[part 2 of 2: package /STLACompositions/Platform_Lin]
AUTOSAR XML (schema 00044)
package /STLACompositions/Platform_Lin  (continued)
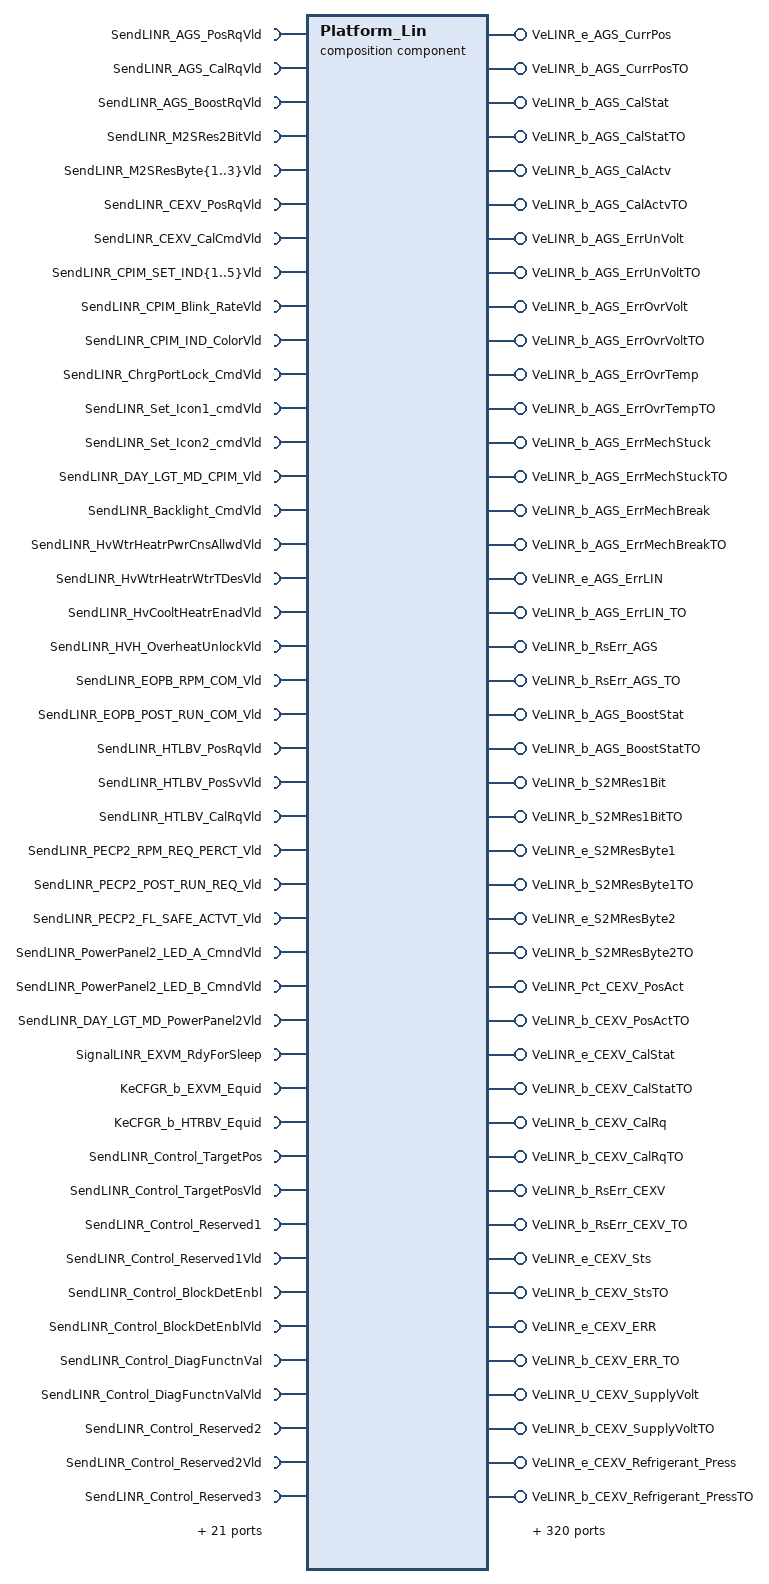
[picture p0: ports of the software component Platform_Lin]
  composition sw component type Platform_Lin: data-type-mapping=ADTtoIDTMapping  (continued)
    256 x provide port:
      VeLINR_e_AGS_CurrPos: nonqueued-sender-com-spec{data-element=VeLINR_e_AGS_CurrPos, init-value=VeLINR_e_AGS_CurrPosValue:0}, provided-interface=VeLINR_e_AGS_CurrPos
      VeLINR_b_AGS_CurrPosTO: nonqueued-sender-com-spec{data-element=VeLINR_b_AGS_CurrPosTO, init-value=VeLINR_b_AGS_CurrPosTOValue:0}, provided-interface=VeLINR_b_AGS_CurrPosTO
      VeLINR_b_AGS_CalStat: nonqueued-sender-com-spec{data-element=VeLINR_b_AGS_CalStat, init-value=VeLINR_b_AGS_CalStatValue:0}, provided-interface=VeLINR_b_AGS_CalStat
      VeLINR_b_AGS_CalStatTO: nonqueued-sender-com-spec{data-element=VeLINR_b_AGS_CalStatTO, init-value=VeLINR_b_AGS_CalStatTOValue:0}, provided-interface=VeLINR_b_AGS_CalStatTO
      VeLINR_b_AGS_CalActv: nonqueued-sender-com-spec{data-element=VeLINR_b_AGS_CalActv, init-value=VeLINR_b_AGS_CalActvValue:0}, provided-interface=VeLINR_b_AGS_CalActv
      VeLINR_b_AGS_CalActvTO: nonqueued-sender-com-spec{data-element=VeLINR_b_AGS_CalActvTO, init-value=VeLINR_b_AGS_CalActvTOValue:0}, provided-interface=VeLINR_b_AGS_CalActvTO
      VeLINR_b_AGS_ErrUnVolt: nonqueued-sender-com-spec{data-element=VeLINR_b_AGS_ErrUnVolt, init-value=VeLINR_b_AGS_ErrUnVoltValue:0}, provided-interface=VeLINR_b_AGS_ErrUnVolt
      VeLINR_b_AGS_ErrUnVoltTO: nonqueued-sender-com-spec{data-element=VeLINR_b_AGS_ErrUnVoltTO, init-value=VeLINR_b_AGS_ErrUnVoltTOValue:0}, provided-interface=VeLINR_b_AGS_ErrUnVoltTO
      VeLINR_b_AGS_ErrOvrVolt: nonqueued-sender-com-spec{data-element=VeLINR_b_AGS_ErrOvrVolt, init-value=VeLINR_b_AGS_ErrOvrVoltValue:0}, provided-interface=VeLINR_b_AGS_ErrOvrVolt
      VeLINR_b_AGS_ErrOvrVoltTO: nonqueued-sender-com-spec{data-element=VeLINR_b_AGS_ErrOvrVoltTO, init-value=VeLINR_b_AGS_ErrOvrVoltTOValue:0}, provided-interface=VeLINR_b_AGS_ErrOvrVoltTO
      VeLINR_b_AGS_ErrOvrTemp: nonqueued-sender-com-spec{data-element=VeLINR_b_AGS_ErrOvrTemp, init-value=VeLINR_b_AGS_ErrOvrTempValue:0}, provided-interface=VeLINR_b_AGS_ErrOvrTemp
      VeLINR_b_AGS_ErrOvrTempTO: nonqueued-sender-com-spec{data-element=VeLINR_b_AGS_ErrOvrTempTO, init-value=VeLINR_b_AGS_ErrOvrTempTOValue:0}, provided-interface=VeLINR_b_AGS_ErrOvrTempTO
      VeLINR_b_AGS_ErrMechStuck: nonqueued-sender-com-spec{data-element=VeLINR_b_AGS_ErrMechStuck, init-value=VeLINR_b_AGS_ErrMechStuckValue:0}, provided-interface=VeLINR_b_AGS_ErrMechStuck
      VeLINR_b_AGS_ErrMechStuckTO: nonqueued-sender-com-spec{data-element=VeLINR_b_AGS_ErrMechStuckTO, init-value=VeLINR_b_AGS_ErrMechStuckTOValue:0}, provided-interface=VeLINR_b_AGS_ErrMechStuckTO
      VeLINR_b_AGS_ErrMechBreak: nonqueued-sender-com-spec{data-element=VeLINR_b_AGS_ErrMechBreak, init-value=VeLINR_b_AGS_ErrMechBreakValue:0}, provided-interface=VeLINR_b_AGS_ErrMechBreak
      VeLINR_b_AGS_ErrMechBreakTO: nonqueued-sender-com-spec{data-element=VeLINR_b_AGS_ErrMechBreakTO, init-value=VeLINR_b_AGS_ErrMechBreakTOValue:0}, provided-interface=VeLINR_b_AGS_ErrMechBreakTO
      VeLINR_e_AGS_ErrLIN: nonqueued-sender-com-spec{data-element=VeLINR_e_AGS_ErrLIN, init-value=VeLINR_e_AGS_ErrLINValue:0}, provided-interface=VeLINR_e_AGS_ErrLIN
      VeLINR_b_AGS_ErrLIN_TO: nonqueued-sender-com-spec{data-element=VeLINR_b_AGS_ErrLIN_TO, init-value=VeLINR_b_AGS_ErrLIN_TOValue:0}, provided-interface=VeLINR_b_AGS_ErrLIN_TO
      VeLINR_b_RsErr_AGS: nonqueued-sender-com-spec{data-element=VeLINR_b_RsErr_AGS, init-value=VeLINR_b_RsErr_AGSValue:0}, provided-interface=VeLINR_b_RsErr_AGS
      VeLINR_b_RsErr_AGS_TO: nonqueued-sender-com-spec{data-element=VeLINR_b_RsErr_AGS_TO, init-value=VeLINR_b_RsErr_AGS_TOValue:0}, provided-interface=VeLINR_b_RsErr_AGS_TO
      VeLINR_b_AGS_BoostStat: nonqueued-sender-com-spec{data-element=VeLINR_b_AGS_BoostStat, init-value=VeLINR_b_AGS_BoostStatValue:0}, provided-interface=VeLINR_b_AGS_BoostStat
      VeLINR_b_AGS_BoostStatTO: nonqueued-sender-com-spec{data-element=VeLINR_b_AGS_BoostStatTO, init-value=VeLINR_b_AGS_BoostStatTOValue:0}, provided-interface=VeLINR_b_AGS_BoostStatTO
      VeLINR_b_S2MRes1Bit: nonqueued-sender-com-spec{data-element=VeLINR_b_S2MRes1Bit, init-value=VeLINR_b_S2MRes1BitValue:0}, provided-interface=VeLINR_b_S2MRes1Bit
      VeLINR_b_S2MRes1BitTO: nonqueued-sender-com-spec{data-element=VeLINR_b_S2MRes1BitTO, init-value=VeLINR_b_S2MRes1BitTOValue:0}, provided-interface=VeLINR_b_S2MRes1BitTO
      VeLINR_e_S2MResByte1: nonqueued-sender-com-spec{data-element=VeLINR_e_S2MResByte1, init-value=VeLINR_e_S2MResByte1Value:0}, provided-interface=VeLINR_e_S2MResByte1
      VeLINR_b_S2MResByte1TO: nonqueued-sender-com-spec{data-element=VeLINR_b_S2MResByte1TO, init-value=VeLINR_b_S2MResByte1TOValue:0}, provided-interface=VeLINR_b_S2MResByte1TO
      VeLINR_e_S2MResByte2: nonqueued-sender-com-spec{data-element=VeLINR_e_S2MResByte2, init-value=VeLINR_e_S2MResByte2Value:0}, provided-interface=VeLINR_e_S2MResByte2
      VeLINR_b_S2MResByte2TO: nonqueued-sender-com-spec{data-element=VeLINR_b_S2MResByte2TO, init-value=VeLINR_b_S2MResByte2TOValue:0}, provided-interface=VeLINR_b_S2MResByte2TO
      VeLINR_Pct_CEXV_PosAct: nonqueued-sender-com-spec{data-element=VeLINR_Pct_CEXV_PosAct, init-value=VeLINR_Pct_CEXV_PosActValue:0}, provided-interface=VeLINR_Pct_CEXV_PosAct
      VeLINR_b_CEXV_PosActTO: nonqueued-sender-com-spec{data-element=VeLINR_b_CEXV_PosActTO, init-value=VeLINR_b_CEXV_PosActTOValue:0}, provided-interface=VeLINR_b_CEXV_PosActTO
      VeLINR_e_CEXV_CalStat: nonqueued-sender-com-spec{data-element=VeLINR_e_CEXV_CalStat, init-value=VeLINR_e_CEXV_CalStatValue:0}, provided-interface=VeLINR_e_CEXV_CalStat
      VeLINR_b_CEXV_CalStatTO: nonqueued-sender-com-spec{data-element=VeLINR_b_CEXV_CalStatTO, init-value=VeLINR_b_CEXV_CalStatTOValue:0}, provided-interface=VeLINR_b_CEXV_CalStatTO
      VeLINR_b_CEXV_CalRq: nonqueued-sender-com-spec{data-element=VeLINR_b_CEXV_CalRq, init-value=VeLINR_b_CEXV_CalRqValue:0}, provided-interface=VeLINR_b_CEXV_CalRq
      VeLINR_b_CEXV_CalRqTO: nonqueued-sender-com-spec{data-element=VeLINR_b_CEXV_CalRqTO, init-value=VeLINR_b_CEXV_CalRqTOValue:0}, provided-interface=VeLINR_b_CEXV_CalRqTO
      VeLINR_b_RsErr_CEXV: nonqueued-sender-com-spec{data-element=VeLINR_b_RsErr_CEXV, init-value=VeLINR_b_RsErr_CEXVValue:0}, provided-interface=VeLINR_b_RsErr_CEXV
      VeLINR_b_RsErr_CEXV_TO: nonqueued-sender-com-spec{data-element=VeLINR_b_RsErr_CEXV_TO, init-value=VeLINR_b_RsErr_CEXV_TOValue:0}, provided-interface=VeLINR_b_RsErr_CEXV_TO
      VeLINR_e_CEXV_Sts: nonqueued-sender-com-spec{data-element=VeLINR_e_CEXV_Sts, init-value=VeLINR_e_CEXV_StsValue:0}, provided-interface=VeLINR_e_CEXV_Sts
      VeLINR_b_CEXV_StsTO: nonqueued-sender-com-spec{data-element=VeLINR_b_CEXV_StsTO, init-value=VeLINR_b_CEXV_StsTOValue:0}, provided-interface=VeLINR_b_CEXV_StsTO
      VeLINR_e_CEXV_ERR: nonqueued-sender-com-spec{data-element=VeLINR_e_CEXV_ERR, init-value=VeLINR_e_CEXV_ERRValue:0}, provided-interface=VeLINR_e_CEXV_ERR
      VeLINR_b_CEXV_ERR_TO: nonqueued-sender-com-spec{data-element=VeLINR_b_CEXV_ERR_TO, init-value=VeLINR_b_CEXV_ERR_TOValue:0}, provided-interface=VeLINR_b_CEXV_ERR_TO
      VeLINR_U_CEXV_SupplyVolt: nonqueued-sender-com-spec{data-element=VeLINR_U_CEXV_SupplyVolt, init-value=VeLINR_U_CEXV_SupplyVoltValue:0}, provided-interface=VeLINR_U_CEXV_SupplyVolt
      VeLINR_b_CEXV_SupplyVoltTO: nonqueued-sender-com-spec{data-element=VeLINR_b_CEXV_SupplyVoltTO, init-value=VeLINR_b_CEXV_SupplyVoltTOValue:0}, provided-interface=VeLINR_b_CEXV_SupplyVoltTO
      VeLINR_e_CEXV_Refrigerant_Press: nonqueued-sender-com-spec{data-element=VeLINR_e_CEXV_Refrigerant_Press, init-value=VeLINR_e_CEXV_Refrigerant_PressValue:1638.3}, provided-interface=VeLINR_e_CEXV_Refrigerant_Press
      VeLINR_b_CEXV_Refrigerant_PressTO: nonqueued-sender-com-spec{data-element=VeLINR_b_CEXV_Refrigerant_PressTO, init-value=VeLINR_b_CEXV_Refrigerant_PressTOValue:0}, provided-interface=VeLINR_b_CEXV_Refrigerant_PressTO
      VeLINR_T_CEXV_Board_Temp: nonqueued-sender-com-spec{data-element=VeLINR_T_CEXV_Board_Temp, init-value=VeLINR_T_CEXV_Board_TempValue:-40}, provided-interface=VeLINR_T_CEXV_Board_Temp
      VeLINR_b_CEXV_Board_TempTO: nonqueued-sender-com-spec{data-element=VeLINR_b_CEXV_Board_TempTO, init-value=VeLINR_b_CEXV_Board_TempTOValue:0}, provided-interface=VeLINR_b_CEXV_Board_TempTO
      VeLINR_e_CEXV_Refrigerant_Temp: nonqueued-sender-com-spec{data-element=VeLINR_e_CEXV_Refrigerant_Temp, init-value=VeLINR_e_CEXV_Refrigerant_TempValue:-40}, provided-interface=VeLINR_e_CEXV_Refrigerant_Temp
      VeLINR_b_CEXV_Refrigerant_TempTO: nonqueued-sender-com-spec{data-element=VeLINR_b_CEXV_Refrigerant_TempTO, init-value=VeLINR_b_CEXV_Refrigerant_TempTOValue:0}, provided-interface=VeLINR_b_CEXV_Refrigerant_TempTO
      VeLINR_e_Inlet_Temp1_DC: nonqueued-sender-com-spec{data-element=VeLINR_e_Inlet_Temp1_DC, init-value=VeLINR_e_Inlet_Temp1_DCValue:-40}, provided-interface=VeLINR_e_Inlet_Temp1_DC
      VeLINR_b_Inlet_Temp1_DC_TO: nonqueued-sender-com-spec{data-element=VeLINR_b_Inlet_Temp1_DC_TO, init-value=VeLINR_b_Inlet_Temp1_DC_TOValue:0}, provided-interface=VeLINR_b_Inlet_Temp1_DC_TO
      VeLINR_e_Inlet_Temp2_DC: nonqueued-sender-com-spec{data-element=VeLINR_e_Inlet_Temp2_DC, init-value=VeLINR_e_Inlet_Temp2_DCValue:-40}, provided-interface=VeLINR_e_Inlet_Temp2_DC
      VeLINR_b_Inlet_Temp2_DC_TO: nonqueued-sender-com-spec{data-element=VeLINR_b_Inlet_Temp2_DC_TO, init-value=VeLINR_b_Inlet_Temp2_DC_TOValue:0}, provided-interface=VeLINR_b_Inlet_Temp2_DC_TO
      VeLINR_e_CPIM_IND1_Fdbk: nonqueued-sender-com-spec{data-element=VeLINR_e_CPIM_IND1_Fdbk, init-value=VeLINR_e_CPIM_IND1_FdbkValue:0}, provided-interface=VeLINR_e_CPIM_IND1_Fdbk
      VeLINR_b_CPIM_IND1_FdbkTO: nonqueued-sender-com-spec{data-element=VeLINR_b_CPIM_IND1_FdbkTO, init-value=VeLINR_b_CPIM_IND1_FdbkTOValue:0}, provided-interface=VeLINR_b_CPIM_IND1_FdbkTO
      VeLINR_e_CPIM_IND2_Fdbk: nonqueued-sender-com-spec{data-element=VeLINR_e_CPIM_IND2_Fdbk, init-value=VeLINR_e_CPIM_IND2_FdbkValue:0}, provided-interface=VeLINR_e_CPIM_IND2_Fdbk
      VeLINR_b_CPIM_IND2_FdbkTO: nonqueued-sender-com-spec{data-element=VeLINR_b_CPIM_IND2_FdbkTO, init-value=VeLINR_b_CPIM_IND2_FdbkTOValue:0}, provided-interface=VeLINR_b_CPIM_IND2_FdbkTO
      VeLINR_e_CPIM_IND3_Fdbk: nonqueued-sender-com-spec{data-element=VeLINR_e_CPIM_IND3_Fdbk, init-value=VeLINR_e_CPIM_IND3_FdbkValue:0}, provided-interface=VeLINR_e_CPIM_IND3_Fdbk
      VeLINR_b_CPIM_IND3_FdbkTO: nonqueued-sender-com-spec{data-element=VeLINR_b_CPIM_IND3_FdbkTO, init-value=VeLINR_b_CPIM_IND3_FdbkTOValue:0}, provided-interface=VeLINR_b_CPIM_IND3_FdbkTO
      VeLINR_e_CPIM_IND4_Fdbk: nonqueued-sender-com-spec{data-element=VeLINR_e_CPIM_IND4_Fdbk, init-value=VeLINR_e_CPIM_IND4_FdbkValue:0}, provided-interface=VeLINR_e_CPIM_IND4_Fdbk
      VeLINR_b_CPIM_IND4_FdbkTO: nonqueued-sender-com-spec{data-element=VeLINR_b_CPIM_IND4_FdbkTO, init-value=VeLINR_b_CPIM_IND4_FdbkTOValue:0}, provided-interface=VeLINR_b_CPIM_IND4_FdbkTO
      VeLINR_e_CPIM_IND5_Fdbk: nonqueued-sender-com-spec{data-element=VeLINR_e_CPIM_IND5_Fdbk, init-value=VeLINR_e_CPIM_IND5_FdbkValue:0}, provided-interface=VeLINR_e_CPIM_IND5_Fdbk
      VeLINR_b_CPIM_IND5_FdbkTO: nonqueued-sender-com-spec{data-element=VeLINR_b_CPIM_IND5_FdbkTO, init-value=VeLINR_b_CPIM_IND5_FdbkTOValue:0}, provided-interface=VeLINR_b_CPIM_IND5_FdbkTO
      VeLINR_e_CPIM_IND_Color_Fdbk: nonqueued-sender-com-spec{data-element=VeLINR_e_CPIM_IND_Color_Fdbk, init-value=VeLINR_e_CPIM_IND_Color_FdbkValue:0}, provided-interface=VeLINR_e_CPIM_IND_Color_Fdbk
      VeLINR_b_CPIM_IND_Color_FdbkTO: nonqueued-sender-com-spec{data-element=VeLINR_b_CPIM_IND_Color_FdbkTO, init-value=VeLINR_b_CPIM_IND_Color_FdbkTOValue:0}, provided-interface=VeLINR_b_CPIM_IND_Color_FdbkTO
      VeLINR_e_CPIM_IND1_FailSts: nonqueued-sender-com-spec{data-element=VeLINR_e_CPIM_IND1_FailSts, init-value=VeLINR_e_CPIM_IND1_FailStsValue:0}, provided-interface=VeLINR_e_CPIM_IND1_FailSts
      VeLINR_b_CPIM_IND1_FailStsTO: nonqueued-sender-com-spec{data-element=VeLINR_b_CPIM_IND1_FailStsTO, init-value=VeLINR_b_CPIM_IND1_FailStsTOValue:0}, provided-interface=VeLINR_b_CPIM_IND1_FailStsTO
      VeLINR_e_CPIM_IND2_FailSts: nonqueued-sender-com-spec{data-element=VeLINR_e_CPIM_IND2_FailSts, init-value=VeLINR_e_CPIM_IND2_FailStsValue:0}, provided-interface=VeLINR_e_CPIM_IND2_FailSts
      VeLINR_b_CPIM_IND2_FailStsTO: nonqueued-sender-com-spec{data-element=VeLINR_b_CPIM_IND2_FailStsTO, init-value=VeLINR_b_CPIM_IND2_FailStsTOValue:0}, provided-interface=VeLINR_b_CPIM_IND2_FailStsTO
      VeLINR_e_CPIM_IND3_FailSts: nonqueued-sender-com-spec{data-element=VeLINR_e_CPIM_IND3_FailSts, init-value=VeLINR_e_CPIM_IND3_FailStsValue:0}, provided-interface=VeLINR_e_CPIM_IND3_FailSts
      VeLINR_b_CPIM_IND3_FailStsTO: nonqueued-sender-com-spec{data-element=VeLINR_b_CPIM_IND3_FailStsTO, init-value=VeLINR_b_CPIM_IND3_FailStsTOValue:0}, provided-interface=VeLINR_b_CPIM_IND3_FailStsTO
      VeLINR_e_CPIM_IND4_FailSts: nonqueued-sender-com-spec{data-element=VeLINR_e_CPIM_IND4_FailSts, init-value=VeLINR_e_CPIM_IND4_FailStsValue:0}, provided-interface=VeLINR_e_CPIM_IND4_FailSts
      VeLINR_b_CPIM_IND4_FailStsTO: nonqueued-sender-com-spec{data-element=VeLINR_b_CPIM_IND4_FailStsTO, init-value=VeLINR_b_CPIM_IND4_FailStsTOValue:0}, provided-interface=VeLINR_b_CPIM_IND4_FailStsTO
      VeLINR_e_CPIM_IND5_FailSts: nonqueued-sender-com-spec{data-element=VeLINR_e_CPIM_IND5_FailSts, init-value=VeLINR_e_CPIM_IND5_FailStsValue:0}, provided-interface=VeLINR_e_CPIM_IND5_FailSts
      VeLINR_b_CPIM_IND5_FailStsTO: nonqueued-sender-com-spec{data-element=VeLINR_b_CPIM_IND5_FailStsTO, init-value=VeLINR_b_CPIM_IND5_FailStsTOValue:0}, provided-interface=VeLINR_b_CPIM_IND5_FailStsTO
      VeLINR_b_CPIM_Undervoltage: nonqueued-sender-com-spec{data-element=VeLINR_b_CPIM_Undervoltage, init-value=VeLINR_b_CPIM_UndervoltageValue:0}, provided-interface=VeLINR_b_CPIM_Undervoltage
      VeLINR_b_CPIM_UndervoltageTO: nonqueued-sender-com-spec{data-element=VeLINR_b_CPIM_UndervoltageTO, init-value=VeLINR_b_CPIM_UndervoltageTOValue:0}, provided-interface=VeLINR_b_CPIM_UndervoltageTO
      VeLINR_b_CPIM_Over_Temperature: nonqueued-sender-com-spec{data-element=VeLINR_b_CPIM_Over_Temperature, init-value=VeLINR_b_CPIM_Over_TemperatureValue:0}, provided-interface=VeLINR_b_CPIM_Over_Temperature
      VeLINR_b_CPIM_Over_TemperatureTO: nonqueued-sender-com-spec{data-element=VeLINR_b_CPIM_Over_TemperatureTO, init-value=VeLINR_b_CPIM_Over_TemperatureTOValue:0}, provided-interface=VeLINR_b_CPIM_Over_TemperatureTO
      VeLINR_b_CPIM_LIN_Parity_Error: nonqueued-sender-com-spec{data-element=VeLINR_b_CPIM_LIN_Parity_Error, init-value=VeLINR_b_CPIM_LIN_Parity_ErrorValue:0}, provided-interface=VeLINR_b_CPIM_LIN_Parity_Error
      VeLINR_b_CPIM_LIN_Parity_ErrorTO: nonqueued-sender-com-spec{data-element=VeLINR_b_CPIM_LIN_Parity_ErrorTO, init-value=VeLINR_b_CPIM_LIN_Parity_ErrorTOValue:0}, provided-interface=VeLINR_b_CPIM_LIN_Parity_ErrorTO
      VeLINR_b_CPIM_LIN_ChecksumError: nonqueued-sender-com-spec{data-element=VeLINR_b_CPIM_LIN_ChecksumError, init-value=VeLINR_b_CPIM_LIN_ChecksumErrorValue:0}, provided-interface=VeLINR_b_CPIM_LIN_ChecksumError
      VeLINR_b_CPIM_LIN_ChecksumErrorTO: nonqueued-sender-com-spec{data-element=VeLINR_b_CPIM_LIN_ChecksumErrorTO, init-value=VeLINR_b_CPIM_LIN_ChecksumErrorTOValue:0}, provided-interface=VeLINR_b_CPIM_LIN_ChecksumErrorTO
      VeLINR_b_CPIM_LIN_Data_Error: nonqueued-sender-com-spec{data-element=VeLINR_b_CPIM_LIN_Data_Error, init-value=VeLINR_b_CPIM_LIN_Data_ErrorValue:0}, provided-interface=VeLINR_b_CPIM_LIN_Data_Error
      VeLINR_b_CPIM_LIN_Data_ErrorTO: nonqueued-sender-com-spec{data-element=VeLINR_b_CPIM_LIN_Data_ErrorTO, init-value=VeLINR_b_CPIM_LIN_Data_ErrorTOValue:0}, provided-interface=VeLINR_b_CPIM_LIN_Data_ErrorTO
      VeLINR_b_ChrgPortLock_Sts: nonqueued-sender-com-spec{data-element=VeLINR_b_ChrgPortLock_Sts, init-value=VeLINR_b_ChrgPortLock_StsValue:0}, provided-interface=VeLINR_b_ChrgPortLock_Sts
      VeLINR_b_ChrgPortLock_StsTO: nonqueued-sender-com-spec{data-element=VeLINR_b_ChrgPortLock_StsTO, init-value=VeLINR_b_ChrgPortLock_StsTOValue:0}, provided-interface=VeLINR_b_ChrgPortLock_StsTO
      VeLINR_b_ChrgPortButton_Sts: nonqueued-sender-com-spec{data-element=VeLINR_b_ChrgPortButton_Sts, init-value=VeLINR_b_ChrgPortButton_StsValue:0}, provided-interface=VeLINR_b_ChrgPortButton_Sts
      VeLINR_b_ChrgPortButton_StsTO: nonqueued-sender-com-spec{data-element=VeLINR_b_ChrgPortButton_StsTO, init-value=VeLINR_b_ChrgPortButton_StsTOValue:0}, provided-interface=VeLINR_b_ChrgPortButton_StsTO
      VeLINR_e_Ambient_Temp: nonqueued-sender-com-spec{data-element=VeLINR_e_Ambient_Temp, init-value=VeLINR_e_Ambient_TempValue:-40}, provided-interface=VeLINR_e_Ambient_Temp
      VeLINR_b_Ambient_TempTO: nonqueued-sender-com-spec{data-element=VeLINR_b_Ambient_TempTO, init-value=VeLINR_b_Ambient_TempTOValue:0}, provided-interface=VeLINR_b_Ambient_TempTO
      VeLINR_e_Chrg_Inlet_Temp: nonqueued-sender-com-spec{data-element=VeLINR_e_Chrg_Inlet_Temp, init-value=VeLINR_e_Chrg_Inlet_TempValue:-40}, provided-interface=VeLINR_e_Chrg_Inlet_Temp
      VeLINR_b_Chrg_Inlet_TempTO: nonqueued-sender-com-spec{data-element=VeLINR_b_Chrg_Inlet_TempTO, init-value=VeLINR_b_Chrg_Inlet_TempTOValue:0}, provided-interface=VeLINR_b_Chrg_Inlet_TempTO
      VeLINR_b_ResponseErrorStsCPIM: nonqueued-sender-com-spec{data-element=VeLINR_b_ResponseErrorStsCPIM, init-value=VeLINR_b_ResponseErrorStsCPIMValue:0}, provided-interface=VeLINR_b_ResponseErrorStsCPIM
      VeLINR_b_ResponseErrorStsCPIM_TO: nonqueued-sender-com-spec{data-element=VeLINR_b_ResponseErrorStsCPIM_TO, init-value=VeLINR_b_ResponseErrorStsCPIM_TOValue:0}, provided-interface=VeLINR_b_ResponseErrorStsCPIM_TO
      VeLINR_e_ChrgPortLock_FailSts: nonqueued-sender-com-spec{data-element=VeLINR_e_ChrgPortLock_FailSts, init-value=VeLINR_e_ChrgPortLock_FailStsValue:0}, provided-interface=VeLINR_e_ChrgPortLock_FailSts
      VeLINR_b_ChrgPortLock_FailStsTO: nonqueued-sender-com-spec{data-element=VeLINR_b_ChrgPortLock_FailStsTO, init-value=VeLINR_b_ChrgPortLock_FailStsTOValue:0}, provided-interface=VeLINR_b_ChrgPortLock_FailStsTO
      VeLINR_e_Icon1_Sts: nonqueued-sender-com-spec{data-element=VeLINR_e_Icon1_Sts, init-value=VeLINR_e_Icon1_StsValue:0}, provided-interface=VeLINR_e_Icon1_Sts
      VeLINR_b_Icon1_StsTO: nonqueued-sender-com-spec{data-element=VeLINR_b_Icon1_StsTO, init-value=VeLINR_b_Icon1_StsTOValue:0}, provided-interface=VeLINR_b_Icon1_StsTO
      VeLINR_b_Icon1_FailSts: nonqueued-sender-com-spec{data-element=VeLINR_b_Icon1_FailSts, init-value=VeLINR_b_Icon1_FailStsValue:0}, provided-interface=VeLINR_b_Icon1_FailSts
      VeLINR_b_Icon1_FailStsTO: nonqueued-sender-com-spec{data-element=VeLINR_b_Icon1_FailStsTO, init-value=VeLINR_b_Icon1_FailStsTOValue:0}, provided-interface=VeLINR_b_Icon1_FailStsTO
      VeLINR_e_Icon2_Sts: nonqueued-sender-com-spec{data-element=VeLINR_e_Icon2_Sts, init-value=VeLINR_e_Icon2_StsValue:0}, provided-interface=VeLINR_e_Icon2_Sts
      VeLINR_b_Icon2_StsTO: nonqueued-sender-com-spec{data-element=VeLINR_b_Icon2_StsTO, init-value=VeLINR_b_Icon2_StsTOValue:0}, provided-interface=VeLINR_b_Icon2_StsTO
      VeLINR_b_Icon2_FailSts: nonqueued-sender-com-spec{data-element=VeLINR_b_Icon2_FailSts, init-value=VeLINR_b_Icon2_FailStsValue:0}, provided-interface=VeLINR_b_Icon2_FailSts
      VeLINR_b_Icon2_FailStsTO: nonqueued-sender-com-spec{data-element=VeLINR_b_Icon2_FailStsTO, init-value=VeLINR_b_Icon2_FailStsTOValue:0}, provided-interface=VeLINR_b_Icon2_FailStsTO
      VeLINR_e_ChrgPortDoor_Sts: nonqueued-sender-com-spec{data-element=VeLINR_e_ChrgPortDoor_Sts, init-value=VeLINR_e_ChrgPortDoor_StsValue:0}, provided-interface=VeLINR_e_ChrgPortDoor_Sts
      VeLINR_b_ChrgPortDoor_StsTO: nonqueued-sender-com-spec{data-element=VeLINR_b_ChrgPortDoor_StsTO, init-value=VeLINR_b_ChrgPortDoor_StsTOValue:0}, provided-interface=VeLINR_b_ChrgPortDoor_StsTO
      VeLINR_e_HvCooltHeatrSts: nonqueued-sender-com-spec{data-element=VeLINR_e_HvCooltHeatrSts, init-value=VeLINR_e_HvCooltHeatrStsValue:0}, provided-interface=VeLINR_e_HvCooltHeatrSts
      VeLINR_b_HvCooltHeatrStsTO: nonqueued-sender-com-spec{data-element=VeLINR_b_HvCooltHeatrStsTO, init-value=VeLINR_b_HvCooltHeatrStsTOValue:0}, provided-interface=VeLINR_b_HvCooltHeatrStsTO
      VeLINR_e_ECH_InterlockStat: nonqueued-sender-com-spec{data-element=VeLINR_e_ECH_InterlockStat, init-value=VeLINR_e_ECH_InterlockStatValue:0}, provided-interface=VeLINR_e_ECH_InterlockStat
      VeLINR_b_ECH_InterlockStatTO: nonqueued-sender-com-spec{data-element=VeLINR_b_ECH_InterlockStatTO, init-value=VeLINR_b_ECH_InterlockStatTOValue:0}, provided-interface=VeLINR_b_ECH_InterlockStatTO
      VeLINR_e_Below_60V: nonqueued-sender-com-spec{data-element=VeLINR_e_Below_60V, init-value=VeLINR_e_Below_60VValue:3}, provided-interface=VeLINR_e_Below_60V
      VeLINR_b_Below_60V_TO: nonqueued-sender-com-spec{data-element=VeLINR_b_Below_60V_TO, init-value=VeLINR_b_Below_60V_TOValue:0}, provided-interface=VeLINR_b_Below_60V_TO
      VeLINR_T_HvCltWtrHtrWtrTInIntk: nonqueued-sender-com-spec{data-element=VeLINR_T_HvCltWtrHtrWtrTInIntk, init-value=VeLINR_T_HvCltWtrHtrWtrTInIntkValue:215}, provided-interface=VeLINR_T_HvCltWtrHtrWtrTInIntk
      VeLINR_b_HvCltWtrHtrWtrTInIntkTO: nonqueued-sender-com-spec{data-element=VeLINR_b_HvCltWtrHtrWtrTInIntkTO, init-value=VeLINR_b_HvCltWtrHtrWtrTInIntkTOValue:0}, provided-interface=VeLINR_b_HvCltWtrHtrWtrTInIntkTO
      VeLINR_T_HvWtrHeatrWtrT: nonqueued-sender-com-spec{data-element=VeLINR_T_HvWtrHeatrWtrT, init-value=VeLINR_T_HvWtrHeatrWtrTValue:215}, provided-interface=VeLINR_T_HvWtrHeatrWtrT
      VeLINR_b_HvWtrHeatrWtrT_TO: nonqueued-sender-com-spec{data-element=VeLINR_b_HvWtrHeatrWtrT_TO, init-value=VeLINR_b_HvWtrHeatrWtrT_TOValue:0}, provided-interface=VeLINR_b_HvWtrHeatrWtrT_TO
      VeLINR_I_HvCooltHeatrICns: nonqueued-sender-com-spec{data-element=VeLINR_I_HvCooltHeatrICns, init-value=VeLINR_I_HvCooltHeatrICnsValue:63.75}, provided-interface=VeLINR_I_HvCooltHeatrICns
      VeLINR_b_HvCooltHeatrICnsTO: nonqueued-sender-com-spec{data-element=VeLINR_b_HvCooltHeatrICnsTO, init-value=VeLINR_b_HvCooltHeatrICnsTOValue:0}, provided-interface=VeLINR_b_HvCooltHeatrICnsTO
      VeLINR_U_HvCooltHVmeas: nonqueued-sender-com-spec{data-element=VeLINR_U_HvCooltHVmeas, init-value=VeLINR_U_HvCooltHVmeasValue:1023}, provided-interface=VeLINR_U_HvCooltHVmeas
      VeLINR_b_HvCooltHVmeasTO: nonqueued-sender-com-spec{data-element=VeLINR_b_HvCooltHVmeasTO, init-value=VeLINR_b_HvCooltHVmeasTOValue:0}, provided-interface=VeLINR_b_HvCooltHVmeasTO
      VeLINR_P_HvHeatrPwrCns: nonqueued-sender-com-spec{data-element=VeLINR_P_HvHeatrPwrCns, init-value=VeLINR_P_HvHeatrPwrCnsValue:20460}, provided-interface=VeLINR_P_HvHeatrPwrCns
      VeLINR_b_HvHeatrPwrCnsTO: nonqueued-sender-com-spec{data-element=VeLINR_b_HvHeatrPwrCnsTO, init-value=VeLINR_b_HvHeatrPwrCnsTOValue:0}, provided-interface=VeLINR_b_HvHeatrPwrCnsTO
      VeLINR_P_HvHeatrPwrCnsDes: nonqueued-sender-com-spec{data-element=VeLINR_P_HvHeatrPwrCnsDes, init-value=VeLINR_P_HvHeatrPwrCnsDesValue:20460}, provided-interface=VeLINR_P_HvHeatrPwrCnsDes
      VeLINR_b_HvHeatrPwrCnsDesTO: nonqueued-sender-com-spec{data-element=VeLINR_b_HvHeatrPwrCnsDesTO, init-value=VeLINR_b_HvHeatrPwrCnsDesTOValue:0}, provided-interface=VeLINR_b_HvHeatrPwrCnsDesTO
      VeLINR_e_HVH_UnlockCounter: nonqueued-sender-com-spec{data-element=VeLINR_e_HVH_UnlockCounter, init-value=VeLINR_e_HVH_UnlockCounterValue:0}, provided-interface=VeLINR_e_HVH_UnlockCounter
      VeLINR_b_HVH_UnlockCounterTO: nonqueued-sender-com-spec{data-element=VeLINR_b_HVH_UnlockCounterTO, init-value=VeLINR_b_HVH_UnlockCounterTOValue:0}, provided-interface=VeLINR_b_HVH_UnlockCounterTO
      VeLINR_b_RsErr_ECH: nonqueued-sender-com-spec{data-element=VeLINR_b_RsErr_ECH, init-value=VeLINR_b_RsErr_ECHValue:0}, provided-interface=VeLINR_b_RsErr_ECH
      VeLINR_b_RsErr_ECH_TO: nonqueued-sender-com-spec{data-element=VeLINR_b_RsErr_ECH_TO, init-value=VeLINR_b_RsErr_ECH_TOValue:0}, provided-interface=VeLINR_b_RsErr_ECH_TO
      VeLINR_e_HvCltHtrWrnFltInCom: nonqueued-sender-com-spec{data-element=VeLINR_e_HvCltHtrWrnFltInCom, init-value=VeLINR_e_HvCltHtrWrnFltInComValue:3}, provided-interface=VeLINR_e_HvCltHtrWrnFltInCom
      VeLINR_b_HvCltHtrWrnFltInComTO: nonqueued-sender-com-spec{data-element=VeLINR_b_HvCltHtrWrnFltInComTO, init-value=VeLINR_b_HvCltHtrWrnFltInComTOValue:0}, provided-interface=VeLINR_b_HvCltHtrWrnFltInComTO
      VeLINR_e_HvCltHtrWrnHvOtOfRng: nonqueued-sender-com-spec{data-element=VeLINR_e_HvCltHtrWrnHvOtOfRng, init-value=VeLINR_e_HvCltHtrWrnHvOtOfRngValue:3}, provided-interface=VeLINR_e_HvCltHtrWrnHvOtOfRng
      VeLINR_b_HvCltHtrWrnHvOtOfRngTO: nonqueued-sender-com-spec{data-element=VeLINR_b_HvCltHtrWrnHvOtOfRngTO, init-value=VeLINR_b_HvCltHtrWrnHvOtOfRngTOValue:0}, provided-interface=VeLINR_b_HvCltHtrWrnHvOtOfRngTO
      VeLINR_e_HvCltHtrWrnULoOtOfRng: nonqueued-sender-com-spec{data-element=VeLINR_e_HvCltHtrWrnULoOtOfRng, init-value=VeLINR_e_HvCltHtrWrnULoOtOfRngValue:3}, provided-interface=VeLINR_e_HvCltHtrWrnULoOtOfRng
      VeLINR_b_HvCltHtrWrnULoOtOfRngTO: nonqueued-sender-com-spec{data-element=VeLINR_b_HvCltHtrWrnULoOtOfRngTO, init-value=VeLINR_b_HvCltHtrWrnULoOtOfRngTOValue:0}, provided-interface=VeLINR_b_HvCltHtrWrnULoOtOfRngTO
      VeLINR_e_HvCltHtrWrnCltTOtOfRng: nonqueued-sender-com-spec{data-element=VeLINR_e_HvCltHtrWrnCltTOtOfRng, init-value=VeLINR_e_HvCltHtrWrnCltTOtOfRngValue:3}, provided-interface=VeLINR_e_HvCltHtrWrnCltTOtOfRng
      VeLINR_b_HvCltHtrWrnCltTOtOfRngTO: nonqueued-sender-com-spec{data-element=VeLINR_b_HvCltHtrWrnCltTOtOfRngTO, init-value=VeLINR_b_HvCltHtrWrnCltTOtOfRngTOValue:0}, provided-interface=VeLINR_b_HvCltHtrWrnCltTOtOfRngTO
      VeLINR_e_HvCltHrPrtnSfTmpHwPrtn: nonqueued-sender-com-spec{data-element=VeLINR_e_HvCltHrPrtnSfTmpHwPrtn, init-value=VeLINR_e_HvCltHrPrtnSfTmpHwPrtnValue:3}, provided-interface=VeLINR_e_HvCltHrPrtnSfTmpHwPrtn
      VeLINR_b_HvCltHrPrtnSfTmpHwPrtnTO: nonqueued-sender-com-spec{data-element=VeLINR_b_HvCltHrPrtnSfTmpHwPrtnTO, init-value=VeLINR_b_HvCltHrPrtnSfTmpHwPrtnTOValue:0}, provided-interface=VeLINR_b_HvCltHrPrtnSfTmpHwPrtnTO
      VeLINR_e_HvCltHrPrtnSfTmpOvrhtg: nonqueued-sender-com-spec{data-element=VeLINR_e_HvCltHrPrtnSfTmpOvrhtg, init-value=VeLINR_e_HvCltHrPrtnSfTmpOvrhtgValue:3}, provided-interface=VeLINR_e_HvCltHrPrtnSfTmpOvrhtg
      VeLINR_b_HvCltHrPrtnSfTmpOvrhtgTO: nonqueued-sender-com-spec{data-element=VeLINR_b_HvCltHrPrtnSfTmpOvrhtgTO, init-value=VeLINR_b_HvCltHrPrtnSfTmpOvrhtgTOValue:0}, provided-interface=VeLINR_b_HvCltHrPrtnSfTmpOvrhtgTO
      VeLINR_e_HClHrSrFtClTInSnFlt: nonqueued-sender-com-spec{data-element=VeLINR_e_HClHrSrFtClTInSnFlt, init-value=VeLINR_e_HClHrSrFtClTInSnFltValue:3}, provided-interface=VeLINR_e_HClHrSrFtClTInSnFlt
      VeLINR_b_HClHrSrFtClTInSnFltTO: nonqueued-sender-com-spec{data-element=VeLINR_b_HClHrSrFtClTInSnFltTO, init-value=VeLINR_b_HClHrSrFtClTInSnFltTOValue:0}, provided-interface=VeLINR_b_HClHrSrFtClTInSnFltTO
      VeLINR_e_HClHrSrFtClTOtSnFlt: nonqueued-sender-com-spec{data-element=VeLINR_e_HClHrSrFtClTOtSnFlt, init-value=VeLINR_e_HClHrSrFtClTOtSnFltValue:3}, provided-interface=VeLINR_e_HClHrSrFtClTOtSnFlt
      VeLINR_b_HClHrSrFtClTOtSnFltTO: nonqueued-sender-com-spec{data-element=VeLINR_b_HClHrSrFtClTOtSnFltTO, init-value=VeLINR_b_HClHrSrFtClTOtSnFltTOValue:0}, provided-interface=VeLINR_b_HClHrSrFtClTOtSnFltTO
      VeLINR_e_HClHrSrFtTInMtrlSnFlt: nonqueued-sender-com-spec{data-element=VeLINR_e_HClHrSrFtTInMtrlSnFlt, init-value=VeLINR_e_HClHrSrFtTInMtrlSnFltValue:3}, provided-interface=VeLINR_e_HClHrSrFtTInMtrlSnFlt
      VeLINR_b_HClHrSrFtTInMtrlSnFltTO: nonqueued-sender-com-spec{data-element=VeLINR_b_HClHrSrFtTInMtrlSnFltTO, init-value=VeLINR_b_HClHrSrFtTInMtrlSnFltTOValue:0}, provided-interface=VeLINR_b_HClHrSrFtTInMtrlSnFltTO
      VeLINR_e_HClHrSrRqCrFrDrShOrOp: nonqueued-sender-com-spec{data-element=VeLINR_e_HClHrSrRqCrFrDrShOrOp, init-value=VeLINR_e_HClHrSrRqCrFrDrShOrOpValue:3}, provided-interface=VeLINR_e_HClHrSrRqCrFrDrShOrOp
      VeLINR_b_HClHrSrRqCrFrDrShOrOpTO: nonqueued-sender-com-spec{data-element=VeLINR_b_HClHrSrRqCrFrDrShOrOpTO, init-value=VeLINR_b_HClHrSrRqCrFrDrShOrOpTOValue:0}, provided-interface=VeLINR_b_HClHrSrRqCrFrDrShOrOpTO
      VeLINR_e_HClHrSrRqICnsOtOfRng: nonqueued-sender-com-spec{data-element=VeLINR_e_HClHrSrRqICnsOtOfRng, init-value=VeLINR_e_HClHrSrRqICnsOtOfRngValue:3}, provided-interface=VeLINR_e_HClHrSrRqICnsOtOfRng
      VeLINR_b_HClHrSrRqICnsOtOfRngTO: nonqueued-sender-com-spec{data-element=VeLINR_b_HClHrSrRqICnsOtOfRngTO, init-value=VeLINR_b_HClHrSrRqICnsOtOfRngTOValue:0}, provided-interface=VeLINR_b_HClHrSrRqICnsOtOfRngTO
      VeLINR_e_HClHrSrRqMemErr: nonqueued-sender-com-spec{data-element=VeLINR_e_HClHrSrRqMemErr, init-value=VeLINR_e_HClHrSrRqMemErrValue:3}, provided-interface=VeLINR_e_HClHrSrRqMemErr
      VeLINR_b_HClHrSrRqMemErrTO: nonqueued-sender-com-spec{data-element=VeLINR_b_HClHrSrRqMemErrTO, init-value=VeLINR_b_HClHrSrRqMemErrTOValue:0}, provided-interface=VeLINR_b_HClHrSrRqMemErrTO
      VeLINR_e_HClHrSrRqSrvRq: nonqueued-sender-com-spec{data-element=VeLINR_e_HClHrSrRqSrvRq, init-value=VeLINR_e_HClHrSrRqSrvRqValue:3}, provided-interface=VeLINR_e_HClHrSrRqSrvRq
      VeLINR_b_HClHrSrRqSrvRqTO: nonqueued-sender-com-spec{data-element=VeLINR_b_HClHrSrRqSrvRqTO, init-value=VeLINR_b_HClHrSrRqSrvRqTOValue:0}, provided-interface=VeLINR_b_HClHrSrRqSrvRqTO
      VeLINR_e_EOPB_RPM_TGT: nonqueued-sender-com-spec{data-element=VeLINR_e_EOPB_RPM_TGT, init-value=VeLINR_e_EOPB_RPM_TGTValue:6120}, provided-interface=VeLINR_e_EOPB_RPM_TGT
      VeLINR_b_EOPB_RPM_TGT_TO: nonqueued-sender-com-spec{data-element=VeLINR_b_EOPB_RPM_TGT_TO, init-value=VeLINR_b_EOPB_RPM_TGT_TOValue:0}, provided-interface=VeLINR_b_EOPB_RPM_TGT_TO
      VeLINR_e_EOPB_RPM_ACTL: nonqueued-sender-com-spec{data-element=VeLINR_e_EOPB_RPM_ACTL, init-value=VeLINR_e_EOPB_RPM_ACTLValue:6120}, provided-interface=VeLINR_e_EOPB_RPM_ACTL
      VeLINR_b_EOPB_RPM_ACTL_TO: nonqueued-sender-com-spec{data-element=VeLINR_b_EOPB_RPM_ACTL_TO, init-value=VeLINR_b_EOPB_RPM_ACTL_TOValue:0}, provided-interface=VeLINR_b_EOPB_RPM_ACTL_TO
      VeLINR_U_EOPB_VLTG: nonqueued-sender-com-spec{data-element=VeLINR_U_EOPB_VLTG, init-value=VeLINR_U_EOPB_VLTGValue:25.5}, provided-interface=VeLINR_U_EOPB_VLTG
      VeLINR_b_EOPB_VLTG_TO: nonqueued-sender-com-spec{data-element=VeLINR_b_EOPB_VLTG_TO, init-value=VeLINR_b_EOPB_VLTG_TOValue:0}, provided-interface=VeLINR_b_EOPB_VLTG_TO
      VeLINR_T_EOPB_TEMP: nonqueued-sender-com-spec{data-element=VeLINR_T_EOPB_TEMP, init-value=VeLINR_T_EOPB_TEMPValue:205}, provided-interface=VeLINR_T_EOPB_TEMP
      VeLINR_b_EOPB_TEMP_TO: nonqueued-sender-com-spec{data-element=VeLINR_b_EOPB_TEMP_TO, init-value=VeLINR_b_EOPB_TEMP_TOValue:0}, provided-interface=VeLINR_b_EOPB_TEMP_TO
      VeLINR_I_EOPB_CURR: nonqueued-sender-com-spec{data-element=VeLINR_I_EOPB_CURR, init-value=VeLINR_I_EOPB_CURRValue:51}, provided-interface=VeLINR_I_EOPB_CURR
      VeLINR_b_EOPB_CURR_TO: nonqueued-sender-com-spec{data-element=VeLINR_b_EOPB_CURR_TO, init-value=VeLINR_b_EOPB_CURR_TOValue:0}, provided-interface=VeLINR_b_EOPB_CURR_TO
      VeLINR_e_EOPB_LOW_TMP_STAT: nonqueued-sender-com-spec{data-element=VeLINR_e_EOPB_LOW_TMP_STAT, init-value=VeLINR_e_EOPB_LOW_TMP_STATValue:3}, provided-interface=VeLINR_e_EOPB_LOW_TMP_STAT
      VeLINR_b_EOPB_LOW_TMP_STAT_TO: nonqueued-sender-com-spec{data-element=VeLINR_b_EOPB_LOW_TMP_STAT_TO, init-value=VeLINR_b_EOPB_LOW_TMP_STAT_TOValue:0}, provided-interface=VeLINR_b_EOPB_LOW_TMP_STAT_TO
      VeLINR_e_EOPB_MONTRNG_RPM: nonqueued-sender-com-spec{data-element=VeLINR_e_EOPB_MONTRNG_RPM, init-value=VeLINR_e_EOPB_MONTRNG_RPMValue:3}, provided-interface=VeLINR_e_EOPB_MONTRNG_RPM
      VeLINR_b_EOPB_MONTRNG_RPM_TO: nonqueued-sender-com-spec{data-element=VeLINR_b_EOPB_MONTRNG_RPM_TO, init-value=VeLINR_b_EOPB_MONTRNG_RPM_TOValue:0}, provided-interface=VeLINR_b_EOPB_MONTRNG_RPM_TO
      VeLINR_e_EOPB_LMP_HM_AN_ON: nonqueued-sender-com-spec{data-element=VeLINR_e_EOPB_LMP_HM_AN_ON, init-value=VeLINR_e_EOPB_LMP_HM_AN_ONValue:3}, provided-interface=VeLINR_e_EOPB_LMP_HM_AN_ON
      VeLINR_b_EOPB_LMP_HM_AN_ON_TO: nonqueued-sender-com-spec{data-element=VeLINR_b_EOPB_LMP_HM_AN_ON_TO, init-value=VeLINR_b_EOPB_LMP_HM_AN_ON_TOValue:0}, provided-interface=VeLINR_b_EOPB_LMP_HM_AN_ON_TO
      VeLINR_e_EOPB_OV_TMP_ER: nonqueued-sender-com-spec{data-element=VeLINR_e_EOPB_OV_TMP_ER, init-value=VeLINR_e_EOPB_OV_TMP_ERValue:3}, provided-interface=VeLINR_e_EOPB_OV_TMP_ER
      VeLINR_b_EOPB_OV_TMP_ER_TO: nonqueued-sender-com-spec{data-element=VeLINR_b_EOPB_OV_TMP_ER_TO, init-value=VeLINR_b_EOPB_OV_TMP_ER_TOValue:0}, provided-interface=VeLINR_b_EOPB_OV_TMP_ER_TO
      VeLINR_e_EOPB_OV_CUR_ER: nonqueued-sender-com-spec{data-element=VeLINR_e_EOPB_OV_CUR_ER, init-value=VeLINR_e_EOPB_OV_CUR_ERValue:3}, provided-interface=VeLINR_e_EOPB_OV_CUR_ER
      VeLINR_b_EOPB_OV_CUR_ER_TO: nonqueued-sender-com-spec{data-element=VeLINR_b_EOPB_OV_CUR_ER_TO, init-value=VeLINR_b_EOPB_OV_CUR_ER_TOValue:0}, provided-interface=VeLINR_b_EOPB_OV_CUR_ER_TO
      VeLINR_e_EOPB_DR_RN_ER: nonqueued-sender-com-spec{data-element=VeLINR_e_EOPB_DR_RN_ER, init-value=VeLINR_e_EOPB_DR_RN_ERValue:3}, provided-interface=VeLINR_e_EOPB_DR_RN_ER
      VeLINR_b_EOPB_DR_RN_ER_TO: nonqueued-sender-com-spec{data-element=VeLINR_b_EOPB_DR_RN_ER_TO, init-value=VeLINR_b_EOPB_DR_RN_ER_TOValue:0}, provided-interface=VeLINR_b_EOPB_DR_RN_ER_TO
      VeLINR_e_EOPB_VLTG_ER: nonqueued-sender-com-spec{data-element=VeLINR_e_EOPB_VLTG_ER, init-value=VeLINR_e_EOPB_VLTG_ERValue:3}, provided-interface=VeLINR_e_EOPB_VLTG_ER
      VeLINR_b_EOPB_VLTG_ER_TO: nonqueued-sender-com-spec{data-element=VeLINR_b_EOPB_VLTG_ER_TO, init-value=VeLINR_b_EOPB_VLTG_ER_TOValue:0}, provided-interface=VeLINR_b_EOPB_VLTG_ER_TO
      VeLINR_e_EOPB_Stall_Event: nonqueued-sender-com-spec{data-element=VeLINR_e_EOPB_Stall_Event, init-value=VeLINR_e_EOPB_Stall_EventValue:3}, provided-interface=VeLINR_e_EOPB_Stall_Event
      VeLINR_b_EOPB_Stall_EventTO: nonqueued-sender-com-spec{data-element=VeLINR_b_EOPB_Stall_EventTO, init-value=VeLINR_b_EOPB_Stall_EventTOValue:0}, provided-interface=VeLINR_b_EOPB_Stall_EventTO
      VeLINR_e_EOPB_POST_RUN_STAT: nonqueued-sender-com-spec{data-element=VeLINR_e_EOPB_POST_RUN_STAT, init-value=VeLINR_e_EOPB_POST_RUN_STATValue:7}, provided-interface=VeLINR_e_EOPB_POST_RUN_STAT
      VeLINR_b_EOPB_POST_RUN_STAT_TO: nonqueued-sender-com-spec{data-element=VeLINR_b_EOPB_POST_RUN_STAT_TO, init-value=VeLINR_b_EOPB_POST_RUN_STAT_TOValue:0}, provided-interface=VeLINR_b_EOPB_POST_RUN_STAT_TO
      VeLINR_b_RsErr_EOPB: nonqueued-sender-com-spec{data-element=VeLINR_b_RsErr_EOPB, init-value=VeLINR_b_RsErr_EOPBValue:0}, provided-interface=VeLINR_b_RsErr_EOPB
      VeLINR_b_RsErr_EOPB_TO: nonqueued-sender-com-spec{data-element=VeLINR_b_RsErr_EOPB_TO, init-value=VeLINR_b_RsErr_EOPB_TOValue:0}, provided-interface=VeLINR_b_RsErr_EOPB_TO
      VeLINR_T_EOPB_OIL_TEMP: nonqueued-sender-com-spec{data-element=VeLINR_T_EOPB_OIL_TEMP, init-value=VeLINR_T_EOPB_OIL_TEMPValue:205}, provided-interface=VeLINR_T_EOPB_OIL_TEMP
      VeLINR_b_EOPB_OIL_TEMP_TO: nonqueued-sender-com-spec{data-element=VeLINR_b_EOPB_OIL_TEMP_TO, init-value=VeLINR_b_EOPB_OIL_TEMP_TOValue:0}, provided-interface=VeLINR_b_EOPB_OIL_TEMP_TO
      VeLINR_y_EOPB_HW_VER: nonqueued-sender-com-spec{data-element=VeLINR_y_EOPB_HW_VER, init-value=VeLINR_y_EOPB_HW_VERValue:255}, provided-interface=VeLINR_y_EOPB_HW_VER
      VeLINR_b_EOPB_HW_VER_TO: nonqueued-sender-com-spec{data-element=VeLINR_b_EOPB_HW_VER_TO, init-value=VeLINR_b_EOPB_HW_VER_TOValue:0}, provided-interface=VeLINR_b_EOPB_HW_VER_TO
      VeLINR_y_EOPB_SW_VER: nonqueued-sender-com-spec{data-element=VeLINR_y_EOPB_SW_VER, init-value=VeLINR_y_EOPB_SW_VERValue:255}, provided-interface=VeLINR_y_EOPB_SW_VER
      VeLINR_b_EOPB_SW_VER_TO: nonqueued-sender-com-spec{data-element=VeLINR_b_EOPB_SW_VER_TO, init-value=VeLINR_b_EOPB_SW_VER_TOValue:0}, provided-interface=VeLINR_b_EOPB_SW_VER_TO
      VeLINR_Pct_HTLBV_PosAct: nonqueued-sender-com-spec{data-element=VeLINR_Pct_HTLBV_PosAct, init-value=VeLINR_Pct_HTLBV_PosActValue:0}, provided-interface=VeLINR_Pct_HTLBV_PosAct
      VeLINR_b_HTLBV_PosActTO: nonqueued-sender-com-spec{data-element=VeLINR_b_HTLBV_PosActTO, init-value=VeLINR_b_HTLBV_PosActTOValue:0}, provided-interface=VeLINR_b_HTLBV_PosActTO
      VeLINR_e_HTLBV_ERR: nonqueued-sender-com-spec{data-element=VeLINR_e_HTLBV_ERR, init-value=VeLINR_e_HTLBV_ERRValue:0}, provided-interface=VeLINR_e_HTLBV_ERR
      VeLINR_b_HTLBV_ERR_TO: nonqueued-sender-com-spec{data-element=VeLINR_b_HTLBV_ERR_TO, init-value=VeLINR_b_HTLBV_ERR_TOValue:0}, provided-interface=VeLINR_b_HTLBV_ERR_TO
      VeLINR_U_HTLBV_MotorVolt: nonqueued-sender-com-spec{data-element=VeLINR_U_HTLBV_MotorVolt, init-value=VeLINR_U_HTLBV_MotorVoltValue:0}, provided-interface=VeLINR_U_HTLBV_MotorVolt
      VeLINR_b_HTLBV_MotorVoltTO: nonqueued-sender-com-spec{data-element=VeLINR_b_HTLBV_MotorVoltTO, init-value=VeLINR_b_HTLBV_MotorVoltTOValue:0}, provided-interface=VeLINR_b_HTLBV_MotorVoltTO
      VeLINR_e_HTLBV_Sts: nonqueued-sender-com-spec{data-element=VeLINR_e_HTLBV_Sts, init-value=VeLINR_e_HTLBV_StsValue:0}, provided-interface=VeLINR_e_HTLBV_Sts
      VeLINR_b_HTLBV_StsTO: nonqueued-sender-com-spec{data-element=VeLINR_b_HTLBV_StsTO, init-value=VeLINR_b_HTLBV_StsTOValue:0}, provided-interface=VeLINR_b_HTLBV_StsTO
      VeLINR_b_RsErr_HTLBV: nonqueued-sender-com-spec{data-element=VeLINR_b_RsErr_HTLBV, init-value=VeLINR_b_RsErr_HTLBVValue:0}, provided-interface=VeLINR_b_RsErr_HTLBV
      VeLINR_b_RsErr_HTLBV_TO: nonqueued-sender-com-spec{data-element=VeLINR_b_RsErr_HTLBV_TO, init-value=VeLINR_b_RsErr_HTLBV_TOValue:0}, provided-interface=VeLINR_b_RsErr_HTLBV_TO
      VeLINR_e_HTLBV_CalStat: nonqueued-sender-com-spec{data-element=VeLINR_e_HTLBV_CalStat, init-value=VeLINR_e_HTLBV_CalStatValue:0}, provided-interface=VeLINR_e_HTLBV_CalStat
      VeLINR_b_HTLBV_CalStatTO: nonqueued-sender-com-spec{data-element=VeLINR_b_HTLBV_CalStatTO, init-value=VeLINR_b_HTLBV_CalStatTOValue:0}, provided-interface=VeLINR_b_HTLBV_CalStatTO
      VeLINR_Pct_PECP2_RPM_TGT_PERCT: nonqueued-sender-com-spec{data-element=VeLINR_Pct_PECP2_RPM_TGT_PERCT, init-value=VeLINR_Pct_PECP2_RPM_TGT_PERCTValue:100.3935}, provided-interface=VeLINR_Pct_PECP2_RPM_TGT_PERCT
      VeLINR_b_PECP2_RPM_TGT_PERCT_TO: nonqueued-sender-com-spec{data-element=VeLINR_b_PECP2_RPM_TGT_PERCT_TO, init-value=VeLINR_b_PECP2_RPM_TGT_PERCT_TOValue:0}, provided-interface=VeLINR_b_PECP2_RPM_TGT_PERCT_TO
      VeLINR_Pct_PECP2_RPM_ACTL_PERCT: nonqueued-sender-com-spec{data-element=VeLINR_Pct_PECP2_RPM_ACTL_PERCT, init-value=VeLINR_Pct_PECP2_RPM_ACTL_PERCTValue:100.3935}, provided-interface=VeLINR_Pct_PECP2_RPM_ACTL_PERCT
      VeLINR_b_PECP2_RPM_ACTL_PERCT_TO: nonqueued-sender-com-spec{data-element=VeLINR_b_PECP2_RPM_ACTL_PERCT_TO, init-value=VeLINR_b_PECP2_RPM_ACTL_PERCT_TOValue:0}, provided-interface=VeLINR_b_PECP2_RPM_ACTL_PERCT_TO
      VeLINR_U_PECP2_VLTG: nonqueued-sender-com-spec{data-element=VeLINR_U_PECP2_VLTG, init-value=VeLINR_U_PECP2_VLTGValue:25.5}, provided-interface=VeLINR_U_PECP2_VLTG
      VeLINR_b_PECP2_VLTG_TO: nonqueued-sender-com-spec{data-element=VeLINR_b_PECP2_VLTG_TO, init-value=VeLINR_b_PECP2_VLTG_TOValue:0}, provided-interface=VeLINR_b_PECP2_VLTG_TO
      VeLINR_T_PECP2_TEMP: nonqueued-sender-com-spec{data-element=VeLINR_T_PECP2_TEMP, init-value=VeLINR_T_PECP2_TEMPValue:205}, provided-interface=VeLINR_T_PECP2_TEMP
      VeLINR_b_PECP2_TEMP_TO: nonqueued-sender-com-spec{data-element=VeLINR_b_PECP2_TEMP_TO, init-value=VeLINR_b_PECP2_TEMP_TOValue:0}, provided-interface=VeLINR_b_PECP2_TEMP_TO
      VeLINR_I_PECP2_CURR: nonqueued-sender-com-spec{data-element=VeLINR_I_PECP2_CURR, init-value=VeLINR_I_PECP2_CURRValue:51}, provided-interface=VeLINR_I_PECP2_CURR
      VeLINR_b_PECP2_CURR_TO: nonqueued-sender-com-spec{data-element=VeLINR_b_PECP2_CURR_TO, init-value=VeLINR_b_PECP2_CURR_TOValue:0}, provided-interface=VeLINR_b_PECP2_CURR_TO
      VeLINR_e_PECP2_FL_SAFE_ACTVTD: nonqueued-sender-com-spec{data-element=VeLINR_e_PECP2_FL_SAFE_ACTVTD, init-value=VeLINR_e_PECP2_FL_SAFE_ACTVTDValue:3}, provided-interface=VeLINR_e_PECP2_FL_SAFE_ACTVTD
      VeLINR_b_PECP2_FL_SAFE_ACTVTD_TO: nonqueued-sender-com-spec{data-element=VeLINR_b_PECP2_FL_SAFE_ACTVTD_TO, init-value=VeLINR_b_PECP2_FL_SAFE_ACTVTD_TOValue:0}, provided-interface=VeLINR_b_PECP2_FL_SAFE_ACTVTD_TO
      VeLINR_e_PECP2_LMP_HM_AN_ON: nonqueued-sender-com-spec{data-element=VeLINR_e_PECP2_LMP_HM_AN_ON, init-value=VeLINR_e_PECP2_LMP_HM_AN_ONValue:3}, provided-interface=VeLINR_e_PECP2_LMP_HM_AN_ON
      VeLINR_b_PECP2_LMP_HM_AN_ON_TO: nonqueued-sender-com-spec{data-element=VeLINR_b_PECP2_LMP_HM_AN_ON_TO, init-value=VeLINR_b_PECP2_LMP_HM_AN_ON_TOValue:0}, provided-interface=VeLINR_b_PECP2_LMP_HM_AN_ON_TO
      VeLINR_e_PECP2_AIR_PRE_ERR: nonqueued-sender-com-spec{data-element=VeLINR_e_PECP2_AIR_PRE_ERR, init-value=VeLINR_e_PECP2_AIR_PRE_ERRValue:3}, provided-interface=VeLINR_e_PECP2_AIR_PRE_ERR
      VeLINR_b_PECP2_AIR_PRE_ERR_TO: nonqueued-sender-com-spec{data-element=VeLINR_b_PECP2_AIR_PRE_ERR_TO, init-value=VeLINR_b_PECP2_AIR_PRE_ERR_TOValue:0}, provided-interface=VeLINR_b_PECP2_AIR_PRE_ERR_TO
      VeLINR_e_PECP2_OVR_TMP_ERR: nonqueued-sender-com-spec{data-element=VeLINR_e_PECP2_OVR_TMP_ERR, init-value=VeLINR_e_PECP2_OVR_TMP_ERRValue:3}, provided-interface=VeLINR_e_PECP2_OVR_TMP_ERR
      VeLINR_b_PECP2_OVR_TMP_ERR_TO: nonqueued-sender-com-spec{data-element=VeLINR_b_PECP2_OVR_TMP_ERR_TO, init-value=VeLINR_b_PECP2_OVR_TMP_ERR_TOValue:0}, provided-interface=VeLINR_b_PECP2_OVR_TMP_ERR_TO
      VeLINR_e_PECP2_OVR_CUR_ERR: nonqueued-sender-com-spec{data-element=VeLINR_e_PECP2_OVR_CUR_ERR, init-value=VeLINR_e_PECP2_OVR_CUR_ERRValue:3}, provided-interface=VeLINR_e_PECP2_OVR_CUR_ERR
      VeLINR_b_PECP2_OVR_CUR_ERR_TO: nonqueued-sender-com-spec{data-element=VeLINR_b_PECP2_OVR_CUR_ERR_TO, init-value=VeLINR_b_PECP2_OVR_CUR_ERR_TOValue:0}, provided-interface=VeLINR_b_PECP2_OVR_CUR_ERR_TO
      VeLINR_e_PECP2_DR_RN_ERR: nonqueued-sender-com-spec{data-element=VeLINR_e_PECP2_DR_RN_ERR, init-value=VeLINR_e_PECP2_DR_RN_ERRValue:3}, provided-interface=VeLINR_e_PECP2_DR_RN_ERR
      VeLINR_b_PECP2_DR_RN_ERR_TO: nonqueued-sender-com-spec{data-element=VeLINR_b_PECP2_DR_RN_ERR_TO, init-value=VeLINR_b_PECP2_DR_RN_ERR_TOValue:0}, provided-interface=VeLINR_b_PECP2_DR_RN_ERR_TO
      VeLINR_e_PECP2_VLTG_ERR: nonqueued-sender-com-spec{data-element=VeLINR_e_PECP2_VLTG_ERR, init-value=VeLINR_e_PECP2_VLTG_ERRValue:3}, provided-interface=VeLINR_e_PECP2_VLTG_ERR
      VeLINR_b_PECP2_VLTG_ERR_TO: nonqueued-sender-com-spec{data-element=VeLINR_b_PECP2_VLTG_ERR_TO, init-value=VeLINR_b_PECP2_VLTG_ERR_TOValue:0}, provided-interface=VeLINR_b_PECP2_VLTG_ERR_TO
      VeLINR_e_PECP2_DBLK_ACTV: nonqueued-sender-com-spec{data-element=VeLINR_e_PECP2_DBLK_ACTV, init-value=VeLINR_e_PECP2_DBLK_ACTVValue:3}, provided-interface=VeLINR_e_PECP2_DBLK_ACTV
      VeLINR_b_PECP2_DBLK_ACTV_TO: nonqueued-sender-com-spec{data-element=VeLINR_b_PECP2_DBLK_ACTV_TO, init-value=VeLINR_b_PECP2_DBLK_ACTV_TOValue:0}, provided-interface=VeLINR_b_PECP2_DBLK_ACTV_TO
      VeLINR_e_PECP2_MONTRNG_RPM: nonqueued-sender-com-spec{data-element=VeLINR_e_PECP2_MONTRNG_RPM, init-value=VeLINR_e_PECP2_MONTRNG_RPMValue:3}, provided-interface=VeLINR_e_PECP2_MONTRNG_RPM
      VeLINR_b_PECP2_MONTRNG_RPM_TO: nonqueued-sender-com-spec{data-element=VeLINR_b_PECP2_MONTRNG_RPM_TO, init-value=VeLINR_b_PECP2_MONTRNG_RPM_TOValue:0}, provided-interface=VeLINR_b_PECP2_MONTRNG_RPM_TO
      VeLINR_e_PECP2_NODE_ERR: nonqueued-sender-com-spec{data-element=VeLINR_e_PECP2_NODE_ERR, init-value=VeLINR_e_PECP2_NODE_ERRValue:3}, provided-interface=VeLINR_e_PECP2_NODE_ERR
      VeLINR_b_PECP2_NODE_ERR_TO: nonqueued-sender-com-spec{data-element=VeLINR_b_PECP2_NODE_ERR_TO, init-value=VeLINR_b_PECP2_NODE_ERR_TOValue:0}, provided-interface=VeLINR_b_PECP2_NODE_ERR_TO
      VeLINR_e_PECP2_POST_RUN_STAT: nonqueued-sender-com-spec{data-element=VeLINR_e_PECP2_POST_RUN_STAT, init-value=VeLINR_e_PECP2_POST_RUN_STATValue:7}, provided-interface=VeLINR_e_PECP2_POST_RUN_STAT
      VeLINR_b_PECP2_POST_RUN_STAT_TO: nonqueued-sender-com-spec{data-element=VeLINR_b_PECP2_POST_RUN_STAT_TO, init-value=VeLINR_b_PECP2_POST_RUN_STAT_TOValue:0}, provided-interface=VeLINR_b_PECP2_POST_RUN_STAT_TO
      VeLINR_b_RsErr_PECP2_PUMP: nonqueued-sender-com-spec{data-element=VeLINR_b_RsErr_PECP2_PUMP, init-value=VeLINR_b_RsErr_PECP2_PUMPValue:0}, provided-interface=VeLINR_b_RsErr_PECP2_PUMP
      VeLINR_b_RsErr_PECP2_PUMP_TO: nonqueued-sender-com-spec{data-element=VeLINR_b_RsErr_PECP2_PUMP_TO, init-value=VeLINR_b_RsErr_PECP2_PUMP_TOValue:0}, provided-interface=VeLINR_b_RsErr_PECP2_PUMP_TO
      VeLINR_y_PECP2_VERSION: nonqueued-sender-com-spec{data-element=VeLINR_y_PECP2_VERSION, init-value=VeLINR_y_PECP2_VERSIONValue:255}, provided-interface=VeLINR_y_PECP2_VERSION
      VeLINR_b_PECP2_VERSION_TO: nonqueued-sender-com-spec{data-element=VeLINR_b_PECP2_VERSION_TO, init-value=VeLINR_b_PECP2_VERSION_TOValue:0}, provided-interface=VeLINR_b_PECP2_VERSION_TO
      VeLINR_e_PECP2_SUPPLIER: nonqueued-sender-com-spec{data-element=VeLINR_e_PECP2_SUPPLIER, init-value=VeLINR_e_PECP2_SUPPLIERValue:0}, provided-interface=VeLINR_e_PECP2_SUPPLIER
      VeLINR_b_PECP2_SUPPLIER_TO: nonqueued-sender-com-spec{data-element=VeLINR_b_PECP2_SUPPLIER_TO, init-value=VeLINR_b_PECP2_SUPPLIER_TOValue:0}, provided-interface=VeLINR_b_PECP2_SUPPLIER_TO
      VeLINR_b_PowerPanel2ButtonState: nonqueued-sender-com-spec{data-element=VeLINR_b_PowerPanel2ButtonState, init-value=VeLINR_b_PowerPanel2ButtonStateValue:0}, provided-interface=VeLINR_b_PowerPanel2ButtonState
      VeLINR_b_PowerPanel2ButtonStateTO: nonqueued-sender-com-spec{data-element=VeLINR_b_PowerPanel2ButtonStateTO, init-value=VeLINR_b_PowerPanel2ButtonStateTOValue:0}, provided-interface=VeLINR_b_PowerPanel2ButtonStateTO
      VeLINR_b_PwrPanel2LidSwtSts120A: nonqueued-sender-com-spec{data-element=VeLINR_b_PwrPanel2LidSwtSts120A, init-value=VeLINR_b_PwrPanel2LidSwtSts120AValue:0}, provided-interface=VeLINR_b_PwrPanel2LidSwtSts120A
      VeLINR_b_PwrPanel2LidSwtSts120A_TO: nonqueued-sender-com-spec{data-element=VeLINR_b_PwrPanel2LidSwtSts120A_TO, init-value=VeLINR_b_PwrPanel2LidSwtSts120A_TOValue:0}, provided-interface=VeLINR_b_PwrPanel2LidSwtSts120A_TO
      VeLINR_b_PwrPanel2LidSwtSts120B: nonqueued-sender-com-spec{data-element=VeLINR_b_PwrPanel2LidSwtSts120B, init-value=VeLINR_b_PwrPanel2LidSwtSts120BValue:0}, provided-interface=VeLINR_b_PwrPanel2LidSwtSts120B
      VeLINR_b_PwrPanel2LidSwtSts120B_TO: nonqueued-sender-com-spec{data-element=VeLINR_b_PwrPanel2LidSwtSts120B_TO, init-value=VeLINR_b_PwrPanel2LidSwtSts120B_TOValue:0}, provided-interface=VeLINR_b_PwrPanel2LidSwtSts120B_TO
      VeLINR_b_PwrPanel2LidSwtSts240: nonqueued-sender-com-spec{data-element=VeLINR_b_PwrPanel2LidSwtSts240, init-value=VeLINR_b_PwrPanel2LidSwtSts240Value:0}, provided-interface=VeLINR_b_PwrPanel2LidSwtSts240
      VeLINR_b_PwrPanel2LidSwtSts240TO: nonqueued-sender-com-spec{data-element=VeLINR_b_PwrPanel2LidSwtSts240TO, init-value=VeLINR_b_PwrPanel2LidSwtSts240TOValue:0}, provided-interface=VeLINR_b_PwrPanel2LidSwtSts240TO
      VeLINR_b_PwrPanel2AC_PrsntSens1: nonqueued-sender-com-spec{data-element=VeLINR_b_PwrPanel2AC_PrsntSens1, init-value=VeLINR_b_PwrPanel2AC_PrsntSens1Value:0}, provided-interface=VeLINR_b_PwrPanel2AC_PrsntSens1
      VeLINR_b_PwrPanel2AC_PrsntSens1TO: nonqueued-sender-com-spec{data-element=VeLINR_b_PwrPanel2AC_PrsntSens1TO, init-value=VeLINR_b_PwrPanel2AC_PrsntSens1TOValue:0}, provided-interface=VeLINR_b_PwrPanel2AC_PrsntSens1TO
      VeLINR_b_PwrPanel2AC_PrsntSens2: nonqueued-sender-com-spec{data-element=VeLINR_b_PwrPanel2AC_PrsntSens2, init-value=VeLINR_b_PwrPanel2AC_PrsntSens2Value:0}, provided-interface=VeLINR_b_PwrPanel2AC_PrsntSens2
      VeLINR_b_PwrPanel2AC_PrsntSens2TO: nonqueued-sender-com-spec{data-element=VeLINR_b_PwrPanel2AC_PrsntSens2TO, init-value=VeLINR_b_PwrPanel2AC_PrsntSens2TOValue:0}, provided-interface=VeLINR_b_PwrPanel2AC_PrsntSens2TO
      VeLINR_e_PwrPanel2_Fault_Reason: nonqueued-sender-com-spec{data-element=VeLINR_e_PwrPanel2_Fault_Reason, init-value=VeLINR_e_PwrPanel2_Fault_ReasonValue:0}, provided-interface=VeLINR_e_PwrPanel2_Fault_Reason
      VeLINR_b_PwrPanel2_Fault_ReasonTO: nonqueued-sender-com-spec{data-element=VeLINR_b_PwrPanel2_Fault_ReasonTO, init-value=VeLINR_b_PwrPanel2_Fault_ReasonTOValue:0}, provided-interface=VeLINR_b_PwrPanel2_Fault_ReasonTO
      VeLINR_b_RsErr_SPP2: nonqueued-sender-com-spec{data-element=VeLINR_b_RsErr_SPP2, init-value=VeLINR_b_RsErr_SPP2Value:0}, provided-interface=VeLINR_b_RsErr_SPP2
      VeLINR_b_RsErr_SPP2TO: nonqueued-sender-com-spec{data-element=VeLINR_b_RsErr_SPP2TO, init-value=VeLINR_b_RsErr_SPP2TOValue:0}, provided-interface=VeLINR_b_RsErr_SPP2TO
    39 x require port:
      SendLINR_AGS_PosRqVld: nonqueued-receiver-com-spec{data-element=SendLINR_AGS_PosRqVld, init-value=SendLINR_AGS_PosRqVldValue:1}, required-interface=SendLINR_AGS_PosRqVld
      SendLINR_AGS_CalRqVld: nonqueued-receiver-com-spec{data-element=SendLINR_AGS_CalRqVld, init-value=SendLINR_AGS_CalRqVldValue:1}, required-interface=SendLINR_AGS_CalRqVld
      SendLINR_AGS_BoostRqVld: nonqueued-receiver-com-spec{data-element=SendLINR_AGS_BoostRqVld, init-value=SendLINR_AGS_BoostRqVldValue:1}, required-interface=SendLINR_AGS_BoostRqVld
      SendLINR_M2SRes2BitVld: nonqueued-receiver-com-spec{data-element=SendLINR_M2SRes2BitVld, init-value=SendLINR_M2SRes2BitVldValue:1}, required-interface=SendLINR_M2SRes2BitVld
      SendLINR_M2SResByte{1..3}Vld: nonqueued-receiver-com-spec{data-element=SendLINR_M2SResByte{1..3}Vld, init-value=SendLINR_M2SResByte{1..3}VldValue:1}, required-interface=SendLINR_M2SResByte{1..3}Vld
      SendLINR_CEXV_PosRqVld: nonqueued-receiver-com-spec{data-element=SendLINR_CEXV_PosRqVld, init-value=SendLINR_CEXV_PosRqVldValue:1}, required-interface=SendLINR_CEXV_PosRqVld
      SendLINR_CEXV_CalCmdVld: nonqueued-receiver-com-spec{data-element=SendLINR_CEXV_CalCmdVld, init-value=SendLINR_CEXV_CalCmdVldValue:1}, required-interface=SendLINR_CEXV_CalCmdVld
      SendLINR_CPIM_SET_IND{1..5}Vld: nonqueued-receiver-com-spec{data-element=SendLINR_CPIM_SET_IND{1..5}Vld, init-value=SendLINR_CPIM_SET_IND{1..5}VldValue:1}, required-interface=SendLINR_CPIM_SET_IND{1..5}Vld
      SendLINR_CPIM_Blink_RateVld: nonqueued-receiver-com-spec{data-element=SendLINR_CPIM_Blink_RateVld, init-value=SendLINR_CPIM_Blink_RateVldValue:1}, required-interface=SendLINR_CPIM_Blink_RateVld
      SendLINR_CPIM_IND_ColorVld: nonqueued-receiver-com-spec{data-element=SendLINR_CPIM_IND_ColorVld, init-value=SendLINR_CPIM_IND_ColorVldValue:1}, required-interface=SendLINR_CPIM_IND_ColorVld
      SendLINR_ChrgPortLock_CmdVld: nonqueued-receiver-com-spec{data-element=SendLINR_ChrgPortLock_CmdVld, init-value=SendLINR_ChrgPortLock_CmdVldValue:1}, required-interface=SendLINR_ChrgPortLock_CmdVld
      SendLINR_Set_Icon1_cmdVld: nonqueued-receiver-com-spec{data-element=SendLINR_Set_Icon1_cmdVld, init-value=SendLINR_Set_Icon1_cmdVldValue:1}, required-interface=SendLINR_Set_Icon1_cmdVld
      SendLINR_Set_Icon2_cmdVld: nonqueued-receiver-com-spec{data-element=SendLINR_Set_Icon2_cmdVld, init-value=SendLINR_Set_Icon2_cmdVldValue:1}, required-interface=SendLINR_Set_Icon2_cmdVld
      SendLINR_DAY_LGT_MD_CPIM_Vld: nonqueued-receiver-com-spec{data-element=SendLINR_DAY_LGT_MD_CPIM_Vld, init-value=SendLINR_DAY_LGT_MD_CPIM_VldValue:1}, required-interface=SendLINR_DAY_LGT_MD_CPIM_Vld
      SendLINR_Backlight_CmdVld: nonqueued-receiver-com-spec{data-element=SendLINR_Backlight_CmdVld, init-value=SendLINR_Backlight_CmdVldValue:1}, required-interface=SendLINR_Backlight_CmdVld
      SendLINR_HvWtrHeatrPwrCnsAllwdVld: nonqueued-receiver-com-spec{data-element=SendLINR_HvWtrHeatrPwrCnsAllwdVld, init-value=SendLINR_HvWtrHeatrPwrCnsAllwdVldValue:1}, required-interface=SendLINR_HvWtrHeatrPwrCnsAllwdVld
      SendLINR_HvWtrHeatrWtrTDesVld: nonqueued-receiver-com-spec{data-element=SendLINR_HvWtrHeatrWtrTDesVld, init-value=SendLINR_HvWtrHeatrWtrTDesVldValue:1}, required-interface=SendLINR_HvWtrHeatrWtrTDesVld
      SendLINR_HvCooltHeatrEnadVld: nonqueued-receiver-com-spec{data-element=SendLINR_HvCooltHeatrEnadVld, init-value=SendLINR_HvCooltHeatrEnadVldValue:1}, required-interface=SendLINR_HvCooltHeatrEnadVld
      SendLINR_HVH_OverheatUnlockVld: nonqueued-receiver-com-spec{data-element=SendLINR_HVH_OverheatUnlockVld, init-value=SendLINR_HVH_OverheatUnlockVldValue:1}, required-interface=SendLINR_HVH_OverheatUnlockVld
      SendLINR_EOPB_RPM_COM_Vld: nonqueued-receiver-com-spec{data-element=SendLINR_EOPB_RPM_COM_Vld, init-value=SendLINR_EOPB_RPM_COM_VldValue:1}, required-interface=SendLINR_EOPB_RPM_COM_Vld
      SendLINR_EOPB_POST_RUN_COM_Vld: nonqueued-receiver-com-spec{data-element=SendLINR_EOPB_POST_RUN_COM_Vld, init-value=SendLINR_EOPB_POST_RUN_COM_VldValue:1}, required-interface=SendLINR_EOPB_POST_RUN_COM_Vld
      SendLINR_HTLBV_PosRqVld: nonqueued-receiver-com-spec{data-element=SendLINR_HTLBV_PosRqVld, init-value=SendLINR_HTLBV_PosRqVldValue:1}, required-interface=SendLINR_HTLBV_PosRqVld
      SendLINR_HTLBV_PosSvVld: nonqueued-receiver-com-spec{data-element=SendLINR_HTLBV_PosSvVld, init-value=SendLINR_HTLBV_PosSvVldValue:1}, required-interface=SendLINR_HTLBV_PosSvVld
      SendLINR_HTLBV_CalRqVld: nonqueued-receiver-com-spec{data-element=SendLINR_HTLBV_CalRqVld, init-value=SendLINR_HTLBV_CalRqVldValue:1}, required-interface=SendLINR_HTLBV_CalRqVld
      SendLINR_PECP2_RPM_REQ_PERCT_Vld: nonqueued-receiver-com-spec{data-element=SendLINR_PECP2_RPM_REQ_PERCT_Vld, init-value=SendLINR_PECP2_RPM_REQ_PERCT_VldValue:1}, required-interface=SendLINR_PECP2_RPM_REQ_PERCT_Vld
      SendLINR_PECP2_POST_RUN_REQ_Vld: nonqueued-receiver-com-spec{data-element=SendLINR_PECP2_POST_RUN_REQ_Vld, init-value=SendLINR_PECP2_POST_RUN_REQ_VldValue:1}, required-interface=SendLINR_PECP2_POST_RUN_REQ_Vld
      SendLINR_PECP2_FL_SAFE_ACTVT_Vld: nonqueued-receiver-com-spec{data-element=SendLINR_PECP2_FL_SAFE_ACTVT_Vld, init-value=SendLINR_PECP2_FL_SAFE_ACTVT_VldValue:1}, required-interface=SendLINR_PECP2_FL_SAFE_ACTVT_Vld
      SendLINR_PowerPanel2_LED_A_CmndVld: nonqueued-receiver-com-spec{data-element=SendLINR_PowerPanel2_LED_A_CmndVld, init-value=SendLINR_PowerPanel2_LED_A_CmndVldValue:1}, required-interface=SendLINR_PowerPanel2_LED_A_CmndVld
      SendLINR_PowerPanel2_LED_B_CmndVld: nonqueued-receiver-com-spec{data-element=SendLINR_PowerPanel2_LED_B_CmndVld, init-value=SendLINR_PowerPanel2_LED_B_CmndVldValue:1}, required-interface=SendLINR_PowerPanel2_LED_B_CmndVld
      SendLINR_DAY_LGT_MD_PowerPanel2Vld: nonqueued-receiver-com-spec{data-element=SendLINR_DAY_LGT_MD_PowerPanel2Vld, init-value=SendLINR_DAY_LGT_MD_PowerPanel2VldValue:1}, required-interface=SendLINR_DAY_LGT_MD_PowerPanel2Vld
      SignalLINR_EXVM_RdyForSleep: nonqueued-receiver-com-spec{data-element=SignalLINR_EXVM_RdyForSleep, init-value=SignalLINR_EXVM_RdyForSleepValue:0}, required-interface=SignalLINR_EXVM_RdyForSleep
      KeCFGR_b_EXVM_Equid: parameter-require-com-spec{init-value=Value:0, parameter=KeCFGR_b_EXVM_Equid}, required-interface=KeCFGR_b_EXVM_Equid
      KeCFGR_b_HTRBV_Equid: parameter-require-com-spec{init-value=Value:0, parameter=KeCFGR_b_HTRBV_Equid}, required-interface=KeCFGR_b_HTRBV_Equid
    24 x provide port:
      VeLINR_e_CoolantValve_ErrLinCom: nonqueued-sender-com-spec{data-element=VeLINR_e_CoolantValve_ErrLinCom, init-value=VeLINR_e_CoolantValve_ErrLinComValue:0}, provided-interface=VeLINR_e_CoolantValve_ErrLinCom
      VeLINR_b_CoolantValve_ErrLinComTO: nonqueued-sender-com-spec{data-element=VeLINR_b_CoolantValve_ErrLinComTO, init-value=VeLINR_b_CoolantValve_ErrLinComTOValue:0}, provided-interface=VeLINR_b_CoolantValve_ErrLinComTO
      VeLINR_e_CoolantValve_ErrPos: nonqueued-sender-com-spec{data-element=VeLINR_e_CoolantValve_ErrPos, init-value=VeLINR_e_CoolantValve_ErrPosValue:0}, provided-interface=VeLINR_e_CoolantValve_ErrPos
      VeLINR_b_CoolantValve_ErrPosTO: nonqueued-sender-com-spec{data-element=VeLINR_b_CoolantValve_ErrPosTO, init-value=VeLINR_b_CoolantValve_ErrPosTOValue:0}, provided-interface=VeLINR_b_CoolantValve_ErrPosTO
      VeLINR_b_CoolantVal_SelfCalReq: nonqueued-sender-com-spec{data-element=VeLINR_b_CoolantVal_SelfCalReq, init-value=VeLINR_b_CoolantVal_SelfCalReqValue:0}, provided-interface=VeLINR_b_CoolantVal_SelfCalReq
      VeLINR_b_CoolantVal_SelfCalReqTO: nonqueued-sender-com-spec{data-element=VeLINR_b_CoolantVal_SelfCalReqTO, init-value=VeLINR_b_CoolantVal_SelfCalReqTOValue:0}, provided-interface=VeLINR_b_CoolantVal_SelfCalReqTO
      VeLINR_e_CoolantVal_SystemState: nonqueued-sender-com-spec{data-element=VeLINR_e_CoolantVal_SystemState, init-value=VeLINR_e_CoolantVal_SystemStateValue:0}, provided-interface=VeLINR_e_CoolantVal_SystemState
      VeLINR_b_CoolantVal_SystemStateTO: nonqueued-sender-com-spec{data-element=VeLINR_b_CoolantVal_SystemStateTO, init-value=VeLINR_b_CoolantVal_SystemStateTOValue:0}, provided-interface=VeLINR_b_CoolantVal_SystemStateTO
      VeLINR_y_CoolantVal_EcuVoltage: nonqueued-sender-com-spec{data-element=VeLINR_y_CoolantVal_EcuVoltage, init-value=VeLINR_y_CoolantVal_EcuVoltageValue:0}, provided-interface=VeLINR_y_CoolantVal_EcuVoltage
      VeLINR_b_CoolantVal_EcuVoltageTO: nonqueued-sender-com-spec{data-element=VeLINR_b_CoolantVal_EcuVoltageTO, init-value=VeLINR_b_CoolantVal_EcuVoltageTOValue:0}, provided-interface=VeLINR_b_CoolantVal_EcuVoltageTO
      VeLINR_d_CoolVal_ActuatPosTrgt: nonqueued-sender-com-spec{data-element=VeLINR_d_CoolVal_ActuatPosTrgt, init-value=VeLINR_d_CoolVal_ActuatPosTrgtValue:0}, provided-interface=VeLINR_d_CoolVal_ActuatPosTrgt
      VeLINR_b_CoolVal_ActuatPosTrgtTO: nonqueued-sender-com-spec{data-element=VeLINR_b_CoolVal_ActuatPosTrgtTO, init-value=VeLINR_b_CoolVal_ActuatPosTrgtTOValue:0}, provided-interface=VeLINR_b_CoolVal_ActuatPosTrgtTO
      VeLINR_d_CoolantVal_ActuPosAct: nonqueued-sender-com-spec{data-element=VeLINR_d_CoolantVal_ActuPosAct, init-value=VeLINR_d_CoolantVal_ActuPosActValue:0}, provided-interface=VeLINR_d_CoolantVal_ActuPosAct
      VeLINR_b_CoolantVal_ActuPosActTO: nonqueued-sender-com-spec{data-element=VeLINR_b_CoolantVal_ActuPosActTO, init-value=VeLINR_b_CoolantVal_ActuPosActTOValue:0}, provided-interface=VeLINR_b_CoolantVal_ActuPosActTO
      VeLINR_y_CoolantValve_EcuTemp: nonqueued-sender-com-spec{data-element=VeLINR_y_CoolantValve_EcuTemp, init-value=VeLINR_y_CoolantValve_EcuTempValue:-40}, provided-interface=VeLINR_y_CoolantValve_EcuTemp
      VeLINR_b_CoolantValve_EcuTempTO: nonqueued-sender-com-spec{data-element=VeLINR_b_CoolantValve_EcuTempTO, init-value=VeLINR_b_CoolantValve_EcuTempTOValue:0}, provided-interface=VeLINR_b_CoolantValve_EcuTempTO
      VeLINR_e_CoolantValve_Err_Motor: nonqueued-sender-com-spec{data-element=VeLINR_e_CoolantValve_Err_Motor, init-value=VeLINR_e_CoolantValve_Err_MotorValue:0}, provided-interface=VeLINR_e_CoolantValve_Err_Motor
      VeLINR_b_CoolantValve_Err_MotorTO: nonqueued-sender-com-spec{data-element=VeLINR_b_CoolantValve_Err_MotorTO, init-value=VeLINR_b_CoolantValve_Err_MotorTOValue:0}, provided-interface=VeLINR_b_CoolantValve_Err_MotorTO
      VeLINR_e_CoolantValve_Err_Volt: nonqueued-sender-com-spec{data-element=VeLINR_e_CoolantValve_Err_Volt, init-value=VeLINR_e_CoolantValve_Err_VoltValue:0}, provided-interface=VeLINR_e_CoolantValve_Err_Volt
      VeLINR_b_CoolantValve_Err_VoltTO: nonqueued-sender-com-spec{data-element=VeLINR_b_CoolantValve_Err_VoltTO, init-value=VeLINR_b_CoolantValve_Err_VoltTOValue:0}, provided-interface=VeLINR_b_CoolantValve_Err_VoltTO
      VeLINR_e_CoolantValve_Err_Ecu: nonqueued-sender-com-spec{data-element=VeLINR_e_CoolantValve_Err_Ecu, init-value=VeLINR_e_CoolantValve_Err_EcuValue:0}, provided-interface=VeLINR_e_CoolantValve_Err_Ecu
      VeLINR_b_CoolantValve_Err_EcuTO: nonqueued-sender-com-spec{data-element=VeLINR_b_CoolantValve_Err_EcuTO, init-value=VeLINR_b_CoolantValve_Err_EcuTOValue:0}, provided-interface=VeLINR_b_CoolantValve_Err_EcuTO
      VeLINR_b_CoolantVal_ResponseErr: nonqueued-sender-com-spec{data-element=VeLINR_b_CoolantVal_ResponseErr, init-value=VeLINR_b_CoolantVal_ResponseErrValue:0}, provided-interface=VeLINR_b_CoolantVal_ResponseErr
      VeLINR_b_CoolantVal_ResponseErrTO: nonqueued-sender-com-spec{data-element=VeLINR_b_CoolantVal_ResponseErrTO, init-value=VeLINR_b_CoolantVal_ResponseErrTOValue:0}, provided-interface=VeLINR_b_CoolantVal_ResponseErrTO
    19 x require port:
      SendLINR_Control_TargetPos: nonqueued-receiver-com-spec{data-element=SendLINR_Control_TargetPos, init-value=SendLINR_Control_TargetPosValue:0}, required-interface=SendLINR_Control_TargetPos
      SendLINR_Control_TargetPosVld: nonqueued-receiver-com-spec{data-element=SendLINR_Control_TargetPosVld, init-value=SendLINR_Control_TargetPosVldValue:1}, required-interface=SendLINR_Control_TargetPosVld
      SendLINR_Control_Reserved1: nonqueued-receiver-com-spec{data-element=SendLINR_Control_Reserved1, init-value=SendLINR_Control_Reserved1Value:0}, required-interface=SendLINR_Control_Reserved1
      SendLINR_Control_Reserved1Vld: nonqueued-receiver-com-spec{data-element=SendLINR_Control_Reserved1Vld, init-value=SendLINR_Control_Reserved1VldValue:1}, required-interface=SendLINR_Control_Reserved1Vld
      SendLINR_Control_BlockDetEnbl: nonqueued-receiver-com-spec{data-element=SendLINR_Control_BlockDetEnbl, init-value=SendLINR_Control_BlockDetEnblValue:0}, required-interface=SendLINR_Control_BlockDetEnbl
      SendLINR_Control_BlockDetEnblVld: nonqueued-receiver-com-spec{data-element=SendLINR_Control_BlockDetEnblVld, init-value=SendLINR_Control_BlockDetEnblVldValue:1}, required-interface=SendLINR_Control_BlockDetEnblVld
      SendLINR_Control_DiagFunctnVal: nonqueued-receiver-com-spec{data-element=SendLINR_Control_DiagFunctnVal, init-value=SendLINR_Control_DiagFunctnValValue:0}, required-interface=SendLINR_Control_DiagFunctnVal
      SendLINR_Control_DiagFunctnValVld: nonqueued-receiver-com-spec{data-element=SendLINR_Control_DiagFunctnValVld, init-value=SendLINR_Control_DiagFunctnValVldValue:1}, required-interface=SendLINR_Control_DiagFunctnValVld
      SendLINR_Control_Reserved2: nonqueued-receiver-com-spec{data-element=SendLINR_Control_Reserved2, init-value=SendLINR_Control_Reserved2Value:0}, required-interface=SendLINR_Control_Reserved2
      SendLINR_Control_Reserved2Vld: nonqueued-receiver-com-spec{data-element=SendLINR_Control_Reserved2Vld, init-value=SendLINR_Control_Reserved2VldValue:1}, required-interface=SendLINR_Control_Reserved2Vld
      SendLINR_Control_Reserved3: nonqueued-receiver-com-spec{data-element=SendLINR_Control_Reserved3, init-value=SendLINR_Control_Reserved3Value:0}, required-interface=SendLINR_Control_Reserved3
      SendLINR_Control_Reserved3Vld: nonqueued-receiver-com-spec{data-element=SendLINR_Control_Reserved3Vld, init-value=SendLINR_Control_Reserved3VldValue:1}, required-interface=SendLINR_Control_Reserved3Vld
      SendLINR_Control_Reserved4: nonqueued-receiver-com-spec{data-element=SendLINR_Control_Reserved4, init-value=SendLINR_Control_Reserved4Value:0}, required-interface=SendLINR_Control_Reserved4
      SendLINR_Control_Reserved4Vld: nonqueued-receiver-com-spec{data-element=SendLINR_Control_Reserved4Vld, init-value=SendLINR_Control_Reserved4VldValue:1}, required-interface=SendLINR_Control_Reserved4Vld
      SendLINR_Control_Reserved5: nonqueued-receiver-com-spec{data-element=SendLINR_Control_Reserved5, init-value=SendLINR_Control_Reserved5Value:0}, required-interface=SendLINR_Control_Reserved5
      SendLINR_Control_Reserved5Vld: nonqueued-receiver-com-spec{data-element=SendLINR_Control_Reserved5Vld, init-value=SendLINR_Control_Reserved5VldValue:1}, required-interface=SendLINR_Control_Reserved5Vld
      SendLINR_Control_Reserved6: nonqueued-receiver-com-spec{data-element=SendLINR_Control_Reserved6, init-value=SendLINR_Control_Reserved6Value:0}, required-interface=SendLINR_Control_Reserved6
      SendLINR_Control_Reserved6Vld: nonqueued-receiver-com-spec{data-element=SendLINR_Control_Reserved6Vld, init-value=SendLINR_Control_Reserved6VldValue:1}, required-interface=SendLINR_Control_Reserved6Vld
      SignalLINR_HTRBV_RdyForSleep: nonqueued-receiver-com-spec{data-element=SignalLINR_HTRBV_RdyForSleep, init-value=SignalLINR_HTRBV_RdyForSleepValue:0}, required-interface=SignalLINR_HTRBV_RdyForSleep
    20 x provide port:
      VeLINR_e_CompFaultStat_800: nonqueued-sender-com-spec{data-element=VeLINR_e_CompFaultStat_800, init-value=VeLINR_e_CompFaultStat_800Value:0}, provided-interface=VeLINR_e_CompFaultStat_800
      VeLINR_b_CompFaultStat_800TO: nonqueued-sender-com-spec{data-element=VeLINR_b_CompFaultStat_800TO, init-value=VeLINR_b_CompFaultStat_800TOValue:0}, provided-interface=VeLINR_b_CompFaultStat_800TO
      VeLINR_e_CompStat_800: nonqueued-sender-com-spec{data-element=VeLINR_e_CompStat_800, init-value=VeLINR_e_CompStat_800Value:0}, provided-interface=VeLINR_e_CompStat_800
      VeLINR_b_CompStat_800TO: nonqueued-sender-com-spec{data-element=VeLINR_b_CompStat_800TO, init-value=VeLINR_b_CompStat_800TOValue:0}, provided-interface=VeLINR_b_CompStat_800TO
      VeLINR_n_CompressorSpd_800: nonqueued-sender-com-spec{data-element=VeLINR_n_CompressorSpd_800, init-value=VeLINR_n_CompressorSpd_800Value:0}, provided-interface=VeLINR_n_CompressorSpd_800
      VeLINR_b_CompressorSpd_800TO: nonqueued-sender-com-spec{data-element=VeLINR_b_CompressorSpd_800TO, init-value=VeLINR_b_CompressorSpd_800TOValue:0}, provided-interface=VeLINR_b_CompressorSpd_800TO
      VeLINR_b_CompSpdIncrReq_800: nonqueued-sender-com-spec{data-element=VeLINR_b_CompSpdIncrReq_800, init-value=VeLINR_b_CompSpdIncrReq_800Value:0}, provided-interface=VeLINR_b_CompSpdIncrReq_800
      VeLINR_b_CompSpdIncrReq_800TO: nonqueued-sender-com-spec{data-element=VeLINR_b_CompSpdIncrReq_800TO, init-value=VeLINR_b_CompSpdIncrReq_800TOValue:0}, provided-interface=VeLINR_b_CompSpdIncrReq_800TO
      VeLINR_b_RsErr_EAC2_800: nonqueued-sender-com-spec{data-element=VeLINR_b_RsErr_EAC2_800, init-value=VeLINR_b_RsErr_EAC2_800Value:0}, provided-interface=VeLINR_b_RsErr_EAC2_800
      VeLINR_b_RsErr_EAC2_800TO: nonqueued-sender-com-spec{data-element=VeLINR_b_RsErr_EAC2_800TO, init-value=VeLINR_b_RsErr_EAC2_800TOValue:0}, provided-interface=VeLINR_b_RsErr_EAC2_800TO
      VeLINR_P_CompElecPwr_800: nonqueued-sender-com-spec{data-element=VeLINR_P_CompElecPwr_800, init-value=VeLINR_P_CompElecPwr_800Value:0}, provided-interface=VeLINR_P_CompElecPwr_800
      VeLINR_b_CompElecPwr_800TO: nonqueued-sender-com-spec{data-element=VeLINR_b_CompElecPwr_800TO, init-value=VeLINR_b_CompElecPwr_800TOValue:0}, provided-interface=VeLINR_b_CompElecPwr_800TO
      VeLINR_T_CompBoardTemp_800: nonqueued-sender-com-spec{data-element=VeLINR_T_CompBoardTemp_800, init-value=VeLINR_T_CompBoardTemp_800Value:-40}, provided-interface=VeLINR_T_CompBoardTemp_800
      VeLINR_b_CompBoardTemp_800TO: nonqueued-sender-com-spec{data-element=VeLINR_b_CompBoardTemp_800TO, init-value=VeLINR_b_CompBoardTemp_800TOValue:0}, provided-interface=VeLINR_b_CompBoardTemp_800TO
      VeLINR_T_CompIGBTTemp_800: nonqueued-sender-com-spec{data-element=VeLINR_T_CompIGBTTemp_800, init-value=VeLINR_T_CompIGBTTemp_800Value:-40}, provided-interface=VeLINR_T_CompIGBTTemp_800
      VeLINR_b_CompIGBTTemp_800TO: nonqueued-sender-com-spec{data-element=VeLINR_b_CompIGBTTemp_800TO, init-value=VeLINR_b_CompIGBTTemp_800TOValue:0}, provided-interface=VeLINR_b_CompIGBTTemp_800TO
      VeLINR_I_CompElecCurr_800: nonqueued-sender-com-spec{data-element=VeLINR_I_CompElecCurr_800, init-value=VeLINR_I_CompElecCurr_800Value:0}, provided-interface=VeLINR_I_CompElecCurr_800
      VeLINR_b_CompElecCurr_800TO: nonqueued-sender-com-spec{data-element=VeLINR_b_CompElecCurr_800TO, init-value=VeLINR_b_CompElecCurr_800TOValue:0}, provided-interface=VeLINR_b_CompElecCurr_800TO
      VeLINR_U_CompHVInput_800: nonqueued-sender-com-spec{data-element=VeLINR_U_CompHVInput_800, init-value=VeLINR_U_CompHVInput_800Value:0}, provided-interface=VeLINR_U_CompHVInput_800
      VeLINR_b_CompHVInput_800TO: nonqueued-sender-com-spec{data-element=VeLINR_b_CompHVInput_800TO, init-value=VeLINR_b_CompHVInput_800TOValue:0}, provided-interface=VeLINR_b_CompHVInput_800TO
    9 x require port:
      SendLINR_PwrPanel_LED_C_Command: nonqueued-receiver-com-spec{data-element=SendLINR_PwrPanel_LED_C_Command, init-value=SendLINR_PwrPanel_LED_C_CommandValue:0}, required-interface=SendLINR_PwrPanel_LED_C_Command
      SendLINR_PwrPanel_LED_C_CommandVld: nonqueued-receiver-com-spec{data-element=SendLINR_PwrPanel_LED_C_CommandVld, init-value=SendLINR_PwrPanel_LED_C_CommandVldValue:1}, required-interface=SendLINR_PwrPanel_LED_C_CommandVld
      SendLINR_PwrPanel_LEDA_ColorCmd: nonqueued-receiver-com-spec{data-element=SendLINR_PwrPanel_LEDA_ColorCmd, init-value=SendLINR_PwrPanel_LEDA_ColorCmdValue:0}, required-interface=SendLINR_PwrPanel_LEDA_ColorCmd
      SendLINR_PwrPanel_LEDA_ColorCmdVld: nonqueued-receiver-com-spec{data-element=SendLINR_PwrPanel_LEDA_ColorCmdVld, init-value=SendLINR_PwrPanel_LEDA_ColorCmdVldValue:1}, required-interface=SendLINR_PwrPanel_LEDA_ColorCmdVld
      SendLINR_PwrPanel_LEDB_ColorCmd: nonqueued-receiver-com-spec{data-element=SendLINR_PwrPanel_LEDB_ColorCmd, init-value=SendLINR_PwrPanel_LEDB_ColorCmdValue:0}, required-interface=SendLINR_PwrPanel_LEDB_ColorCmd
      SendLINR_PwrPanel_LEDB_ColorCmdVld: nonqueued-receiver-com-spec{data-element=SendLINR_PwrPanel_LEDB_ColorCmdVld, init-value=SendLINR_PwrPanel_LEDB_ColorCmdVldValue:1}, required-interface=SendLINR_PwrPanel_LEDB_ColorCmdVld
      SendLINR_PwrPanel_LEDC_ColorCmd: nonqueued-receiver-com-spec{data-element=SendLINR_PwrPanel_LEDC_ColorCmd, init-value=SendLINR_PwrPanel_LEDC_ColorCmdValue:0}, required-interface=SendLINR_PwrPanel_LEDC_ColorCmd
      SendLINR_PwrPanel_LEDC_ColorCmdVld: nonqueued-receiver-com-spec{data-element=SendLINR_PwrPanel_LEDC_ColorCmdVld, init-value=SendLINR_PwrPanel_LEDC_ColorCmdVldValue:1}, required-interface=SendLINR_PwrPanel_LEDC_ColorCmdVld
      SignalLINR_CACV_RdyForSleep: nonqueued-receiver-com-spec{data-element=SignalLINR_CACV_RdyForSleep, init-value=SignalLINR_CACV_RdyForSleepValue:0}, required-interface=SignalLINR_CACV_RdyForSleep
    52 x provide port:
      VeLINR_e_PwrPanel_LEDA_Feedback: nonqueued-sender-com-spec{data-element=VeLINR_e_PwrPanel_LEDA_Feedback, init-value=VeLINR_e_PwrPanel_LEDA_FeedbackValue:0}, provided-interface=VeLINR_e_PwrPanel_LEDA_Feedback
      VeLINR_b_PwrPanel_LEDA_FeedbackTO: nonqueued-sender-com-spec{data-element=VeLINR_b_PwrPanel_LEDA_FeedbackTO, init-value=VeLINR_b_PwrPanel_LEDA_FeedbackTOValue:0}, provided-interface=VeLINR_b_PwrPanel_LEDA_FeedbackTO
      VeLINR_e_PwrPanel_LEDB_Feedback: nonqueued-sender-com-spec{data-element=VeLINR_e_PwrPanel_LEDB_Feedback, init-value=VeLINR_e_PwrPanel_LEDB_FeedbackValue:0}, provided-interface=VeLINR_e_PwrPanel_LEDB_Feedback
      VeLINR_b_PwrPanel_LEDB_FeedbackTO: nonqueued-sender-com-spec{data-element=VeLINR_b_PwrPanel_LEDB_FeedbackTO, init-value=VeLINR_b_PwrPanel_LEDB_FeedbackTOValue:0}, provided-interface=VeLINR_b_PwrPanel_LEDB_FeedbackTO
      VeLINR_e_PwrPanel_LEDC_Feedback: nonqueued-sender-com-spec{data-element=VeLINR_e_PwrPanel_LEDC_Feedback, init-value=VeLINR_e_PwrPanel_LEDC_FeedbackValue:0}, provided-interface=VeLINR_e_PwrPanel_LEDC_Feedback
      VeLINR_b_PwrPanel_LEDC_FeedbackTO: nonqueued-sender-com-spec{data-element=VeLINR_b_PwrPanel_LEDC_FeedbackTO, init-value=VeLINR_b_PwrPanel_LEDC_FeedbackTOValue:0}, provided-interface=VeLINR_b_PwrPanel_LEDC_FeedbackTO
      VeLINR_e_PwrPanel_LEDA_FailSts: nonqueued-sender-com-spec{data-element=VeLINR_e_PwrPanel_LEDA_FailSts, init-value=VeLINR_e_PwrPanel_LEDA_FailStsValue:0}, provided-interface=VeLINR_e_PwrPanel_LEDA_FailSts
      VeLINR_b_PwrPanel_LEDA_FailStsTO: nonqueued-sender-com-spec{data-element=VeLINR_b_PwrPanel_LEDA_FailStsTO, init-value=VeLINR_b_PwrPanel_LEDA_FailStsTOValue:0}, provided-interface=VeLINR_b_PwrPanel_LEDA_FailStsTO
      VeLINR_e_PwrPanel_LEDB_FailSts: nonqueued-sender-com-spec{data-element=VeLINR_e_PwrPanel_LEDB_FailSts, init-value=VeLINR_e_PwrPanel_LEDB_FailStsValue:0}, provided-interface=VeLINR_e_PwrPanel_LEDB_FailSts
      VeLINR_b_PwrPanel_LEDB_FailStsTO: nonqueued-sender-com-spec{data-element=VeLINR_b_PwrPanel_LEDB_FailStsTO, init-value=VeLINR_b_PwrPanel_LEDB_FailStsTOValue:0}, provided-interface=VeLINR_b_PwrPanel_LEDB_FailStsTO
      VeLINR_e_PwrPanel_LEDC_FailSts: nonqueued-sender-com-spec{data-element=VeLINR_e_PwrPanel_LEDC_FailSts, init-value=VeLINR_e_PwrPanel_LEDC_FailStsValue:0}, provided-interface=VeLINR_e_PwrPanel_LEDC_FailSts
      VeLINR_b_PwrPanel_LEDC_FailStsTO: nonqueued-sender-com-spec{data-element=VeLINR_b_PwrPanel_LEDC_FailStsTO, init-value=VeLINR_b_PwrPanel_LEDC_FailStsTOValue:0}, provided-interface=VeLINR_b_PwrPanel_LEDC_FailStsTO
      VeLINR_e_PwrPanelLEDAColorFdbck: nonqueued-sender-com-spec{data-element=VeLINR_e_PwrPanelLEDAColorFdbck, init-value=VeLINR_e_PwrPanelLEDAColorFdbckValue:0}, provided-interface=VeLINR_e_PwrPanelLEDAColorFdbck
      VeLINR_b_PwrPanelLEDAColorFdbckTO: nonqueued-sender-com-spec{data-element=VeLINR_b_PwrPanelLEDAColorFdbckTO, init-value=VeLINR_b_PwrPanelLEDAColorFdbckTOValue:0}, provided-interface=VeLINR_b_PwrPanelLEDAColorFdbckTO
      VeLINR_e_PwrPanelLEDBColorFdbck: nonqueued-sender-com-spec{data-element=VeLINR_e_PwrPanelLEDBColorFdbck, init-value=VeLINR_e_PwrPanelLEDBColorFdbckValue:0}, provided-interface=VeLINR_e_PwrPanelLEDBColorFdbck
      VeLINR_b_PwrPanelLEDBColorFdbckTO: nonqueued-sender-com-spec{data-element=VeLINR_b_PwrPanelLEDBColorFdbckTO, init-value=VeLINR_b_PwrPanelLEDBColorFdbckTOValue:0}, provided-interface=VeLINR_b_PwrPanelLEDBColorFdbckTO
      VeLINR_e_PwrPanelLEDCColorFdbck: nonqueued-sender-com-spec{data-element=VeLINR_e_PwrPanelLEDCColorFdbck, init-value=VeLINR_e_PwrPanelLEDCColorFdbckValue:0}, provided-interface=VeLINR_e_PwrPanelLEDCColorFdbck
      VeLINR_b_PwrPanelLEDCColorFdbckTO: nonqueued-sender-com-spec{data-element=VeLINR_b_PwrPanelLEDCColorFdbckTO, init-value=VeLINR_b_PwrPanelLEDCColorFdbckTOValue:0}, provided-interface=VeLINR_b_PwrPanelLEDCColorFdbckTO
      VeLINR_b_PwrPanel_LIN_ChksumErr: nonqueued-sender-com-spec{data-element=VeLINR_b_PwrPanel_LIN_ChksumErr, init-value=VeLINR_b_PwrPanel_LIN_ChksumErrValue:0}, provided-interface=VeLINR_b_PwrPanel_LIN_ChksumErr
      VeLINR_b_PwrPanel_LIN_ChksumErrTO: nonqueued-sender-com-spec{data-element=VeLINR_b_PwrPanel_LIN_ChksumErrTO, init-value=VeLINR_b_PwrPanel_LIN_ChksumErrTOValue:0}, provided-interface=VeLINR_b_PwrPanel_LIN_ChksumErrTO
      VeLINR_b_PwrPanel_LIN_DataError: nonqueued-sender-com-spec{data-element=VeLINR_b_PwrPanel_LIN_DataError, init-value=VeLINR_b_PwrPanel_LIN_DataErrorValue:0}, provided-interface=VeLINR_b_PwrPanel_LIN_DataError
      VeLINR_b_PwrPanel_LIN_DataErrorTO: nonqueued-sender-com-spec{data-element=VeLINR_b_PwrPanel_LIN_DataErrorTO, init-value=VeLINR_b_PwrPanel_LIN_DataErrorTOValue:0}, provided-interface=VeLINR_b_PwrPanel_LIN_DataErrorTO
      VeLINR_b_PwrPanel_LIN_ParityErr: nonqueued-sender-com-spec{data-element=VeLINR_b_PwrPanel_LIN_ParityErr, init-value=VeLINR_b_PwrPanel_LIN_ParityErrValue:0}, provided-interface=VeLINR_b_PwrPanel_LIN_ParityErr
      VeLINR_b_PwrPanel_LIN_ParityErrTO: nonqueued-sender-com-spec{data-element=VeLINR_b_PwrPanel_LIN_ParityErrTO, init-value=VeLINR_b_PwrPanel_LIN_ParityErrTOValue:0}, provided-interface=VeLINR_b_PwrPanel_LIN_ParityErrTO
      VeLINR_b_PwrPanelGndFltDetected: nonqueued-sender-com-spec{data-element=VeLINR_b_PwrPanelGndFltDetected, init-value=VeLINR_b_PwrPanelGndFltDetectedValue:0}, provided-interface=VeLINR_b_PwrPanelGndFltDetected
      VeLINR_b_PwrPanelGndFltDetectedTO: nonqueued-sender-com-spec{data-element=VeLINR_b_PwrPanelGndFltDetectedTO, init-value=VeLINR_b_PwrPanelGndFltDetectedTOValue:0}, provided-interface=VeLINR_b_PwrPanelGndFltDetectedTO
      VeLINR_b_RsErr_EAC2: nonqueued-sender-com-spec{data-element=VeLINR_b_RsErr_EAC2, init-value=VeLINR_b_RsErr_EAC2Value:0}, provided-interface=VeLINR_b_RsErr_EAC2
      VeLINR_b_RsErr_EAC2TO: nonqueued-sender-com-spec{data-element=VeLINR_b_RsErr_EAC2TO, init-value=VeLINR_b_RsErr_EAC2TOValue:0}, provided-interface=VeLINR_b_RsErr_EAC2TO
      VeLINR_e_PowerPanel_Fault: nonqueued-sender-com-spec{data-element=VeLINR_e_PowerPanel_Fault, init-value=VeLINR_e_PowerPanel_FaultValue:0}, provided-interface=VeLINR_e_PowerPanel_Fault
      VeLINR_b_PowerPanel_FaultTO: nonqueued-sender-com-spec{data-element=VeLINR_b_PowerPanel_FaultTO, init-value=VeLINR_b_PowerPanel_FaultTOValue:0}, provided-interface=VeLINR_b_PowerPanel_FaultTO
      VeLINR_y_PowerPanel_RatedPower: nonqueued-sender-com-spec{data-element=VeLINR_y_PowerPanel_RatedPower, init-value=VeLINR_y_PowerPanel_RatedPowerValue:0}, provided-interface=VeLINR_y_PowerPanel_RatedPower
      VeLINR_b_PowerPanel_RatedPowerTO: nonqueued-sender-com-spec{data-element=VeLINR_b_PowerPanel_RatedPowerTO, init-value=VeLINR_b_PowerPanel_RatedPowerTOValue:0}, provided-interface=VeLINR_b_PowerPanel_RatedPowerTO
      VeLINR_e_PowerPanel2_LED_A_Fdbk: nonqueued-sender-com-spec{data-element=VeLINR_e_PowerPanel2_LED_A_Fdbk, init-value=VeLINR_e_PowerPanel2_LED_A_FdbkValue:0}, provided-interface=VeLINR_e_PowerPanel2_LED_A_Fdbk
      VeLINR_b_PowerPanel2_LED_A_FdbkTO: nonqueued-sender-com-spec{data-element=VeLINR_b_PowerPanel2_LED_A_FdbkTO, init-value=VeLINR_b_PowerPanel2_LED_A_FdbkTOValue:0}, provided-interface=VeLINR_b_PowerPanel2_LED_A_FdbkTO
      VeLINR_e_PowerPanel2_LED_B_Fdbk: nonqueued-sender-com-spec{data-element=VeLINR_e_PowerPanel2_LED_B_Fdbk, init-value=VeLINR_e_PowerPanel2_LED_B_FdbkValue:0}, provided-interface=VeLINR_e_PowerPanel2_LED_B_Fdbk
      VeLINR_b_PowerPanel2_LED_B_FdbkTO: nonqueued-sender-com-spec{data-element=VeLINR_b_PowerPanel2_LED_B_FdbkTO, init-value=VeLINR_b_PowerPanel2_LED_B_FdbkTOValue:0}, provided-interface=VeLINR_b_PowerPanel2_LED_B_FdbkTO
      VeLINR_e_PowPan2_LED_A_FailStat: nonqueued-sender-com-spec{data-element=VeLINR_e_PowPan2_LED_A_FailStat, init-value=VeLINR_e_PowPan2_LED_A_FailStatValue:0}, provided-interface=VeLINR_e_PowPan2_LED_A_FailStat
      VeLINR_b_PowPan2_LED_A_FailStatTO: nonqueued-sender-com-spec{data-element=VeLINR_b_PowPan2_LED_A_FailStatTO, init-value=VeLINR_b_PowPan2_LED_A_FailStatTOValue:0}, provided-interface=VeLINR_b_PowPan2_LED_A_FailStatTO
      VeLINR_e_PowPan2_LED_B_FailStat: nonqueued-sender-com-spec{data-element=VeLINR_e_PowPan2_LED_B_FailStat, init-value=VeLINR_e_PowPan2_LED_B_FailStatValue:0}, provided-interface=VeLINR_e_PowPan2_LED_B_FailStat
      VeLINR_b_PowPan2_LED_B_FailStatTO: nonqueued-sender-com-spec{data-element=VeLINR_b_PowPan2_LED_B_FailStatTO, init-value=VeLINR_b_PowPan2_LED_B_FailStatTOValue:0}, provided-interface=VeLINR_b_PowPan2_LED_B_FailStatTO
      VeLINR_e_PowPan2_LED_A_Col_Fdbk: nonqueued-sender-com-spec{data-element=VeLINR_e_PowPan2_LED_A_Col_Fdbk, init-value=VeLINR_e_PowPan2_LED_A_Col_FdbkValue:0}, provided-interface=VeLINR_e_PowPan2_LED_A_Col_Fdbk
      VeLINR_b_PowPan2_LED_A_Col_FdbkTO: nonqueued-sender-com-spec{data-element=VeLINR_b_PowPan2_LED_A_Col_FdbkTO, init-value=VeLINR_b_PowPan2_LED_A_Col_FdbkTOValue:0}, provided-interface=VeLINR_b_PowPan2_LED_A_Col_FdbkTO
      VeLINR_e_PowPan2_LED_B_Col_Fdbk: nonqueued-sender-com-spec{data-element=VeLINR_e_PowPan2_LED_B_Col_Fdbk, init-value=VeLINR_e_PowPan2_LED_B_Col_FdbkValue:0}, provided-interface=VeLINR_e_PowPan2_LED_B_Col_Fdbk
      VeLINR_b_PowPan2_LED_B_Col_FdbkTO: nonqueued-sender-com-spec{data-element=VeLINR_b_PowPan2_LED_B_Col_FdbkTO, init-value=VeLINR_b_PowPan2_LED_B_Col_FdbkTOValue:0}, provided-interface=VeLINR_b_PowPan2_LED_B_Col_FdbkTO
      VeLINR_b_PowPan2_LIN_Cksm_Err: nonqueued-sender-com-spec{data-element=VeLINR_b_PowPan2_LIN_Cksm_Err, init-value=VeLINR_b_PowPan2_LIN_Cksm_ErrValue:0}, provided-interface=VeLINR_b_PowPan2_LIN_Cksm_Err
      VeLINR_b_PowPan2_LIN_Cksm_ErrTO: nonqueued-sender-com-spec{data-element=VeLINR_b_PowPan2_LIN_Cksm_ErrTO, init-value=VeLINR_b_PowPan2_LIN_Cksm_ErrTOValue:0}, provided-interface=VeLINR_b_PowPan2_LIN_Cksm_ErrTO
      VeLINR_b_PowPan2_LIN_Data_Err: nonqueued-sender-com-spec{data-element=VeLINR_b_PowPan2_LIN_Data_Err, init-value=VeLINR_b_PowPan2_LIN_Data_ErrValue:0}, provided-interface=VeLINR_b_PowPan2_LIN_Data_Err
      VeLINR_b_PowPan2_LIN_Data_ErrTO: nonqueued-sender-com-spec{data-element=VeLINR_b_PowPan2_LIN_Data_ErrTO, init-value=VeLINR_b_PowPan2_LIN_Data_ErrTOValue:0}, provided-interface=VeLINR_b_PowPan2_LIN_Data_ErrTO
      VeLINR_b_PowPan2_LIN_Parity_Err: nonqueued-sender-com-spec{data-element=VeLINR_b_PowPan2_LIN_Parity_Err, init-value=VeLINR_b_PowPan2_LIN_Parity_ErrValue:0}, provided-interface=VeLINR_b_PowPan2_LIN_Parity_Err
      VeLINR_b_PowPan2_LIN_Parity_ErrTO: nonqueued-sender-com-spec{data-element=VeLINR_b_PowPan2_LIN_Parity_ErrTO, init-value=VeLINR_b_PowPan2_LIN_Parity_ErrTOValue:0}, provided-interface=VeLINR_b_PowPan2_LIN_Parity_ErrTO
      VeLINR_b_PowPan2_Gnd_Fault_Det: nonqueued-sender-com-spec{data-element=VeLINR_b_PowPan2_Gnd_Fault_Det, init-value=VeLINR_b_PowPan2_Gnd_Fault_DetValue:0}, provided-interface=VeLINR_b_PowPan2_Gnd_Fault_Det
      VeLINR_b_PowPan2_Gnd_Fault_DetTO: nonqueued-sender-com-spec{data-element=VeLINR_b_PowPan2_Gnd_Fault_DetTO, init-value=VeLINR_b_PowPan2_Gnd_Fault_DetTOValue:0}, provided-interface=VeLINR_b_PowPan2_Gnd_Fault_DetTO
    4 x require port:
      SendLINR_PowPan2_LED_A_Col_Comm: nonqueued-receiver-com-spec{data-element=SendLINR_PowPan2_LED_A_Col_Comm, init-value=SendLINR_PowPan2_LED_A_Col_CommValue:0}, required-interface=SendLINR_PowPan2_LED_A_Col_Comm
      SendLINR_PowPan2_LED_A_Col_CommVld: nonqueued-receiver-com-spec{data-element=SendLINR_PowPan2_LED_A_Col_CommVld, init-value=SendLINR_PowPan2_LED_A_Col_CommVldValue:1}, required-interface=SendLINR_PowPan2_LED_A_Col_CommVld
      SendLINR_PowPan2_LED_B_Col_Comm: nonqueued-receiver-com-spec{data-element=SendLINR_PowPan2_LED_B_Col_Comm, init-value=SendLINR_PowPan2_LED_B_Col_CommValue:0}, required-interface=SendLINR_PowPan2_LED_B_Col_Comm
      SendLINR_PowPan2_LED_B_Col_CommVld: nonqueued-receiver-com-spec{data-element=SendLINR_PowPan2_LED_B_Col_CommVld, init-value=SendLINR_PowPan2_LED_B_Col_CommVldValue:1}, required-interface=SendLINR_PowPan2_LED_B_Col_CommVld
    12 x provide port:
      VeLINR_d_PwrPanel2CurrDrawSens1: nonqueued-sender-com-spec{data-element=VeLINR_d_PwrPanel2CurrDrawSens1, init-value=VeLINR_d_PwrPanel2CurrDrawSens1Value:0}, provided-interface=VeLINR_d_PwrPanel2CurrDrawSens1
      VeLINR_b_PwrPanel2CurrDrawSens1TO: nonqueued-sender-com-spec{data-element=VeLINR_b_PwrPanel2CurrDrawSens1TO, init-value=VeLINR_b_PwrPanel2CurrDrawSens1TOValue:0}, provided-interface=VeLINR_b_PwrPanel2CurrDrawSens1TO
      VeLINR_d_PwrPanel2CurrDrawSens2: nonqueued-sender-com-spec{data-element=VeLINR_d_PwrPanel2CurrDrawSens2, init-value=VeLINR_d_PwrPanel2CurrDrawSens2Value:0}, provided-interface=VeLINR_d_PwrPanel2CurrDrawSens2
      VeLINR_b_PwrPanel2CurrDrawSens2TO: nonqueued-sender-com-spec{data-element=VeLINR_b_PwrPanel2CurrDrawSens2TO, init-value=VeLINR_b_PwrPanel2CurrDrawSens2TOValue:0}, provided-interface=VeLINR_b_PwrPanel2CurrDrawSens2TO
      VeLINR_e_PowerPanel2_Fault: nonqueued-sender-com-spec{data-element=VeLINR_e_PowerPanel2_Fault, init-value=VeLINR_e_PowerPanel2_FaultValue:0}, provided-interface=VeLINR_e_PowerPanel2_Fault
      VeLINR_b_PowerPanel2_FaultTO: nonqueued-sender-com-spec{data-element=VeLINR_b_PowerPanel2_FaultTO, init-value=VeLINR_b_PowerPanel2_FaultTOValue:0}, provided-interface=VeLINR_b_PowerPanel2_FaultTO
      VeLINR_y_PowerPanel2_RatedPower: nonqueued-sender-com-spec{data-element=VeLINR_y_PowerPanel2_RatedPower, init-value=VeLINR_y_PowerPanel2_RatedPowerValue:0}, provided-interface=VeLINR_y_PowerPanel2_RatedPower
      VeLINR_b_PowerPanel2_RatedPowerTO: nonqueued-sender-com-spec{data-element=VeLINR_b_PowerPanel2_RatedPowerTO, init-value=VeLINR_b_PowerPanel2_RatedPowerTOValue:0}, provided-interface=VeLINR_b_PowerPanel2_RatedPowerTO
      VeLINR_d_PwrPanelCurrDrawSens1: nonqueued-sender-com-spec{data-element=VeLINR_d_PwrPanelCurrDrawSens1, init-value=VeLINR_d_PwrPanelCurrDrawSens1Value:0}, provided-interface=VeLINR_d_PwrPanelCurrDrawSens1
      VeLINR_b_PwrPanelCurrDrawSens1TO: nonqueued-sender-com-spec{data-element=VeLINR_b_PwrPanelCurrDrawSens1TO, init-value=VeLINR_b_PwrPanelCurrDrawSens1TOValue:0}, provided-interface=VeLINR_b_PwrPanelCurrDrawSens1TO
      VeLINR_d_PwrPanelCurrDrawSens2: nonqueued-sender-com-spec{data-element=VeLINR_d_PwrPanelCurrDrawSens2, init-value=VeLINR_d_PwrPanelCurrDrawSens2Value:0}, provided-interface=VeLINR_d_PwrPanelCurrDrawSens2
      VeLINR_b_PwrPanelCurrDrawSens2TO: nonqueued-sender-com-spec{data-element=VeLINR_b_PwrPanelCurrDrawSens2TO, init-value=VeLINR_b_PwrPanelCurrDrawSens2TOValue:0}, provided-interface=VeLINR_b_PwrPanelCurrDrawSens2TO
    component ApplLinComAb_LIN{1..3}: type=ApplLinComAb_LIN{1..3}  # Application Lin Communication Abstraction Component - is responsible with receiving and sending Lin data from/to the lower BSW Lin layers
    delegate ApplLinComAb_LIN{1..3}.Lin{1..3}ComRxSignalsSR <-> outer port Lin{1..3}ComRxSignalsSR
    delegate ApplLinComAb_LIN1.SendLINR_AAD_PosRq <-> outer port SendLINR_AAD_PosRq
    delegate ApplLinComAb_LIN1.SendLINR_AAD_CalRq <-> outer port SendLINR_AAD_CalRq
    delegate ApplLinComAb_LIN1.SendLINR_AAD_InitialIP_CalRq <-> outer port SendLINR_AAD_InitialIP_CalRq
    delegate ApplLinComAb_LIN1.SendLINR_BCP_RPM_REQ <-> outer port SendLINR_BCP_RPM_REQ
    delegate ApplLinComAb_LIN1.SendLINR_BCP_POST_RUN_REQ <-> outer port SendLINR_BCP_POST_RUN_REQ
    delegate ApplLinComAb_LIN1.SendLINR_BCP_FL_SAFE_ACTVT <-> outer port SendLINR_BCP_FL_SAFE_ACTVT
    delegate ApplLinComAb_LIN1.SendLINR_CPV_PosRq <-> outer port SendLINR_CPV_PosRq
    delegate ApplLinComAb_LIN1.SendLINR_CPV_PosSv <-> outer port SendLINR_CPV_PosSv
    delegate ApplLinComAb_LIN1.SendLINR_CPV_CalRq <-> outer port SendLINR_CPV_CalRq
    delegate ApplLinComAb_LIN1.SendLINR_AirHeatrPwrTgt <-> outer port SendLINR_AirHeatrPwrTgt
    delegate ApplLinComAb_LIN1.SendLINR_AirHeatrEnad <-> outer port SendLINR_AirHeatrEnad
    delegate ApplLinComAb_LIN1.SendLINR_EOPA_RPM_COM <-> outer port SendLINR_EOPA_RPM_COM
    delegate ApplLinComAb_LIN1.SendLINR_EOPA_POST_RUN_COM <-> outer port SendLINR_EOPA_POST_RUN_COM
    delegate ApplLinComAb_LIN1.SendLINR_LTRBV_PosRq <-> outer port SendLINR_LTRBV_PosRq
    delegate ApplLinComAb_LIN1.SendLINR_LTRBV_PosSv <-> outer port SendLINR_LTRBV_PosSv
    delegate ApplLinComAb_LIN1.SendLINR_LTRBV_CalRq <-> outer port SendLINR_LTRBV_CalRq
    delegate ApplLinComAb_LIN2.VeLINR_e_AGS2_CurrPos <-> outer port VeLINR_e_AGS2_CurrPos
    delegate ApplLinComAb_LIN2.VeLINR_b_AGS2_CurrPosTO <-> outer port VeLINR_b_AGS2_CurrPosTO
    delegate ApplLinComAb_LIN2.VeLINR_b_AGS2_CalStat <-> outer port VeLINR_b_AGS2_CalStat
    delegate ApplLinComAb_LIN2.VeLINR_b_AGS2_CalStatTO <-> outer port VeLINR_b_AGS2_CalStatTO
    delegate ApplLinComAb_LIN2.VeLINR_b_AGS2_CalActv <-> outer port VeLINR_b_AGS2_CalActv
    delegate ApplLinComAb_LIN2.VeLINR_b_AGS2_CalActvTO <-> outer port VeLINR_b_AGS2_CalActvTO
    delegate ApplLinComAb_LIN2.VeLINR_b_AGS2_ErrUnVolt <-> outer port VeLINR_b_AGS2_ErrUnVolt
    delegate ApplLinComAb_LIN2.VeLINR_b_AGS2_ErrUnVoltTO <-> outer port VeLINR_b_AGS2_ErrUnVoltTO
    delegate ApplLinComAb_LIN2.VeLINR_b_AGS2_ErrOvrVolt <-> outer port VeLINR_b_AGS2_ErrOvrVolt
    delegate ApplLinComAb_LIN2.VeLINR_b_AGS2_ErrOvrVoltTO <-> outer port VeLINR_b_AGS2_ErrOvrVoltTO
    delegate ApplLinComAb_LIN2.VeLINR_b_AGS2_ErrOvrTemp <-> outer port VeLINR_b_AGS2_ErrOvrTemp
    delegate ApplLinComAb_LIN2.VeLINR_b_AGS2_ErrOvrTempTO <-> outer port VeLINR_b_AGS2_ErrOvrTempTO
    delegate ApplLinComAb_LIN2.VeLINR_b_AGS2_ErrMechStuck <-> outer port VeLINR_b_AGS2_ErrMechStuck
    delegate ApplLinComAb_LIN2.VeLINR_b_AGS2_ErrMechStuckTO <-> outer port VeLINR_b_AGS2_ErrMechStuckTO
    delegate ApplLinComAb_LIN2.VeLINR_b_AGS2_ErrMechBreak <-> outer port VeLINR_b_AGS2_ErrMechBreak
    delegate ApplLinComAb_LIN2.VeLINR_b_AGS2_ErrMechBreakTO <-> outer port VeLINR_b_AGS2_ErrMechBreakTO
    delegate ApplLinComAb_LIN2.VeLINR_e_AGS2_ErrLIN <-> outer port VeLINR_e_AGS2_ErrLIN
    delegate ApplLinComAb_LIN2.VeLINR_b_AGS2_ErrLIN_TO <-> outer port VeLINR_b_AGS2_ErrLIN_TO
    delegate ApplLinComAb_LIN2.VeLINR_b_RsErr_AGS2 <-> outer port VeLINR_b_RsErr_AGS2
    delegate ApplLinComAb_LIN2.VeLINR_b_RsErr_AGS2TO <-> outer port VeLINR_b_RsErr_AGS2TO
    delegate ApplLinComAb_LIN2.VeLINR_b_AGS2_BoostStat <-> outer port VeLINR_b_AGS2_BoostStat
    delegate ApplLinComAb_LIN2.VeLINR_b_AGS2_BoostStatTO <-> outer port VeLINR_b_AGS2_BoostStatTO
    delegate ApplLinComAb_LIN2.VeLINR_b_S2MResBit1_AGS2 <-> outer port VeLINR_b_S2MResBit1_AGS2
    delegate ApplLinComAb_LIN2.VeLINR_b_S2MResBit1_AGS2TO <-> outer port VeLINR_b_S2MResBit1_AGS2TO
    delegate ApplLinComAb_LIN2.VeLINR_Pct_AHP_RPM_TGT_PERCT <-> outer port VeLINR_Pct_AHP_RPM_TGT_PERCT
    delegate ApplLinComAb_LIN2.VeLINR_b_AHP_RPM_TGT_PERCT_TO <-> outer port VeLINR_b_AHP_RPM_TGT_PERCT_TO
    delegate ApplLinComAb_LIN2.VeLINR_Pct_AHP_RPM_ACTL_PERCT <-> outer port VeLINR_Pct_AHP_RPM_ACTL_PERCT
    delegate ApplLinComAb_LIN2.VeLINR_b_AHP_RPM_ACTL_PERCT_TO <-> outer port VeLINR_b_AHP_RPM_ACTL_PERCT_TO
    delegate ApplLinComAb_LIN2.VeLINR_U_AHP_VLTG <-> outer port VeLINR_U_AHP_VLTG
    delegate ApplLinComAb_LIN2.VeLINR_b_AHP_VLTG_TO <-> outer port VeLINR_b_AHP_VLTG_TO
    delegate ApplLinComAb_LIN2.VeLINR_T_AHP_TEMP <-> outer port VeLINR_T_AHP_TEMP
    delegate ApplLinComAb_LIN2.VeLINR_b_AHP_TEMP_TO <-> outer port VeLINR_b_AHP_TEMP_TO
    delegate ApplLinComAb_LIN2.VeLINR_I_AHP_CURR <-> outer port VeLINR_I_AHP_CURR
    delegate ApplLinComAb_LIN2.VeLINR_b_AHP_CURR_TO <-> outer port VeLINR_b_AHP_CURR_TO
    delegate ApplLinComAb_LIN2.VeLINR_e_AHP_FL_SAFE_ACTVTD <-> outer port VeLINR_e_AHP_FL_SAFE_ACTVTD
    delegate ApplLinComAb_LIN2.VeLINR_b_AHP_FL_SAFE_ACTVTD_TO <-> outer port VeLINR_b_AHP_FL_SAFE_ACTVTD_TO
    delegate ApplLinComAb_LIN2.VeLINR_e_AHP_LMP_HM_AN_ON <-> outer port VeLINR_e_AHP_LMP_HM_AN_ON
    delegate ApplLinComAb_LIN2.VeLINR_b_AHP_LMP_HM_AN_ON_TO <-> outer port VeLINR_b_AHP_LMP_HM_AN_ON_TO
    delegate ApplLinComAb_LIN2.VeLINR_e_AHP_AIR_PRE_ERR <-> outer port VeLINR_e_AHP_AIR_PRE_ERR
    delegate ApplLinComAb_LIN2.VeLINR_b_AHP_AIR_PRE_ERR_TO <-> outer port VeLINR_b_AHP_AIR_PRE_ERR_TO
    delegate ApplLinComAb_LIN2.VeLINR_e_AHP_OVR_TMP_ERR <-> outer port VeLINR_e_AHP_OVR_TMP_ERR
    delegate ApplLinComAb_LIN2.VeLINR_b_AHP_OVR_TMP_ERR_TO <-> outer port VeLINR_b_AHP_OVR_TMP_ERR_TO
    delegate ApplLinComAb_LIN2.VeLINR_e_AHP_OVR_CUR_ERR <-> outer port VeLINR_e_AHP_OVR_CUR_ERR
    delegate ApplLinComAb_LIN2.VeLINR_b_AHP_OVR_CUR_ERR_TO <-> outer port VeLINR_b_AHP_OVR_CUR_ERR_TO
    delegate ApplLinComAb_LIN2.VeLINR_e_AHP_DR_RN_ERR <-> outer port VeLINR_e_AHP_DR_RN_ERR
    delegate ApplLinComAb_LIN2.VeLINR_b_AHP_DR_RN_ERR_TO <-> outer port VeLINR_b_AHP_DR_RN_ERR_TO
    delegate ApplLinComAb_LIN2.VeLINR_e_AHP_VLTG_ERR <-> outer port VeLINR_e_AHP_VLTG_ERR
    delegate ApplLinComAb_LIN2.VeLINR_b_AHP_VLTG_ERR_TO <-> outer port VeLINR_b_AHP_VLTG_ERR_TO
    delegate ApplLinComAb_LIN2.VeLINR_e_AHP_DBLK_ACTV <-> outer port VeLINR_e_AHP_DBLK_ACTV
    delegate ApplLinComAb_LIN2.VeLINR_b_AHP_DBLK_ACTV_TO <-> outer port VeLINR_b_AHP_DBLK_ACTV_TO
    delegate ApplLinComAb_LIN2.VeLINR_e_AHP_MONTRNG_RPM <-> outer port VeLINR_e_AHP_MONTRNG_RPM
    delegate ApplLinComAb_LIN2.VeLINR_b_AHP_MONTRNG_RPM_TO <-> outer port VeLINR_b_AHP_MONTRNG_RPM_TO
    delegate ApplLinComAb_LIN2.VeLINR_e_AHP_NODE_ERR <-> outer port VeLINR_e_AHP_NODE_ERR
    delegate ApplLinComAb_LIN2.VeLINR_b_AHP_NODE_ERR_TO <-> outer port VeLINR_b_AHP_NODE_ERR_TO
    delegate ApplLinComAb_LIN2.VeLINR_e_AHP_POST_RUN_STAT <-> outer port VeLINR_e_AHP_POST_RUN_STAT
    delegate ApplLinComAb_LIN2.VeLINR_b_AHP_POST_RUN_STAT_TO <-> outer port VeLINR_b_AHP_POST_RUN_STAT_TO
    delegate ApplLinComAb_LIN2.VeLINR_b_RsErr_AHP_PUMP <-> outer port VeLINR_b_RsErr_AHP_PUMP
    delegate ApplLinComAb_LIN2.VeLINR_b_RsErr_AHP_PUMP_TO <-> outer port VeLINR_b_RsErr_AHP_PUMP_TO
    delegate ApplLinComAb_LIN2.VeLINR_e_AHP_SUPPLIER <-> outer port VeLINR_e_AHP_SUPPLIER
    delegate ApplLinComAb_LIN2.VeLINR_b_AHP_SUPPLIER_TO <-> outer port VeLINR_b_AHP_SUPPLIER_TO
    delegate ApplLinComAb_LIN2.VeLINR_Pct_BHV_PosAct <-> outer port VeLINR_Pct_BHV_PosAct
    delegate ApplLinComAb_LIN2.VeLINR_b_BHV_PosActTO <-> outer port VeLINR_b_BHV_PosActTO
    delegate ApplLinComAb_LIN2.VeLINR_e_BHV_ERR <-> outer port VeLINR_e_BHV_ERR
    delegate ApplLinComAb_LIN2.VeLINR_b_BHV_ERR_TO <-> outer port VeLINR_b_BHV_ERR_TO
    delegate ApplLinComAb_LIN2.VeLINR_e_BHV_Sts <-> outer port VeLINR_e_BHV_Sts
    delegate ApplLinComAb_LIN2.VeLINR_b_BHV_StsTO <-> outer port VeLINR_b_BHV_StsTO
    delegate ApplLinComAb_LIN2.VeLINR_b_RsErr_BHV <-> outer port VeLINR_b_RsErr_BHV
    delegate ApplLinComAb_LIN2.VeLINR_b_RsErr_BHV_TO <-> outer port VeLINR_b_RsErr_BHV_TO
    delegate ApplLinComAb_LIN2.VeLINR_e_CompFaultStat <-> outer port VeLINR_e_CompFaultStat
    delegate ApplLinComAb_LIN2.VeLINR_b_CompFaultStatTO <-> outer port VeLINR_b_CompFaultStatTO
    delegate ApplLinComAb_LIN2.VeLINR_e_CompStat <-> outer port VeLINR_e_CompStat
    delegate ApplLinComAb_LIN2.VeLINR_b_CompStatTO <-> outer port VeLINR_b_CompStatTO
    delegate ApplLinComAb_LIN2.VeLINR_n_CompressorSpd <-> outer port VeLINR_n_CompressorSpd
    delegate ApplLinComAb_LIN2.VeLINR_b_CompressorSpdTO <-> outer port VeLINR_b_CompressorSpdTO
    delegate ApplLinComAb_LIN2.VeLINR_b_CompSpdIncrReq <-> outer port VeLINR_b_CompSpdIncrReq
    delegate ApplLinComAb_LIN2.VeLINR_b_CompSpdIncrReqTO <-> outer port VeLINR_b_CompSpdIncrReqTO
    delegate ApplLinComAb_LIN2.VeLINR_P_CompElecPwr <-> outer port VeLINR_P_CompElecPwr
    delegate ApplLinComAb_LIN2.VeLINR_b_CompElecPwrTO <-> outer port VeLINR_b_CompElecPwrTO
    delegate ApplLinComAb_LIN2.VeLINR_T_CompBoardTemp <-> outer port VeLINR_T_CompBoardTemp
    delegate ApplLinComAb_LIN2.VeLINR_b_CompBoardTempTO <-> outer port VeLINR_b_CompBoardTempTO
    delegate ApplLinComAb_LIN2.VeLINR_T_CompIGBTTemp <-> outer port VeLINR_T_CompIGBTTemp
    delegate ApplLinComAb_LIN2.VeLINR_b_CompIGBTTempTO <-> outer port VeLINR_b_CompIGBTTempTO
    delegate ApplLinComAb_LIN2.VeLINR_I_CompElecCurr <-> outer port VeLINR_I_CompElecCurr
    delegate ApplLinComAb_LIN2.VeLINR_b_CompElecCurrTO <-> outer port VeLINR_b_CompElecCurrTO
    delegate ApplLinComAb_LIN2.VeLINR_U_CompHVInput <-> outer port VeLINR_U_CompHVInput
    delegate ApplLinComAb_LIN2.VeLINR_b_CompHVInputTO <-> outer port VeLINR_b_CompHVInputTO
    delegate ApplLinComAb_LIN2.VeLINR_e_DriveMdReq <-> outer port VeLINR_e_DriveMdReq
    delegate ApplLinComAb_LIN2.VeLINR_b_DriveMdReqTO <-> outer port VeLINR_b_DriveMdReqTO
    delegate ApplLinComAb_LIN2.VeLINR_e_HybridModeRq_LIN <-> outer port VeLINR_e_HybridModeRq_LIN
    delegate ApplLinComAb_LIN2.VeLINR_b_HybridModeRq_LIN_TO <-> outer port VeLINR_b_HybridModeRq_LIN_TO
    delegate ApplLinComAb_LIN2.VeLINR_e_ESaveModeRq_LIN <-> outer port VeLINR_e_ESaveModeRq_LIN
    delegate ApplLinComAb_LIN2.VeLINR_b_ESaveModeRq_LIN_TO <-> outer port VeLINR_b_ESaveModeRq_LIN_TO
    delegate ApplLinComAb_LIN2.VeLINR_e_ElectricModeRq_LIN <-> outer port VeLINR_e_ElectricModeRq_LIN
    delegate ApplLinComAb_LIN2.VeLINR_b_ElectricModeRq_LIN_TO <-> outer port VeLINR_b_ElectricModeRq_LIN_TO
    delegate ApplLinComAb_LIN2.VeLINR_b_RsErr_ESBM <-> outer port VeLINR_b_RsErr_ESBM
    delegate ApplLinComAb_LIN2.VeLINR_b_RsErr_ESBM_TO <-> outer port VeLINR_b_RsErr_ESBM_TO
    delegate ApplLinComAb_LIN2.VeLINR_b_Refrig_Temp_LIN2TO <-> outer port VeLINR_b_Refrig_Temp_LIN2TO
    delegate ApplLinComAb_LIN2.VeLINR_Pct_PECP_RPM_TGT_PERCT <-> outer port VeLINR_Pct_PECP_RPM_TGT_PERCT
    delegate ApplLinComAb_LIN2.VeLINR_b_PECP_RPM_TGT_PERCT_TO <-> outer port VeLINR_b_PECP_RPM_TGT_PERCT_TO
    delegate ApplLinComAb_LIN2.VeLINR_Pct_PECP_RPM_ACTL_PERCT <-> outer port VeLINR_Pct_PECP_RPM_ACTL_PERCT
    delegate ApplLinComAb_LIN2.VeLINR_b_PECP_RPM_ACTL_PERCT_TO <-> outer port VeLINR_b_PECP_RPM_ACTL_PERCT_TO
    delegate ApplLinComAb_LIN2.VeLINR_U_PECP_VLTG <-> outer port VeLINR_U_PECP_VLTG
    delegate ApplLinComAb_LIN2.VeLINR_b_PECP_VLTG_TO <-> outer port VeLINR_b_PECP_VLTG_TO
    delegate ApplLinComAb_LIN2.VeLINR_T_PECP_TEMP <-> outer port VeLINR_T_PECP_TEMP
    delegate ApplLinComAb_LIN2.VeLINR_b_PECP_TEMP_TO <-> outer port VeLINR_b_PECP_TEMP_TO
    delegate ApplLinComAb_LIN2.VeLINR_I_PECP_CURR <-> outer port VeLINR_I_PECP_CURR
    delegate ApplLinComAb_LIN2.VeLINR_b_PECP_CURR_TO <-> outer port VeLINR_b_PECP_CURR_TO
    delegate ApplLinComAb_LIN2.VeLINR_e_PECP_FL_SAFE_ACTVTD <-> outer port VeLINR_e_PECP_FL_SAFE_ACTVTD
    delegate ApplLinComAb_LIN2.VeLINR_b_PECP_FL_SAFE_ACTVTD_TO <-> outer port VeLINR_b_PECP_FL_SAFE_ACTVTD_TO
    delegate ApplLinComAb_LIN2.VeLINR_e_PECP_LMP_HM_AN_ON <-> outer port VeLINR_e_PECP_LMP_HM_AN_ON
    delegate ApplLinComAb_LIN2.VeLINR_b_PECP_LMP_HM_AN_ON_TO <-> outer port VeLINR_b_PECP_LMP_HM_AN_ON_TO
    delegate ApplLinComAb_LIN2.VeLINR_e_PECP_AIR_PRE_ERR <-> outer port VeLINR_e_PECP_AIR_PRE_ERR
    delegate ApplLinComAb_LIN2.VeLINR_b_PECP_AIR_PRE_ERR_TO <-> outer port VeLINR_b_PECP_AIR_PRE_ERR_TO
    delegate ApplLinComAb_LIN2.VeLINR_e_PECP_OVR_TMP_ERR <-> outer port VeLINR_e_PECP_OVR_TMP_ERR
    delegate ApplLinComAb_LIN2.VeLINR_b_PECP_OVR_TMP_ERR_TO <-> outer port VeLINR_b_PECP_OVR_TMP_ERR_TO
    delegate ApplLinComAb_LIN2.VeLINR_e_PECP_OVR_CUR_ERR <-> outer port VeLINR_e_PECP_OVR_CUR_ERR
    delegate ApplLinComAb_LIN2.VeLINR_b_PECP_OVR_CUR_ERR_TO <-> outer port VeLINR_b_PECP_OVR_CUR_ERR_TO
    delegate ApplLinComAb_LIN2.VeLINR_e_PECP_DR_RN_ERR <-> outer port VeLINR_e_PECP_DR_RN_ERR
    delegate ApplLinComAb_LIN2.VeLINR_b_PECP_DR_RN_ERR_TO <-> outer port VeLINR_b_PECP_DR_RN_ERR_TO
    delegate ApplLinComAb_LIN2.VeLINR_e_PECP_VLTG_ERR <-> outer port VeLINR_e_PECP_VLTG_ERR
    delegate ApplLinComAb_LIN2.VeLINR_b_PECP_VLTG_ERR_TO <-> outer port VeLINR_b_PECP_VLTG_ERR_TO
    delegate ApplLinComAb_LIN2.VeLINR_e_PECP_DBLK_ACTV <-> outer port VeLINR_e_PECP_DBLK_ACTV
    delegate ApplLinComAb_LIN2.VeLINR_b_PECP_DBLK_ACTV_TO <-> outer port VeLINR_b_PECP_DBLK_ACTV_TO
    delegate ApplLinComAb_LIN2.VeLINR_e_PECP_MONTRNG_RPM <-> outer port VeLINR_e_PECP_MONTRNG_RPM
    delegate ApplLinComAb_LIN2.VeLINR_b_PECP_MONTRNG_RPM_TO <-> outer port VeLINR_b_PECP_MONTRNG_RPM_TO
    delegate ApplLinComAb_LIN2.VeLINR_e_PECP_NODE_ERR <-> outer port VeLINR_e_PECP_NODE_ERR
    delegate ApplLinComAb_LIN2.VeLINR_b_PECP_NODE_ERR_TO <-> outer port VeLINR_b_PECP_NODE_ERR_TO
    delegate ApplLinComAb_LIN2.VeLINR_e_PECP_POST_RUN_STAT <-> outer port VeLINR_e_PECP_POST_RUN_STAT
    delegate ApplLinComAb_LIN2.VeLINR_b_PECP_POST_RUN_STAT_TO <-> outer port VeLINR_b_PECP_POST_RUN_STAT_TO
    delegate ApplLinComAb_LIN2.VeLINR_b_RsErr_PECP_PUMP <-> outer port VeLINR_b_RsErr_PECP_PUMP
    delegate ApplLinComAb_LIN2.VeLINR_b_RsErr_PECP_PUMP_TO <-> outer port VeLINR_b_RsErr_PECP_PUMP_TO
    delegate ApplLinComAb_LIN2.VeLINR_e_PECP_SUPPLIER <-> outer port VeLINR_e_PECP_SUPPLIER
    delegate ApplLinComAb_LIN2.VeLINR_b_PECP_SUPPLIER_TO <-> outer port VeLINR_b_PECP_SUPPLIER_TO
    delegate ApplLinComAb_LIN2.VeLINR_I_PwrPanelCurrDrawSens1 <-> outer port VeLINR_I_PwrPanelCurrDrawSens1
    delegate ApplLinComAb_LIN2.VeLINR_b_PowerPanelButton_State <-> outer port VeLINR_b_PowerPanelButton_State
    delegate ApplLinComAb_LIN2.VeLINR_b_PowerPanelButton_StateTO <-> outer port VeLINR_b_PowerPanelButton_StateTO
    delegate ApplLinComAb_LIN2.VeLINR_b_PwrPanelLidSwtSts120A <-> outer port VeLINR_b_PwrPanelLidSwtSts120A
    delegate ApplLinComAb_LIN2.VeLINR_b_PwrPanelLidSwtSts120A_TO <-> outer port VeLINR_b_PwrPanelLidSwtSts120A_TO
    delegate ApplLinComAb_LIN2.VeLINR_b_PwrPanelLidSwtSts120B <-> outer port VeLINR_b_PwrPanelLidSwtSts120B
    delegate ApplLinComAb_LIN2.VeLINR_b_PwrPanelLidSwtSts120B_TO <-> outer port VeLINR_b_PwrPanelLidSwtSts120B_TO
    delegate ApplLinComAb_LIN2.VeLINR_b_PwrPanelLidSwtSts240 <-> outer port VeLINR_b_PwrPanelLidSwtSts240
    delegate ApplLinComAb_LIN2.VeLINR_b_PwrPanelLidSwtSts240TO <-> outer port VeLINR_b_PwrPanelLidSwtSts240TO
    delegate ApplLinComAb_LIN2.VeLINR_I_PwrPanelCurrDrawSens2 <-> outer port VeLINR_I_PwrPanelCurrDrawSens2
    delegate ApplLinComAb_LIN2.VeLINR_e_PowerPanel_FaultReason <-> outer port VeLINR_e_PowerPanel_FaultReason
    delegate ApplLinComAb_LIN2.VeLINR_b_PowerPanel_FaultReasonTO <-> outer port VeLINR_b_PowerPanel_FaultReasonTO
    delegate ApplLinComAb_LIN2.VeLINR_b_RsErr_SPP <-> outer port VeLINR_b_RsErr_SPP
    delegate ApplLinComAb_LIN2.VeLINR_b_RsErr_SPP_TO <-> outer port VeLINR_b_RsErr_SPP_TO
    delegate ApplLinComAb_LIN2.SendLINR_AGS2_PosRq <-> outer port SendLINR_AGS2_PosRq
    delegate ApplLinComAb_LIN2.SendLINR_AGS2_PosRqVld <-> outer port SendLINR_AGS2_PosRqVld
    delegate ApplLinComAb_LIN2.SendLINR_AGS2_CalRq <-> outer port SendLINR_AGS2_CalRq
    delegate ApplLinComAb_LIN2.SendLINR_AGS2_CalRqVld <-> outer port SendLINR_AGS2_CalRqVld
    delegate ApplLinComAb_LIN2.SendLINR_AGS2_BoostRq <-> outer port SendLINR_AGS2_BoostRq
    delegate ApplLinComAb_LIN2.SendLINR_AGS2_BoostRqVld <-> outer port SendLINR_AGS2_BoostRqVld
    delegate ApplLinComAb_LIN2.SendLINR_M2SRes2Bit_AGS2 <-> outer port SendLINR_M2SRes2Bit_AGS2
    delegate ApplLinComAb_LIN2.SendLINR_M2SRes2Bit_AGS2Vld <-> outer port SendLINR_M2SRes2Bit_AGS2Vld
    delegate ApplLinComAb_LIN2.SendLINR_M2SResByte1_AGS2 <-> outer port SendLINR_M2SResByte1_AGS2
    delegate ApplLinComAb_LIN2.SendLINR_M2SResByte1_AGS2Vld <-> outer port SendLINR_M2SResByte1_AGS2Vld
    delegate ApplLinComAb_LIN2.SendLINR_M2SResByte2_AGS2 <-> outer port SendLINR_M2SResByte2_AGS2
    delegate ApplLinComAb_LIN2.SendLINR_M2SResByte2_AGS2Vld <-> outer port SendLINR_M2SResByte2_AGS2Vld
    delegate ApplLinComAb_LIN2.SendLINR_M2SResByte3_AGS2 <-> outer port SendLINR_M2SResByte3_AGS2
    delegate ApplLinComAb_LIN2.SendLINR_M2SResByte3_AGS2Vld <-> outer port SendLINR_M2SResByte3_AGS2Vld
    delegate ApplLinComAb_LIN2.SendLINR_AHP_RPM_REQ_PERCT <-> outer port SendLINR_AHP_RPM_REQ_PERCT
    delegate ApplLinComAb_LIN2.SendLINR_AHP_RPM_REQ_PERCT_Vld <-> outer port SendLINR_AHP_RPM_REQ_PERCT_Vld
    delegate ApplLinComAb_LIN2.SendLINR_AHP_POST_RUN_REQ <-> outer port SendLINR_AHP_POST_RUN_REQ
    delegate ApplLinComAb_LIN2.SendLINR_AHP_POST_RUN_REQ_Vld <-> outer port SendLINR_AHP_POST_RUN_REQ_Vld
    delegate ApplLinComAb_LIN2.SendLINR_AHP_FL_SAFE_ACTVT <-> outer port SendLINR_AHP_FL_SAFE_ACTVT
    delegate ApplLinComAb_LIN2.SendLINR_AHP_FL_SAFE_ACTVT_Vld <-> outer port SendLINR_AHP_FL_SAFE_ACTVT_Vld
    delegate ApplLinComAb_LIN2.SendLINR_BHV_PosRq <-> outer port SendLINR_BHV_PosRq
    delegate ApplLinComAb_LIN2.SendLINR_BHV_PosRqVld <-> outer port SendLINR_BHV_PosRqVld
    delegate ApplLinComAb_LIN2.SendLINR_BHV_PosSv <-> outer port SendLINR_BHV_PosSv
    delegate ApplLinComAb_LIN2.SendLINR_BHV_PosSvVld <-> outer port SendLINR_BHV_PosSvVld
    delegate ApplLinComAb_LIN2.SendLINR_BHV_CalRq <-> outer port SendLINR_BHV_CalRq
    delegate ApplLinComAb_LIN2.SendLINR_BHV_CalRqVld <-> outer port SendLINR_BHV_CalRqVld
    delegate ApplLinComAb_LIN2.SendLINR_CompressorSpdReq <-> outer port SendLINR_CompressorSpdReq
    delegate ApplLinComAb_LIN2.SendLINR_CompressorSpdReqVld <-> outer port SendLINR_CompressorSpdReqVld
    delegate ApplLinComAb_LIN2.SendLINR_CompEnable <-> outer port SendLINR_CompEnable
    delegate ApplLinComAb_LIN2.SendLINR_CompEnableVld <-> outer port SendLINR_CompEnableVld
    delegate ApplLinComAb_LIN2.SendLINR_DriveEcohybridLmp <-> outer port SendLINR_DriveEcohybridLmp
    delegate ApplLinComAb_LIN2.SendLINR_DriveEcohybridLmpVld <-> outer port SendLINR_DriveEcohybridLmpVld
    delegate ApplLinComAb_LIN2.SendLINR_DriveElectricLmp <-> outer port SendLINR_DriveElectricLmp
    delegate ApplLinComAb_LIN2.SendLINR_DriveElectricLmpVld <-> outer port SendLINR_DriveElectricLmpVld
    delegate ApplLinComAb_LIN2.SendLINR_DriveESaveLmp <-> outer port SendLINR_DriveESaveLmp
    delegate ApplLinComAb_LIN2.SendLINR_DriveESaveLmpVld <-> outer port SendLINR_DriveESaveLmpVld
    delegate ApplLinComAb_LIN2.SendLINR_DriveSportHybridLmp <-> outer port SendLINR_DriveSportHybridLmp
    delegate ApplLinComAb_LIN2.SendLINR_DriveSportHybridLmpVld <-> outer port SendLINR_DriveSportHybridLmpVld
    delegate ApplLinComAb_LIN2.SendLINR_PanelIntensitySts <-> outer port SendLINR_PanelIntensitySts
    delegate ApplLinComAb_LIN2.SendLINR_PanelIntensityStsVld <-> outer port SendLINR_PanelIntensityStsVld
    delegate ApplLinComAb_LIN2.SendLINR_DAY_LGT_MD <-> outer port SendLINR_DAY_LGT_MD
    delegate ApplLinComAb_LIN2.SendLINR_DAY_LGT_MD_Vld <-> outer port SendLINR_DAY_LGT_MD_Vld
    delegate ApplLinComAb_LIN2.SendLINR_PECP_RPM_REQ_PERCT <-> outer port SendLINR_PECP_RPM_REQ_PERCT
    delegate ApplLinComAb_LIN2.SendLINR_PECP_RPM_REQ_PERCT_Vld <-> outer port SendLINR_PECP_RPM_REQ_PERCT_Vld
    delegate ApplLinComAb_LIN2.SendLINR_PECP_POST_RUN_REQ <-> outer port SendLINR_PECP_POST_RUN_REQ
    delegate ApplLinComAb_LIN2.SendLINR_PECP_POST_RUN_REQ_Vld <-> outer port SendLINR_PECP_POST_RUN_REQ_Vld
    delegate ApplLinComAb_LIN2.SendLINR_PECP_FL_SAFE_ACTVT <-> outer port SendLINR_PECP_FL_SAFE_ACTVT
    delegate ApplLinComAb_LIN2.SendLINR_PECP_FL_SAFE_ACTVT_Vld <-> outer port SendLINR_PECP_FL_SAFE_ACTVT_Vld
    delegate ApplLinComAb_LIN2.SendLINR_PwrPanel_LED_A_Command <-> outer port SendLINR_PwrPanel_LED_A_Command
    delegate ApplLinComAb_LIN2.SendLINR_PwrPanel_LED_A_CommandVld <-> outer port SendLINR_PwrPanel_LED_A_CommandVld
    delegate ApplLinComAb_LIN2.SendLINR_PwrPanel_LED_B_Command <-> outer port SendLINR_PwrPanel_LED_B_Command
    delegate ApplLinComAb_LIN2.SendLINR_PwrPanel_LED_B_CommandVld <-> outer port SendLINR_PwrPanel_LED_B_CommandVld
    delegate ApplLinComAb_LIN2.SendLINR_DAY_LGT_MD_PowerPanel <-> outer port SendLINR_DAY_LGT_MD_PowerPanel
    delegate ApplLinComAb_LIN2.SendLINR_DAY_LGT_MD_PowerPanelVld <-> outer port SendLINR_DAY_LGT_MD_PowerPanelVld
    delegate ApplLinComAb_LIN1.SignalLINR_AAD_RdyForSleep <-> outer port SignalLINR_AAD_RdyForSleep
    delegate ApplLinComAb_LIN1.SignalLINR_BCP_RdyForSleep <-> outer port SignalLINR_BCP_RdyForSleep
    delegate ApplLinComAb_LIN1.SignalLINR_CPV_RdyForSleep <-> outer port SignalLINR_CPV_RdyForSleep
    delegate ApplLinComAb_LIN1.SignalLINR_EAH_RdyForSleep <-> outer port SignalLINR_EAH_RdyForSleep
    delegate ApplLinComAb_LIN1.SignalLINR_EEXV_RdyForSleep <-> outer port SignalLINR_EEXV_RdyForSleep
    delegate ApplLinComAb_LIN1.SignalLINR_EOPA_RdyForSleep <-> outer port SignalLINR_EOPA_RdyForSleep
    delegate ApplLinComAb_LIN1.SignalLINR_EXVM_RdyForSleep <-> outer port SignalLINR_EXVM_RdyForSleep
    delegate ApplLinComAb_LIN1.SignalLINR_LTRBV_RdyForSleep <-> outer port SignalLINR_LTRBV_RdyForSleep
    delegate ApplLinComAb_LIN2.SignalLINR_AGS2_RdyForSleep <-> outer port SignalLINR_AGS2_RdyForSleep
    delegate ApplLinComAb_LIN2.SignalLINR_AHP_RdyForSleep <-> outer port SignalLINR_AHP_RdyForSleep
    delegate ApplLinComAb_LIN2.SignalLINR_BHV_RdyForSleep <-> outer port SignalLINR_BHV_RdyForSleep
    delegate ApplLinComAb_LIN2.SignalLINR_EAC2_RdyForSleep <-> outer port SignalLINR_EAC2_RdyForSleep
    delegate ApplLinComAb_LIN2.SignalLINR_ESBM_RdyForSleep <-> outer port SignalLINR_ESBM_RdyForSleep
    delegate ApplLinComAb_LIN2.SignalLINR_OEXV_RdyForSleep <-> outer port SignalLINR_OEXV_RdyForSleep
    delegate ApplLinComAb_LIN2.SignalLINR_PECP_RdyForSleep <-> outer port SignalLINR_PECP_RdyForSleep
    delegate ApplLinComAb_LIN2.SignalLINR_SPP_RdyForSleep <-> outer port SignalLINR_SPP_RdyForSleep
    delegate ApplLinComAb_LIN1.KeCFGR_b_AAD_Equid <-> outer port KeCFGR_b_AAD_Equid
    delegate ApplLinComAb_LIN1.KeCFGR_b_BCP_Equid <-> outer port KeCFGR_b_BCP_Equid
    delegate ApplLinComAb_LIN1.KeCFGR_b_CPV_Equid <-> outer port KeCFGR_b_CPV_Equid
    delegate ApplLinComAb_LIN1.KeCFGR_b_EAH_Equid <-> outer port KeCFGR_b_EAH_Equid
    delegate ApplLinComAb_LIN1.KeCFGR_b_EEXV_Equid <-> outer port KeCFGR_b_EEXV_Equid
    delegate ApplLinComAb_LIN1.KeCFGR_b_EOPA_Equid <-> outer port KeCFGR_b_EOPA_Equid
    delegate ApplLinComAb_LIN1.KeCFGR_b_EXVM_Equid <-> outer port KeCFGR_b_EXVM_Equid
    delegate ApplLinComAb_LIN1.KeCFGR_b_HTRBV_Equid <-> outer port KeCFGR_b_HTRBV_Equid
    delegate ApplLinComAb_LIN1.KeCFGR_b_LTRBV_Equid <-> outer port KeCFGR_b_LTRBV_Equid
    delegate ApplLinComAb_LIN1.KeLINR_y_LIN1SwtSchdTbl <-> outer port KeLINR_y_LIN1SwtSchdTbl
    delegate ApplLinComAb_LIN2.KeCFGR_b_AGS2_Equid <-> outer port KeCFGR_b_AGS2_Equid
    delegate ApplLinComAb_LIN2.KeCFGR_b_AHP_Equid <-> outer port KeCFGR_b_AHP_Equid
    delegate ApplLinComAb_LIN2.KeCFGR_b_BHV_Equid <-> outer port KeCFGR_b_BHV_Equid
    delegate ApplLinComAb_LIN2.KeCFGR_b_EAC2_Equid <-> outer port KeCFGR_b_EAC2_Equid
    delegate ApplLinComAb_LIN2.KeCFGR_b_ESBM_Equid <-> outer port KeCFGR_b_ESBM_Equid
    delegate ApplLinComAb_LIN2.KeCFGR_b_OEXV_Equid <-> outer port KeCFGR_b_OEXV_Equid
    delegate ApplLinComAb_LIN2.KeCFGR_b_PECP_Equid <-> outer port KeCFGR_b_PECP_Equid
    delegate ApplLinComAb_LIN2.KeCFGR_b_SPP_Equid <-> outer port KeCFGR_b_SPP_Equid
    delegate ApplLinComAb_LIN2.KeLINR_y_LIN2SwtSchdTbl <-> outer port KeLINR_y_LIN2SwtSchdTbl
    delegate ApplLinComAb_LIN3.KeCFGR_b_AGS_Equid <-> outer port KeCFGR_b_AGS_Equid
    delegate ApplLinComAb_LIN3.KeCFGR_b_CEXV_Equid <-> outer port KeCFGR_b_CEXV_Equid
    delegate ApplLinComAb_LIN3.KeCFGR_b_CPIM_Equid <-> outer port KeCFGR_b_CPIM_Equid
    delegate ApplLinComAb_LIN3.KeCFGR_b_ECH_Equid <-> outer port KeCFGR_b_ECH_Equid
    delegate ApplLinComAb_LIN3.KeCFGR_b_EOPB_Equid <-> outer port KeCFGR_b_EOPB_Equid
    delegate ApplLinComAb_LIN3.KeCFGR_b_HTLBV_Equid <-> outer port KeCFGR_b_HTLBV_Equid
    delegate ApplLinComAb_LIN3.KeCFGR_b_PECP2_Equid <-> outer port KeCFGR_b_PECP2_Equid
    delegate ApplLinComAb_LIN3.KeCFGR_b_SPP2_Equid <-> outer port KeCFGR_b_SPP2_Equid
    delegate ApplLinComAb_LIN3.KeLINR_y_LIN3SwtSchdTbl <-> outer port KeLINR_y_LIN3SwtSchdTbl
    delegate ApplLinComAb_LIN{1..3}.Lin{1..3}ComTxSignalsSR <-> outer port Lin{1..3}ComTxSignalsSR
    delegate ApplLinComAb_LIN1.VeLINR_b_LIN1_RequestsPostRun <-> outer port VeLINR_b_LIN1_RequestsPostRun
    delegate ApplLinComAb_LIN1.PP_MS_LinSMComMod <-> outer port PP_MS_LinSMComMod
    delegate ApplLinComAb_LIN1.KeCFGR_b_LIN1_Equid <-> outer port KeCFGR_b_LIN1_Equid
    delegate ApplLinComAb_LIN1.GetRteMode <-> outer port GetRteMode
    delegate ApplLinComAb_LIN2.VeLINR_b_LIN2_RequestsPostRun <-> outer port VeLINR_b_LIN2_RequestsPostRun
    delegate ApplLinComAb_LIN2.PP_MS_LinSMComMod <-> outer port PP_MS_LinSMComMod1
    delegate ApplLinComAb_LIN2.KeCFGR_b_LIN2_Equid <-> outer port KeCFGR_b_LIN2_Equid
    delegate ApplLinComAb_LIN2.GetRteMode <-> outer port GetRteMode1
    delegate ApplLinComAb_LIN3.PP_MS_LinSMComMod <-> outer port PP_MS_LinSMComMod2
    delegate ApplLinComAb_LIN3.KeCFGR_b_LIN3_Equid <-> outer port KeCFGR_b_LIN3_Equid
    delegate ApplLinComAb_LIN3.GetRteMode <-> outer port GetRteMode2
    delegate ApplLinComAb_LIN2.ApplLinComAbLin2EquidMN <-> outer port ApplLinComAbLin2EquidMN
    delegate ApplLinComAb_LIN3.ApplLinComAbLin3EquidMN <-> outer port ApplLinComAbLin3EquidMN
    delegate ApplLinComAb_LIN1.ApplLinComAbLin1EquidMN <-> outer port ApplLinComAbLin1EquidMN
    delegate ApplLinComAb_LIN1.VeLINR_d_LIN_SlavePrsntSts_LIN1 <-> outer port VeLINR_d_LIN_SlavePrsntSts_LIN1
    delegate ApplLinComAb_LIN2.VeLINR_d_LIN_SlavePrsntSts_LIN2 <-> outer port VeLINR_d_LIN_SlavePrsntSts_LIN2
    delegate ApplLinComAb_LIN1.VeLINR_e_AAD_CurrPos <-> outer port VeLINR_e_AAD_CurrPos
    delegate ApplLinComAb_LIN1.VeLINR_b_AAD_CurrPosTO <-> outer port VeLINR_b_AAD_CurrPosTO
    delegate ApplLinComAb_LIN1.VeLINR_b_AAD_CalStat <-> outer port VeLINR_b_AAD_CalStat
    delegate ApplLinComAb_LIN1.VeLINR_b_AAD_CalStatTO <-> outer port VeLINR_b_AAD_CalStatTO
    delegate ApplLinComAb_LIN1.VeLINR_b_AAD_CalActv <-> outer port VeLINR_b_AAD_CalActv
    delegate ApplLinComAb_LIN1.VeLINR_b_AAD_CalActvTO <-> outer port VeLINR_b_AAD_CalActvTO
    delegate ApplLinComAb_LIN1.VeLINR_b_AAD_ErrUnVolt <-> outer port VeLINR_b_AAD_ErrUnVolt
    delegate ApplLinComAb_LIN1.VeLINR_b_AAD_ErrUnVoltTO <-> outer port VeLINR_b_AAD_ErrUnVoltTO
    delegate ApplLinComAb_LIN1.VeLINR_b_AAD_ErrOvrVolt <-> outer port VeLINR_b_AAD_ErrOvrVolt
    delegate ApplLinComAb_LIN1.VeLINR_b_AAD_ErrOvrVoltTO <-> outer port VeLINR_b_AAD_ErrOvrVoltTO
    delegate ApplLinComAb_LIN1.VeLINR_b_AAD_ErrOvrTemp <-> outer port VeLINR_b_AAD_ErrOvrTemp
    delegate ApplLinComAb_LIN1.VeLINR_b_AAD_ErrOvrTempTO <-> outer port VeLINR_b_AAD_ErrOvrTempTO
    delegate ApplLinComAb_LIN1.VeLINR_b_AAD_ErrMechStuck <-> outer port VeLINR_b_AAD_ErrMechStuck
    delegate ApplLinComAb_LIN1.VeLINR_b_AAD_ErrMechStuckTO <-> outer port VeLINR_b_AAD_ErrMechStuckTO
    delegate ApplLinComAb_LIN1.VeLINR_b_AAD_ErrMechBreak <-> outer port VeLINR_b_AAD_ErrMechBreak
    delegate ApplLinComAb_LIN1.VeLINR_b_AAD_ErrMechBreakTO <-> outer port VeLINR_b_AAD_ErrMechBreakTO
    delegate ApplLinComAb_LIN1.VeLINR_b_RsErr_AAD <-> outer port VeLINR_b_RsErr_AAD
    delegate ApplLinComAb_LIN1.VeLINR_b_RsErr_AAD_TO <-> outer port VeLINR_b_RsErr_AAD_TO
    delegate ApplLinComAb_LIN1.VeLINR_Pct_BCP_RPM_TARGET <-> outer port VeLINR_Pct_BCP_RPM_TARGET
    delegate ApplLinComAb_LIN1.VeLINR_b_BCP_RPM_TARGET_TO <-> outer port VeLINR_b_BCP_RPM_TARGET_TO
    delegate ApplLinComAb_LIN1.VeLINR_Pct_BCP_RPM_ACTUAL <-> outer port VeLINR_Pct_BCP_RPM_ACTUAL
    delegate ApplLinComAb_LIN1.VeLINR_b_BCP_RPM_ACTUAL_TO <-> outer port VeLINR_b_BCP_RPM_ACTUAL_TO
    delegate ApplLinComAb_LIN1.VeLINR_U_BCP_VLTG <-> outer port VeLINR_U_BCP_VLTG
    delegate ApplLinComAb_LIN1.VeLINR_b_BCP_VLTG_TO <-> outer port VeLINR_b_BCP_VLTG_TO
    delegate ApplLinComAb_LIN1.VeLINR_T_BCP_TEMP <-> outer port VeLINR_T_BCP_TEMP
    delegate ApplLinComAb_LIN1.VeLINR_b_BCP_TEMP_TO <-> outer port VeLINR_b_BCP_TEMP_TO
    delegate ApplLinComAb_LIN1.VeLINR_I_BCP_CURR <-> outer port VeLINR_I_BCP_CURR
    delegate ApplLinComAb_LIN1.VeLINR_b_BCP_CURR_TO <-> outer port VeLINR_b_BCP_CURR_TO
    delegate ApplLinComAb_LIN1.VeLINR_e_BCP_FL_SAFE_ACTVTD <-> outer port VeLINR_e_BCP_FL_SAFE_ACTVTD
    delegate ApplLinComAb_LIN1.VeLINR_b_BCP_FL_SAFE_ACTVTD_TO <-> outer port VeLINR_b_BCP_FL_SAFE_ACTVTD_TO
    delegate ApplLinComAb_LIN1.VeLINR_e_BCP_LMP_HM_AN_ON <-> outer port VeLINR_e_BCP_LMP_HM_AN_ON
    delegate ApplLinComAb_LIN1.VeLINR_b_BCP_LMP_HM_AN_ON_TO <-> outer port VeLINR_b_BCP_LMP_HM_AN_ON_TO
    delegate ApplLinComAb_LIN1.VeLINR_e_BCP_AIR_PRE_ERR <-> outer port VeLINR_e_BCP_AIR_PRE_ERR
    delegate ApplLinComAb_LIN1.VeLINR_b_BCP_AIR_PRE_ERR_TO <-> outer port VeLINR_b_BCP_AIR_PRE_ERR_TO
    delegate ApplLinComAb_LIN1.VeLINR_e_BCP_OVR_TMP_ERR <-> outer port VeLINR_e_BCP_OVR_TMP_ERR
    delegate ApplLinComAb_LIN1.VeLINR_b_BCP_OVR_TMP_ERR_TO <-> outer port VeLINR_b_BCP_OVR_TMP_ERR_TO
    delegate ApplLinComAb_LIN1.VeLINR_e_BCP_OVR_CUR_ERR <-> outer port VeLINR_e_BCP_OVR_CUR_ERR
    delegate ApplLinComAb_LIN1.VeLINR_b_BCP_OVR_CUR_ERR_TO <-> outer port VeLINR_b_BCP_OVR_CUR_ERR_TO
    delegate ApplLinComAb_LIN1.VeLINR_e_BCP_DR_RN_ERR <-> outer port VeLINR_e_BCP_DR_RN_ERR
    delegate ApplLinComAb_LIN1.VeLINR_b_BCP_DR_RN_ERR_TO <-> outer port VeLINR_b_BCP_DR_RN_ERR_TO
    delegate ApplLinComAb_LIN1.VeLINR_e_BCP_VLTG_ERR <-> outer port VeLINR_e_BCP_VLTG_ERR
    delegate ApplLinComAb_LIN1.VeLINR_b_BCP_VLTG_ERR_TO <-> outer port VeLINR_b_BCP_VLTG_ERR_TO
    delegate ApplLinComAb_LIN1.VeLINR_e_BCP_DBLK_ACTV <-> outer port VeLINR_e_BCP_DBLK_ACTV
    delegate ApplLinComAb_LIN1.VeLINR_b_BCP_DBLK_ACTV_TO <-> outer port VeLINR_b_BCP_DBLK_ACTV_TO
    delegate ApplLinComAb_LIN1.VeLINR_e_BCP_MONTRNG_RPM <-> outer port VeLINR_e_BCP_MONTRNG_RPM
    delegate ApplLinComAb_LIN1.VeLINR_b_BCP_MONTRNG_RPM_TO <-> outer port VeLINR_b_BCP_MONTRNG_RPM_TO
    delegate ApplLinComAb_LIN1.VeLINR_e_BCP_NODE_ERR <-> outer port VeLINR_e_BCP_NODE_ERR
    delegate ApplLinComAb_LIN1.VeLINR_b_BCP_NODE_ERR_TO <-> outer port VeLINR_b_BCP_NODE_ERR_TO
    delegate ApplLinComAb_LIN1.VeLINR_e_BCP_POST_RUN_STAT <-> outer port VeLINR_e_BCP_POST_RUN_STAT
    delegate ApplLinComAb_LIN1.VeLINR_b_BCP_POST_RUN_STAT_TO <-> outer port VeLINR_b_BCP_POST_RUN_STAT_TO
    delegate ApplLinComAb_LIN1.VeLINR_b_RsErr_BCP_PUMP <-> outer port VeLINR_b_RsErr_BCP_PUMP
    delegate ApplLinComAb_LIN1.VeLINR_b_RsErr_BCP_PUMP_TO <-> outer port VeLINR_b_RsErr_BCP_PUMP_TO
    delegate ApplLinComAb_LIN1.VeLINR_y_BCP_VERSION <-> outer port VeLINR_y_BCP_VERSION
    delegate ApplLinComAb_LIN1.VeLINR_b_BCP_VERSION_TO <-> outer port VeLINR_b_BCP_VERSION_TO
    delegate ApplLinComAb_LIN1.VeLINR_e_BCP_SUPPLIER <-> outer port VeLINR_e_BCP_SUPPLIER
    delegate ApplLinComAb_LIN1.VeLINR_b_BCP_SUPPLIER_TO <-> outer port VeLINR_b_BCP_SUPPLIER_TO
    delegate ApplLinComAb_LIN1.VeLINR_Pct_CPV_PosAct <-> outer port VeLINR_Pct_CPV_PosAct
    delegate ApplLinComAb_LIN1.VeLINR_b_CPV_PosActTO <-> outer port VeLINR_b_CPV_PosActTO
    delegate ApplLinComAb_LIN1.VeLINR_e_CPV_ERR <-> outer port VeLINR_e_CPV_ERR
    delegate ApplLinComAb_LIN1.VeLINR_b_CPV_ERR_TO <-> outer port VeLINR_b_CPV_ERR_TO
    delegate ApplLinComAb_LIN1.VeLINR_e_CPV_Sts <-> outer port VeLINR_e_CPV_Sts
    delegate ApplLinComAb_LIN1.VeLINR_b_CPV_StsTO <-> outer port VeLINR_b_CPV_StsTO
    delegate ApplLinComAb_LIN1.VeLINR_b_RsErr_CPV <-> outer port VeLINR_b_RsErr_CPV
    delegate ApplLinComAb_LIN1.VeLINR_b_RsErr_CPV_TO <-> outer port VeLINR_b_RsErr_CPV_TO
    delegate ApplLinComAb_LIN1.VeLINR_I_AirHeatrICns <-> outer port VeLINR_I_AirHeatrICns
    delegate ApplLinComAb_LIN1.VeLINR_b_AirHeatrICnsTO <-> outer port VeLINR_b_AirHeatrICnsTO
    delegate ApplLinComAb_LIN1.VeLINR_U_AirHeatrHVmeas <-> outer port VeLINR_U_AirHeatrHVmeas
    delegate ApplLinComAb_LIN1.VeLINR_b_AirHeatrHVmeasTO <-> outer port VeLINR_b_AirHeatrHVmeasTO
    delegate ApplLinComAb_LIN1.VeLINR_T_AirHeatrPCBTemp <-> outer port VeLINR_T_AirHeatrPCBTemp
    delegate ApplLinComAb_LIN1.VeLINR_b_AirHeatrPCBTempTO <-> outer port VeLINR_b_AirHeatrPCBTempTO
    delegate ApplLinComAb_LIN1.VeLINR_T_AirHeatrCoreTemp <-> outer port VeLINR_T_AirHeatrCoreTemp
    delegate ApplLinComAb_LIN1.VeLINR_b_AirHeatrCoreTempTO <-> outer port VeLINR_b_AirHeatrCoreTempTO
    delegate ApplLinComAb_LIN1.VeLINR_b_RsErr_EAH <-> outer port VeLINR_b_RsErr_EAH
    delegate ApplLinComAb_LIN1.VeLINR_b_RsErr_EAH_TO <-> outer port VeLINR_b_RsErr_EAH_TO
    delegate ApplLinComAb_LIN1.VeLINR_e_AirHeatrWarnFltInCom <-> outer port VeLINR_e_AirHeatrWarnFltInCom
    delegate ApplLinComAb_LIN1.VeLINR_b_AirHeatrWarnFltInComTO <-> outer port VeLINR_b_AirHeatrWarnFltInComTO
    delegate ApplLinComAb_LIN1.VeLINR_e_AirHeatrWarnHvOutOfRng <-> outer port VeLINR_e_AirHeatrWarnHvOutOfRng
    delegate ApplLinComAb_LIN1.VeLINR_b_AirHeatrWarnHvOutOfRngTO <-> outer port VeLINR_b_AirHeatrWarnHvOutOfRngTO
    delegate ApplLinComAb_LIN1.VeLINR_e_AirHtrWarnULoOutOfRng <-> outer port VeLINR_e_AirHtrWarnULoOutOfRng
    delegate ApplLinComAb_LIN1.VeLINR_b_AirHtrWarnULoOutOfRngTO <-> outer port VeLINR_b_AirHtrWarnULoOutOfRngTO
    delegate ApplLinComAb_LIN1.VeLINR_e_AirHtrWarnTmpOvrheatg <-> outer port VeLINR_e_AirHtrWarnTmpOvrheatg
    delegate ApplLinComAb_LIN1.VeLINR_b_AirHtrWarnTmpOvrheatgTO <-> outer port VeLINR_b_AirHtrWarnTmpOvrheatgTO
    delegate ApplLinComAb_LIN1.VeLINR_e_AirHtrWarnICnsOutOfRng <-> outer port VeLINR_e_AirHtrWarnICnsOutOfRng
    delegate ApplLinComAb_LIN1.VeLINR_b_AirHtrWarnICnsOutOfRngTO <-> outer port VeLINR_b_AirHtrWarnICnsOutOfRngTO
    delegate ApplLinComAb_LIN1.VeLINR_e_AirHeatrDmgIntHwProtn <-> outer port VeLINR_e_AirHeatrDmgIntHwProtn
    delegate ApplLinComAb_LIN1.VeLINR_b_AirHeatrDmgIntHwProtnTO <-> outer port VeLINR_b_AirHeatrDmgIntHwProtnTO
    delegate ApplLinComAb_LIN1.VeLINR_e_AirHtrDmgPCBTmpSnsrFlt <-> outer port VeLINR_e_AirHtrDmgPCBTmpSnsrFlt
    delegate ApplLinComAb_LIN1.VeLINR_b_AirHtrDmgPCBTmpSnsrFltTO <-> outer port VeLINR_b_AirHtrDmgPCBTmpSnsrFltTO
    delegate ApplLinComAb_LIN1.VeLINR_e_AirHtrDmgCirDrvrShoOpn <-> outer port VeLINR_e_AirHtrDmgCirDrvrShoOpn
    delegate ApplLinComAb_LIN1.VeLINR_b_AirHtrDmgCirDrvrShoOpnTO <-> outer port VeLINR_b_AirHtrDmgCirDrvrShoOpnTO
    delegate ApplLinComAb_LIN1.VeLINR_e_AirHeatrDmgHVISnsrFlt <-> outer port VeLINR_e_AirHeatrDmgHVISnsrFlt
    delegate ApplLinComAb_LIN1.VeLINR_b_AirHeatrDmgHVISnsrFltTO <-> outer port VeLINR_b_AirHeatrDmgHVISnsrFltTO
    delegate ApplLinComAb_LIN1.VeLINR_e_AirHeatrDmgMemErr <-> outer port VeLINR_e_AirHeatrDmgMemErr
    delegate ApplLinComAb_LIN1.VeLINR_b_AirHeatrDmgMemErrTO <-> outer port VeLINR_b_AirHeatrDmgMemErrTO
    delegate ApplLinComAb_LIN1.VeLINR_e_AirHtrDmgHtrCorTS_Flt <-> outer port VeLINR_e_AirHtrDmgHtrCorTS_Flt
    delegate ApplLinComAb_LIN1.VeLINR_b_AirHtrDmgHtrCorTS_FltTO <-> outer port VeLINR_b_AirHtrDmgHtrCorTS_FltTO
    delegate ApplLinComAb_LIN1.VeLINR_e_AirHeatrWarnPCBOvrTmp <-> outer port VeLINR_e_AirHeatrWarnPCBOvrTmp
    delegate ApplLinComAb_LIN1.VeLINR_b_AirHeatrWarnPCBOvrTmpTO <-> outer port VeLINR_b_AirHeatrWarnPCBOvrTmpTO
    delegate ApplLinComAb_LIN1.VeLINR_e_AirHtrWrnHtrCorOvrTmp <-> outer port VeLINR_e_AirHtrWrnHtrCorOvrTmp
    delegate ApplLinComAb_LIN1.VeLINR_b_AirHtrWrnHtrCorOvrTmpTO <-> outer port VeLINR_b_AirHtrWrnHtrCorOvrTmpTO
    delegate ApplLinComAb_LIN1.VeLINR_e_EOPA_RPM_TGT <-> outer port VeLINR_e_EOPA_RPM_TGT
    delegate ApplLinComAb_LIN1.VeLINR_b_EOPA_RPM_TGT_TO <-> outer port VeLINR_b_EOPA_RPM_TGT_TO
    delegate ApplLinComAb_LIN1.VeLINR_e_EOPA_RPM_ACTL <-> outer port VeLINR_e_EOPA_RPM_ACTL
    delegate ApplLinComAb_LIN1.VeLINR_b_EOPA_RPM_ACTL_TO <-> outer port VeLINR_b_EOPA_RPM_ACTL_TO
    delegate ApplLinComAb_LIN1.VeLINR_U_EOPA_VLTG <-> outer port VeLINR_U_EOPA_VLTG
    delegate ApplLinComAb_LIN1.VeLINR_b_EOPA_VLTG_TO <-> outer port VeLINR_b_EOPA_VLTG_TO
    delegate ApplLinComAb_LIN1.VeLINR_T_EOPA_TEMP <-> outer port VeLINR_T_EOPA_TEMP
    delegate ApplLinComAb_LIN1.VeLINR_b_EOPA_TEMP_TO <-> outer port VeLINR_b_EOPA_TEMP_TO
    delegate ApplLinComAb_LIN1.VeLINR_I_EOPA_CURR <-> outer port VeLINR_I_EOPA_CURR
    delegate ApplLinComAb_LIN1.VeLINR_b_EOPA_CURR_TO <-> outer port VeLINR_b_EOPA_CURR_TO
    delegate ApplLinComAb_LIN1.VeLINR_e_EOPA_LOW_TMP_STAT <-> outer port VeLINR_e_EOPA_LOW_TMP_STAT
    delegate ApplLinComAb_LIN1.VeLINR_b_EOPA_LOW_TMP_STAT_TO <-> outer port VeLINR_b_EOPA_LOW_TMP_STAT_TO
    delegate ApplLinComAb_LIN1.VeLINR_e_EOPA_MONTRNG_RPM <-> outer port VeLINR_e_EOPA_MONTRNG_RPM
    delegate ApplLinComAb_LIN1.VeLINR_b_EOPA_MONTRNG_RPM_TO <-> outer port VeLINR_b_EOPA_MONTRNG_RPM_TO
    delegate ApplLinComAb_LIN1.VeLINR_e_EOPA_LMP_HM_AN_ON <-> outer port VeLINR_e_EOPA_LMP_HM_AN_ON
    delegate ApplLinComAb_LIN1.VeLINR_b_EOPA_LMP_HM_AN_ON_TO <-> outer port VeLINR_b_EOPA_LMP_HM_AN_ON_TO
    delegate ApplLinComAb_LIN1.VeLINR_e_EOPA_OV_TMP_ER <-> outer port VeLINR_e_EOPA_OV_TMP_ER
    delegate ApplLinComAb_LIN1.VeLINR_b_EOPA_OV_TMP_ER_TO <-> outer port VeLINR_b_EOPA_OV_TMP_ER_TO
    delegate ApplLinComAb_LIN1.VeLINR_e_EOPA_OV_CUR_ER <-> outer port VeLINR_e_EOPA_OV_CUR_ER
    delegate ApplLinComAb_LIN1.VeLINR_b_EOPA_OV_CUR_ER_TO <-> outer port VeLINR_b_EOPA_OV_CUR_ER_TO
    delegate ApplLinComAb_LIN1.VeLINR_e_EOPA_DR_RN_ER <-> outer port VeLINR_e_EOPA_DR_RN_ER
    delegate ApplLinComAb_LIN1.VeLINR_b_EOPA_DR_RN_ER_TO <-> outer port VeLINR_b_EOPA_DR_RN_ER_TO
    delegate ApplLinComAb_LIN1.VeLINR_e_EOPA_VLTG_ER <-> outer port VeLINR_e_EOPA_VLTG_ER
    delegate ApplLinComAb_LIN1.VeLINR_b_EOPA_VLTG_ER_TO <-> outer port VeLINR_b_EOPA_VLTG_ER_TO
    delegate ApplLinComAb_LIN1.VeLINR_e_EOPA_Stall_Event <-> outer port VeLINR_e_EOPA_Stall_Event
    delegate ApplLinComAb_LIN1.VeLINR_b_EOPA_Stall_EventTO <-> outer port VeLINR_b_EOPA_Stall_EventTO
    delegate ApplLinComAb_LIN1.VeLINR_e_EOPA_POST_RUN_STAT <-> outer port VeLINR_e_EOPA_POST_RUN_STAT
    delegate ApplLinComAb_LIN1.VeLINR_b_EOPA_POST_RUN_STAT_TO <-> outer port VeLINR_b_EOPA_POST_RUN_STAT_TO
    delegate ApplLinComAb_LIN1.VeLINR_b_RsErr_EOPA <-> outer port VeLINR_b_RsErr_EOPA
    delegate ApplLinComAb_LIN1.VeLINR_b_RsErr_EOPA_TO <-> outer port VeLINR_b_RsErr_EOPA_TO
    delegate ApplLinComAb_LIN1.VeLINR_T_EOPA_OIL_TEMP <-> outer port VeLINR_T_EOPA_OIL_TEMP
    delegate ApplLinComAb_LIN1.VeLINR_b_EOPA_OIL_TEMP_TO <-> outer port VeLINR_b_EOPA_OIL_TEMP_TO
    delegate ApplLinComAb_LIN1.VeLINR_y_EOPA_HW_VER <-> outer port VeLINR_y_EOPA_HW_VER
    delegate ApplLinComAb_LIN1.VeLINR_b_EOPA_HW_VER_TO <-> outer port VeLINR_b_EOPA_HW_VER_TO
    delegate ApplLinComAb_LIN1.VeLINR_y_EOPA_SW_VER <-> outer port VeLINR_y_EOPA_SW_VER
    delegate ApplLinComAb_LIN1.VeLINR_b_EOPA_SW_VER_TO <-> outer port VeLINR_b_EOPA_SW_VER_TO
    delegate ApplLinComAb_LIN1.VeLINR_Pct_LTRBV_PosAct <-> outer port VeLINR_Pct_LTRBV_PosAct
    delegate ApplLinComAb_LIN1.VeLINR_b_LTRBV_PosActTO <-> outer port VeLINR_b_LTRBV_PosActTO
    delegate ApplLinComAb_LIN1.VeLINR_e_LTRBV_ERR <-> outer port VeLINR_e_LTRBV_ERR
    delegate ApplLinComAb_LIN1.VeLINR_b_LTRBV_ERR_TO <-> outer port VeLINR_b_LTRBV_ERR_TO
    delegate ApplLinComAb_LIN1.VeLINR_U_LTRBV_MotorVolt <-> outer port VeLINR_U_LTRBV_MotorVolt
    delegate ApplLinComAb_LIN1.VeLINR_b_LTRBV_MotorVoltTO <-> outer port VeLINR_b_LTRBV_MotorVoltTO
    delegate ApplLinComAb_LIN1.VeLINR_e_LTRBV_Sts <-> outer port VeLINR_e_LTRBV_Sts
    delegate ApplLinComAb_LIN1.VeLINR_b_LTRBV_StsTO <-> outer port VeLINR_b_LTRBV_StsTO
    delegate ApplLinComAb_LIN1.VeLINR_b_RsErr_LTRBV <-> outer port VeLINR_b_RsErr_LTRBV
    delegate ApplLinComAb_LIN1.VeLINR_b_RsErr_LTRBV_TO <-> outer port VeLINR_b_RsErr_LTRBV_TO
    delegate ApplLinComAb_LIN1.SendLINR_AAD_PosRqVld <-> outer port SendLINR_AAD_PosRqVld
    delegate ApplLinComAb_LIN1.SendLINR_AAD_CalRqVld <-> outer port SendLINR_AAD_CalRqVld
    delegate ApplLinComAb_LIN1.SendLINR_AAD_InitialIP_CalRqVld <-> outer port SendLINR_AAD_InitialIP_CalRqVld
    delegate ApplLinComAb_LIN1.SendLINR_BCP_RPM_REQ_Vld <-> outer port SendLINR_BCP_RPM_REQ_Vld
    delegate ApplLinComAb_LIN1.SendLINR_BCP_POST_RUN_REQ_Vld <-> outer port SendLINR_BCP_POST_RUN_REQ_Vld
    delegate ApplLinComAb_LIN1.SendLINR_BCP_FL_SAFE_ACTVT_Vld <-> outer port SendLINR_BCP_FL_SAFE_ACTVT_Vld
    delegate ApplLinComAb_LIN1.SendLINR_CPV_PosRqVld <-> outer port SendLINR_CPV_PosRqVld
    delegate ApplLinComAb_LIN1.SendLINR_CPV_PosSvVld <-> outer port SendLINR_CPV_PosSvVld
    delegate ApplLinComAb_LIN1.SendLINR_CPV_CalRqVld <-> outer port SendLINR_CPV_CalRqVld
    delegate ApplLinComAb_LIN1.SendLINR_AirHeatrPwrTgtVld <-> outer port SendLINR_AirHeatrPwrTgtVld
    delegate ApplLinComAb_LIN1.SendLINR_AirHeatrEnadVld <-> outer port SendLINR_AirHeatrEnadVld
    delegate ApplLinComAb_LIN1.SendLINR_EOPA_RPM_COM_Vld <-> outer port SendLINR_EOPA_RPM_COM_Vld
    delegate ApplLinComAb_LIN1.SendLINR_EOPA_POST_RUN_COM_Vld <-> outer port SendLINR_EOPA_POST_RUN_COM_Vld
    delegate ApplLinComAb_LIN1.SendLINR_LTRBV_PosRqVld <-> outer port SendLINR_LTRBV_PosRqVld
    delegate ApplLinComAb_LIN1.SendLINR_LTRBV_PosSvVld <-> outer port SendLINR_LTRBV_PosSvVld
    delegate ApplLinComAb_LIN1.SendLINR_LTRBV_CalRqVld <-> outer port SendLINR_LTRBV_CalRqVld
    delegate ApplLinComAb_LIN2.VeLINR_y_AHP_VERSION <-> outer port VeLINR_y_AHP_VERSION
    delegate ApplLinComAb_LIN2.VeLINR_b_AHP_VERSION_TO <-> outer port VeLINR_b_AHP_VERSION_TO
    delegate ApplLinComAb_LIN2.VeLINR_y_PECP_VERSION <-> outer port VeLINR_y_PECP_VERSION
    delegate ApplLinComAb_LIN2.VeLINR_b_PECP_VERSION_TO <-> outer port VeLINR_b_PECP_VERSION_TO
    delegate ApplLinComAb_LIN1.VeLINR_U_CPV_MotorVolt <-> outer port VeLINR_U_CPV_MotorVolt
    delegate ApplLinComAb_LIN1.VeLINR_b_CPV_MotorVoltTO <-> outer port VeLINR_b_CPV_MotorVoltTO
    delegate ApplLinComAb_LIN1.VeLINR_e_CPV_CalStat <-> outer port VeLINR_e_CPV_CalStat
    delegate ApplLinComAb_LIN1.VeLINR_b_CPV_CalStatTO <-> outer port VeLINR_b_CPV_CalStatTO
    delegate ApplLinComAb_LIN1.VeLINR_e_AirHeatrSts <-> outer port VeLINR_e_AirHeatrSts
    delegate ApplLinComAb_LIN1.VeLINR_b_AirHeatrStsTO <-> outer port VeLINR_b_AirHeatrStsTO
    delegate ApplLinComAb_LIN1.VeLINR_Pct_AirHeatrPwrCns <-> outer port VeLINR_Pct_AirHeatrPwrCns
    delegate ApplLinComAb_LIN1.VeLINR_b_AirHeatrPwrCnsTO <-> outer port VeLINR_b_AirHeatrPwrCnsTO
    delegate ApplLinComAb_LIN1.VeLINR_Pct_EEXV_PosAct <-> outer port VeLINR_Pct_EEXV_PosAct
    delegate ApplLinComAb_LIN1.VeLINR_b_EEXV_PosActTO <-> outer port VeLINR_b_EEXV_PosActTO
    delegate ApplLinComAb_LIN1.VeLINR_e_EEXV_CalStat <-> outer port VeLINR_e_EEXV_CalStat
    delegate ApplLinComAb_LIN1.VeLINR_b_EEXV_CalStatTO <-> outer port VeLINR_b_EEXV_CalStatTO
    delegate ApplLinComAb_LIN1.VeLINR_b_EEXV_CalRq <-> outer port VeLINR_b_EEXV_CalRq
    delegate ApplLinComAb_LIN1.VeLINR_b_EEXV_CalRqTO <-> outer port VeLINR_b_EEXV_CalRqTO
    delegate ApplLinComAb_LIN1.VeLINR_b_RsErr_EEXV <-> outer port VeLINR_b_RsErr_EEXV
    delegate ApplLinComAb_LIN1.VeLINR_b_RsErr_EEXV_TO <-> outer port VeLINR_b_RsErr_EEXV_TO
    delegate ApplLinComAb_LIN1.VeLINR_e_EEXV_Sts <-> outer port VeLINR_e_EEXV_Sts
    delegate ApplLinComAb_LIN1.VeLINR_b_EEXV_StsTO <-> outer port VeLINR_b_EEXV_StsTO
    delegate ApplLinComAb_LIN1.VeLINR_e_EEXV_ERR <-> outer port VeLINR_e_EEXV_ERR
    delegate ApplLinComAb_LIN1.VeLINR_b_EEXV_ERR_TO <-> outer port VeLINR_b_EEXV_ERR_TO
    delegate ApplLinComAb_LIN1.VeLINR_U_EEXV_SupplyVolt <-> outer port VeLINR_U_EEXV_SupplyVolt
    delegate ApplLinComAb_LIN1.VeLINR_b_EEXV_SupplyVoltTO <-> outer port VeLINR_b_EEXV_SupplyVoltTO
    delegate ApplLinComAb_LIN1.VeLINR_e_EEXV_Refrig_Pressure <-> outer port VeLINR_e_EEXV_Refrig_Pressure
    delegate ApplLinComAb_LIN1.VeLINR_b_EEXV_Refrig_PressureTO <-> outer port VeLINR_b_EEXV_Refrig_PressureTO
    delegate ApplLinComAb_LIN1.VeLINR_T_EEXV_Board_Temp <-> outer port VeLINR_T_EEXV_Board_Temp
    delegate ApplLinComAb_LIN1.VeLINR_b_EEXV_Board_TempTO <-> outer port VeLINR_b_EEXV_Board_TempTO
    delegate ApplLinComAb_LIN1.VeLINR_e_EEXV_Refrigerant_Temp <-> outer port VeLINR_e_EEXV_Refrigerant_Temp
    delegate ApplLinComAb_LIN1.VeLINR_b_EEXV_Refrigerant_TempTO <-> outer port VeLINR_b_EEXV_Refrigerant_TempTO
    delegate ApplLinComAb_LIN1.VeLINR_Pct_EXVM_PosAct <-> outer port VeLINR_Pct_EXVM_PosAct
    delegate ApplLinComAb_LIN1.VeLINR_b_EXVM_PosActTO <-> outer port VeLINR_b_EXVM_PosActTO
    delegate ApplLinComAb_LIN1.VeLINR_e_EXVM_CalStat <-> outer port VeLINR_e_EXVM_CalStat
    delegate ApplLinComAb_LIN1.VeLINR_b_EXVM_CalStatTO <-> outer port VeLINR_b_EXVM_CalStatTO
    delegate ApplLinComAb_LIN1.VeLINR_b_EXVM_CalRq <-> outer port VeLINR_b_EXVM_CalRq
    delegate ApplLinComAb_LIN1.VeLINR_b_EXVM_CalRqTO <-> outer port VeLINR_b_EXVM_CalRqTO
    delegate ApplLinComAb_LIN1.VeLINR_b_RsErr_EXVM <-> outer port VeLINR_b_RsErr_EXVM
    delegate ApplLinComAb_LIN1.VeLINR_b_RsErr_EXVM_TO <-> outer port VeLINR_b_RsErr_EXVM_TO
    delegate ApplLinComAb_LIN1.VeLINR_e_EXVM_Sts <-> outer port VeLINR_e_EXVM_Sts
    delegate ApplLinComAb_LIN1.VeLINR_b_EXVM_StsTO <-> outer port VeLINR_b_EXVM_StsTO
    delegate ApplLinComAb_LIN1.VeLINR_e_EXVM_ERR <-> outer port VeLINR_e_EXVM_ERR
    delegate ApplLinComAb_LIN1.VeLINR_b_EXVM_ERR_TO <-> outer port VeLINR_b_EXVM_ERR_TO
    delegate ApplLinComAb_LIN1.VeLINR_U_EXVM_SupplyVolt <-> outer port VeLINR_U_EXVM_SupplyVolt
    delegate ApplLinComAb_LIN1.VeLINR_b_EXVM_SupplyVoltTO <-> outer port VeLINR_b_EXVM_SupplyVoltTO
    delegate ApplLinComAb_LIN1.VeLINR_e_EXVM_Refrig_Pressure <-> outer port VeLINR_e_EXVM_Refrig_Pressure
    delegate ApplLinComAb_LIN1.VeLINR_b_EXVM_Refrig_PressureTO <-> outer port VeLINR_b_EXVM_Refrig_PressureTO
    delegate ApplLinComAb_LIN1.VeLINR_T_EXVM_Board_Temp <-> outer port VeLINR_T_EXVM_Board_Temp
    delegate ApplLinComAb_LIN1.VeLINR_b_EXVM_Board_TempTO <-> outer port VeLINR_b_EXVM_Board_TempTO
    delegate ApplLinComAb_LIN1.VeLINR_e_EXVM_Refrigerant_Temp <-> outer port VeLINR_e_EXVM_Refrigerant_Temp
    delegate ApplLinComAb_LIN1.VeLINR_b_EXVM_Refrigerant_TempTO <-> outer port VeLINR_b_EXVM_Refrigerant_TempTO
    delegate ApplLinComAb_LIN1.VeLINR_e_LTRBV_CalStat <-> outer port VeLINR_e_LTRBV_CalStat
    delegate ApplLinComAb_LIN1.VeLINR_b_LTRBV_CalStatTO <-> outer port VeLINR_b_LTRBV_CalStatTO
    delegate ApplLinComAb_LIN1.SendLINR_EEXV_PosRq <-> outer port SendLINR_EEXV_PosRq
    delegate ApplLinComAb_LIN1.SendLINR_EEXV_PosRqVld <-> outer port SendLINR_EEXV_PosRqVld
    delegate ApplLinComAb_LIN1.SendLINR_EEXV_CalCmd <-> outer port SendLINR_EEXV_CalCmd
    delegate ApplLinComAb_LIN1.SendLINR_EEXV_CalCmdVld <-> outer port SendLINR_EEXV_CalCmdVld
    delegate ApplLinComAb_LIN1.SendLINR_EXVM_PosRq <-> outer port SendLINR_EXVM_PosRq
    delegate ApplLinComAb_LIN1.SendLINR_EXVM_PosRqVld <-> outer port SendLINR_EXVM_PosRqVld
    delegate ApplLinComAb_LIN1.SendLINR_EXVM_CalCmd <-> outer port SendLINR_EXVM_CalCmd
    delegate ApplLinComAb_LIN1.SendLINR_EXVM_CalCmdVld <-> outer port SendLINR_EXVM_CalCmdVld
    delegate ApplLinComAb_LIN2.VeLINR_e_S2MResByte1_AGS2 <-> outer port VeLINR_e_S2MResByte1_AGS2
    delegate ApplLinComAb_LIN2.VeLINR_b_S2MResByte1_AGS2TO <-> outer port VeLINR_b_S2MResByte1_AGS2TO
    delegate ApplLinComAb_LIN2.VeLINR_e_S2MResByte2_AGS2 <-> outer port VeLINR_e_S2MResByte2_AGS2
    delegate ApplLinComAb_LIN2.VeLINR_b_S2MResByte2_AGS2TO <-> outer port VeLINR_b_S2MResByte2_AGS2TO
    delegate ApplLinComAb_LIN2.VeLINR_U_BHV_MotorVolt <-> outer port VeLINR_U_BHV_MotorVolt
    delegate ApplLinComAb_LIN2.VeLINR_b_BHV_MotorVoltTO <-> outer port VeLINR_b_BHV_MotorVoltTO
    delegate ApplLinComAb_LIN2.VeLINR_e_BHV_CalStat <-> outer port VeLINR_e_BHV_CalStat
    delegate ApplLinComAb_LIN2.VeLINR_b_BHV_CalStatTO <-> outer port VeLINR_b_BHV_CalStatTO
    delegate ApplLinComAb_LIN2.VeLINR_Pct_OEXV_PosAct <-> outer port VeLINR_Pct_OEXV_PosAct
    delegate ApplLinComAb_LIN2.VeLINR_b_OEXV_PosActTO <-> outer port VeLINR_b_OEXV_PosActTO
    delegate ApplLinComAb_LIN2.VeLINR_e_OEXV_CalStat <-> outer port VeLINR_e_OEXV_CalStat
    delegate ApplLinComAb_LIN2.VeLINR_b_OEXV_CalStatTO <-> outer port VeLINR_b_OEXV_CalStatTO
    delegate ApplLinComAb_LIN2.VeLINR_b_OEXV_CalRq <-> outer port VeLINR_b_OEXV_CalRq
    delegate ApplLinComAb_LIN2.VeLINR_b_OEXV_CalRqTO <-> outer port VeLINR_b_OEXV_CalRqTO
    delegate ApplLinComAb_LIN2.VeLINR_b_RsErr_OEXV <-> outer port VeLINR_b_RsErr_OEXV
    delegate ApplLinComAb_LIN2.VeLINR_b_RsErr_OEXV_TO <-> outer port VeLINR_b_RsErr_OEXV_TO
    delegate ApplLinComAb_LIN2.VeLINR_e_OEXV_Sts <-> outer port VeLINR_e_OEXV_Sts
    delegate ApplLinComAb_LIN2.VeLINR_b_OEXV_StsTO <-> outer port VeLINR_b_OEXV_StsTO
    delegate ApplLinComAb_LIN2.VeLINR_e_OEXV_ERR <-> outer port VeLINR_e_OEXV_ERR
    delegate ApplLinComAb_LIN2.VeLINR_b_OEXV_ERR_TO <-> outer port VeLINR_b_OEXV_ERR_TO
    delegate ApplLinComAb_LIN2.VeLINR_U_OEXV_SupplyVolt <-> outer port VeLINR_U_OEXV_SupplyVolt
    delegate ApplLinComAb_LIN2.VeLINR_b_OEXV_SupplyVoltTO <-> outer port VeLINR_b_OEXV_SupplyVoltTO
    delegate ApplLinComAb_LIN2.VeLINR_e_OEXV_Refrig_Pres <-> outer port VeLINR_e_OEXV_Refrig_Pres
    delegate ApplLinComAb_LIN2.VeLINR_b_OEXV_Refrig_PresTO <-> outer port VeLINR_b_OEXV_Refrig_PresTO
    delegate ApplLinComAb_LIN2.VeLINR_T_OEXV_Board_Temp <-> outer port VeLINR_T_OEXV_Board_Temp
    delegate ApplLinComAb_LIN2.VeLINR_b_OEXV_Board_TempTO <-> outer port VeLINR_b_OEXV_Board_TempTO
    delegate ApplLinComAb_LIN2.VeLINR_e_OEXV_Refrigerant_Temp <-> outer port VeLINR_e_OEXV_Refrigerant_Temp
    delegate ApplLinComAb_LIN2.VeLINR_b_OEXV_Refrigerant_TempTO <-> outer port VeLINR_b_OEXV_Refrigerant_TempTO
    delegate ApplLinComAb_LIN2.SendLINR_OEXV_PosRq <-> outer port SendLINR_OEXV_PosRq
    delegate ApplLinComAb_LIN2.SendLINR_OEXV_PosRqVld <-> outer port SendLINR_OEXV_PosRqVld
    delegate ApplLinComAb_LIN2.SendLINR_OEXV_CalCmd <-> outer port SendLINR_OEXV_CalCmd
    delegate ApplLinComAb_LIN2.SendLINR_OEXV_CalCmdVld <-> outer port SendLINR_OEXV_CalCmdVld
    delegate ApplLinComAb_LIN3.VeLINR_e_AGS_CurrPos <-> outer port VeLINR_e_AGS_CurrPos
    delegate ApplLinComAb_LIN3.VeLINR_b_AGS_CurrPosTO <-> outer port VeLINR_b_AGS_CurrPosTO
    delegate ApplLinComAb_LIN3.VeLINR_b_AGS_CalStat <-> outer port VeLINR_b_AGS_CalStat
    delegate ApplLinComAb_LIN3.VeLINR_b_AGS_CalStatTO <-> outer port VeLINR_b_AGS_CalStatTO
    delegate ApplLinComAb_LIN3.VeLINR_b_AGS_CalActv <-> outer port VeLINR_b_AGS_CalActv
    delegate ApplLinComAb_LIN3.VeLINR_b_AGS_CalActvTO <-> outer port VeLINR_b_AGS_CalActvTO
    delegate ApplLinComAb_LIN3.VeLINR_b_AGS_ErrUnVolt <-> outer port VeLINR_b_AGS_ErrUnVolt
    delegate ApplLinComAb_LIN3.VeLINR_b_AGS_ErrUnVoltTO <-> outer port VeLINR_b_AGS_ErrUnVoltTO
    delegate ApplLinComAb_LIN3.VeLINR_b_AGS_ErrOvrVolt <-> outer port VeLINR_b_AGS_ErrOvrVolt
    delegate ApplLinComAb_LIN3.VeLINR_b_AGS_ErrOvrVoltTO <-> outer port VeLINR_b_AGS_ErrOvrVoltTO
    delegate ApplLinComAb_LIN3.VeLINR_b_AGS_ErrOvrTemp <-> outer port VeLINR_b_AGS_ErrOvrTemp
    delegate ApplLinComAb_LIN3.VeLINR_b_AGS_ErrOvrTempTO <-> outer port VeLINR_b_AGS_ErrOvrTempTO
    delegate ApplLinComAb_LIN3.VeLINR_b_AGS_ErrMechStuck <-> outer port VeLINR_b_AGS_ErrMechStuck
    delegate ApplLinComAb_LIN3.VeLINR_b_AGS_ErrMechStuckTO <-> outer port VeLINR_b_AGS_ErrMechStuckTO
    delegate ApplLinComAb_LIN3.VeLINR_b_AGS_ErrMechBreak <-> outer port VeLINR_b_AGS_ErrMechBreak
    delegate ApplLinComAb_LIN3.VeLINR_b_AGS_ErrMechBreakTO <-> outer port VeLINR_b_AGS_ErrMechBreakTO
    delegate ApplLinComAb_LIN3.VeLINR_e_AGS_ErrLIN <-> outer port VeLINR_e_AGS_ErrLIN
    delegate ApplLinComAb_LIN3.VeLINR_b_AGS_ErrLIN_TO <-> outer port VeLINR_b_AGS_ErrLIN_TO
    delegate ApplLinComAb_LIN3.VeLINR_b_RsErr_AGS <-> outer port VeLINR_b_RsErr_AGS
    delegate ApplLinComAb_LIN3.VeLINR_b_RsErr_AGS_TO <-> outer port VeLINR_b_RsErr_AGS_TO
    delegate ApplLinComAb_LIN3.VeLINR_b_AGS_BoostStat <-> outer port VeLINR_b_AGS_BoostStat
    delegate ApplLinComAb_LIN3.VeLINR_b_AGS_BoostStatTO <-> outer port VeLINR_b_AGS_BoostStatTO
    delegate ApplLinComAb_LIN3.VeLINR_b_S2MRes1Bit <-> outer port VeLINR_b_S2MRes1Bit
    delegate ApplLinComAb_LIN3.VeLINR_b_S2MRes1BitTO <-> outer port VeLINR_b_S2MRes1BitTO
    delegate ApplLinComAb_LIN3.VeLINR_e_S2MResByte1 <-> outer port VeLINR_e_S2MResByte1
    delegate ApplLinComAb_LIN3.VeLINR_b_S2MResByte1TO <-> outer port VeLINR_b_S2MResByte1TO
    delegate ApplLinComAb_LIN3.VeLINR_e_S2MResByte2 <-> outer port VeLINR_e_S2MResByte2
    delegate ApplLinComAb_LIN3.VeLINR_b_S2MResByte2TO <-> outer port VeLINR_b_S2MResByte2TO
    delegate ApplLinComAb_LIN3.VeLINR_Pct_CEXV_PosAct <-> outer port VeLINR_Pct_CEXV_PosAct
    delegate ApplLinComAb_LIN3.VeLINR_b_CEXV_PosActTO <-> outer port VeLINR_b_CEXV_PosActTO
    delegate ApplLinComAb_LIN3.VeLINR_e_CEXV_CalStat <-> outer port VeLINR_e_CEXV_CalStat
    delegate ApplLinComAb_LIN3.VeLINR_b_CEXV_CalStatTO <-> outer port VeLINR_b_CEXV_CalStatTO
    delegate ApplLinComAb_LIN3.VeLINR_b_CEXV_CalRq <-> outer port VeLINR_b_CEXV_CalRq
    delegate ApplLinComAb_LIN3.VeLINR_b_CEXV_CalRqTO <-> outer port VeLINR_b_CEXV_CalRqTO
    delegate ApplLinComAb_LIN3.VeLINR_b_RsErr_CEXV <-> outer port VeLINR_b_RsErr_CEXV
    delegate ApplLinComAb_LIN3.VeLINR_b_RsErr_CEXV_TO <-> outer port VeLINR_b_RsErr_CEXV_TO
    delegate ApplLinComAb_LIN3.VeLINR_e_CEXV_Sts <-> outer port VeLINR_e_CEXV_Sts
    delegate ApplLinComAb_LIN3.VeLINR_b_CEXV_StsTO <-> outer port VeLINR_b_CEXV_StsTO
    delegate ApplLinComAb_LIN3.VeLINR_e_CEXV_ERR <-> outer port VeLINR_e_CEXV_ERR
    delegate ApplLinComAb_LIN3.VeLINR_b_CEXV_ERR_TO <-> outer port VeLINR_b_CEXV_ERR_TO
    delegate ApplLinComAb_LIN3.VeLINR_U_CEXV_SupplyVolt <-> outer port VeLINR_U_CEXV_SupplyVolt
    delegate ApplLinComAb_LIN3.VeLINR_b_CEXV_SupplyVoltTO <-> outer port VeLINR_b_CEXV_SupplyVoltTO
    delegate ApplLinComAb_LIN3.VeLINR_e_CEXV_Refrigerant_Press <-> outer port VeLINR_e_CEXV_Refrigerant_Press
    delegate ApplLinComAb_LIN3.VeLINR_b_CEXV_Refrigerant_PressTO <-> outer port VeLINR_b_CEXV_Refrigerant_PressTO
    delegate ApplLinComAb_LIN3.VeLINR_T_CEXV_Board_Temp <-> outer port VeLINR_T_CEXV_Board_Temp
    delegate ApplLinComAb_LIN3.VeLINR_b_CEXV_Board_TempTO <-> outer port VeLINR_b_CEXV_Board_TempTO
    delegate ApplLinComAb_LIN3.VeLINR_e_CEXV_Refrigerant_Temp <-> outer port VeLINR_e_CEXV_Refrigerant_Temp
    delegate ApplLinComAb_LIN3.VeLINR_b_CEXV_Refrigerant_TempTO <-> outer port VeLINR_b_CEXV_Refrigerant_TempTO
    delegate ApplLinComAb_LIN3.VeLINR_e_Inlet_Temp1_DC <-> outer port VeLINR_e_Inlet_Temp1_DC
    delegate ApplLinComAb_LIN3.VeLINR_b_Inlet_Temp1_DC_TO <-> outer port VeLINR_b_Inlet_Temp1_DC_TO
    delegate ApplLinComAb_LIN3.VeLINR_e_Inlet_Temp2_DC <-> outer port VeLINR_e_Inlet_Temp2_DC
    delegate ApplLinComAb_LIN3.VeLINR_b_Inlet_Temp2_DC_TO <-> outer port VeLINR_b_Inlet_Temp2_DC_TO
    delegate ApplLinComAb_LIN3.VeLINR_e_CPIM_IND1_Fdbk <-> outer port VeLINR_e_CPIM_IND1_Fdbk
    delegate ApplLinComAb_LIN3.VeLINR_b_CPIM_IND1_FdbkTO <-> outer port VeLINR_b_CPIM_IND1_FdbkTO
    delegate ApplLinComAb_LIN3.VeLINR_e_CPIM_IND2_Fdbk <-> outer port VeLINR_e_CPIM_IND2_Fdbk
    delegate ApplLinComAb_LIN3.VeLINR_b_CPIM_IND2_FdbkTO <-> outer port VeLINR_b_CPIM_IND2_FdbkTO
    delegate ApplLinComAb_LIN3.VeLINR_e_CPIM_IND3_Fdbk <-> outer port VeLINR_e_CPIM_IND3_Fdbk
    delegate ApplLinComAb_LIN3.VeLINR_b_CPIM_IND3_FdbkTO <-> outer port VeLINR_b_CPIM_IND3_FdbkTO
    delegate ApplLinComAb_LIN3.VeLINR_e_CPIM_IND4_Fdbk <-> outer port VeLINR_e_CPIM_IND4_Fdbk
    delegate ApplLinComAb_LIN3.VeLINR_b_CPIM_IND4_FdbkTO <-> outer port VeLINR_b_CPIM_IND4_FdbkTO
    delegate ApplLinComAb_LIN3.VeLINR_e_CPIM_IND5_Fdbk <-> outer port VeLINR_e_CPIM_IND5_Fdbk
    delegate ApplLinComAb_LIN3.VeLINR_b_CPIM_IND5_FdbkTO <-> outer port VeLINR_b_CPIM_IND5_FdbkTO
    delegate ApplLinComAb_LIN3.VeLINR_e_CPIM_IND_Color_Fdbk <-> outer port VeLINR_e_CPIM_IND_Color_Fdbk
    delegate ApplLinComAb_LIN3.VeLINR_b_CPIM_IND_Color_FdbkTO <-> outer port VeLINR_b_CPIM_IND_Color_FdbkTO
    delegate ApplLinComAb_LIN3.VeLINR_e_CPIM_IND1_FailSts <-> outer port VeLINR_e_CPIM_IND1_FailSts
    delegate ApplLinComAb_LIN3.VeLINR_b_CPIM_IND1_FailStsTO <-> outer port VeLINR_b_CPIM_IND1_FailStsTO
    delegate ApplLinComAb_LIN3.VeLINR_e_CPIM_IND2_FailSts <-> outer port VeLINR_e_CPIM_IND2_FailSts
    delegate ApplLinComAb_LIN3.VeLINR_b_CPIM_IND2_FailStsTO <-> outer port VeLINR_b_CPIM_IND2_FailStsTO
    delegate ApplLinComAb_LIN3.VeLINR_e_CPIM_IND3_FailSts <-> outer port VeLINR_e_CPIM_IND3_FailSts
    delegate ApplLinComAb_LIN3.VeLINR_b_CPIM_IND3_FailStsTO <-> outer port VeLINR_b_CPIM_IND3_FailStsTO
    delegate ApplLinComAb_LIN3.VeLINR_e_CPIM_IND4_FailSts <-> outer port VeLINR_e_CPIM_IND4_FailSts
    delegate ApplLinComAb_LIN3.VeLINR_b_CPIM_IND4_FailStsTO <-> outer port VeLINR_b_CPIM_IND4_FailStsTO
    delegate ApplLinComAb_LIN3.VeLINR_e_CPIM_IND5_FailSts <-> outer port VeLINR_e_CPIM_IND5_FailSts
    delegate ApplLinComAb_LIN3.VeLINR_b_CPIM_IND5_FailStsTO <-> outer port VeLINR_b_CPIM_IND5_FailStsTO
    delegate ApplLinComAb_LIN3.VeLINR_b_CPIM_Undervoltage <-> outer port VeLINR_b_CPIM_Undervoltage
    delegate ApplLinComAb_LIN3.VeLINR_b_CPIM_UndervoltageTO <-> outer port VeLINR_b_CPIM_UndervoltageTO
    delegate ApplLinComAb_LIN3.VeLINR_b_CPIM_Over_Temperature <-> outer port VeLINR_b_CPIM_Over_Temperature
    delegate ApplLinComAb_LIN3.VeLINR_b_CPIM_Over_TemperatureTO <-> outer port VeLINR_b_CPIM_Over_TemperatureTO
    delegate ApplLinComAb_LIN3.VeLINR_b_CPIM_LIN_Parity_Error <-> outer port VeLINR_b_CPIM_LIN_Parity_Error
    delegate ApplLinComAb_LIN3.VeLINR_b_CPIM_LIN_Parity_ErrorTO <-> outer port VeLINR_b_CPIM_LIN_Parity_ErrorTO
    delegate ApplLinComAb_LIN3.VeLINR_b_CPIM_LIN_ChecksumError <-> outer port VeLINR_b_CPIM_LIN_ChecksumError
    delegate ApplLinComAb_LIN3.VeLINR_b_CPIM_LIN_ChecksumErrorTO <-> outer port VeLINR_b_CPIM_LIN_ChecksumErrorTO
    delegate ApplLinComAb_LIN3.VeLINR_b_CPIM_LIN_Data_Error <-> outer port VeLINR_b_CPIM_LIN_Data_Error
    delegate ApplLinComAb_LIN3.VeLINR_b_CPIM_LIN_Data_ErrorTO <-> outer port VeLINR_b_CPIM_LIN_Data_ErrorTO
    delegate ApplLinComAb_LIN3.VeLINR_b_ChrgPortLock_Sts <-> outer port VeLINR_b_ChrgPortLock_Sts
    delegate ApplLinComAb_LIN3.VeLINR_b_ChrgPortLock_StsTO <-> outer port VeLINR_b_ChrgPortLock_StsTO
    delegate ApplLinComAb_LIN3.VeLINR_b_ChrgPortButton_Sts <-> outer port VeLINR_b_ChrgPortButton_Sts
    delegate ApplLinComAb_LIN3.VeLINR_b_ChrgPortButton_StsTO <-> outer port VeLINR_b_ChrgPortButton_StsTO
    delegate ApplLinComAb_LIN3.VeLINR_e_Ambient_Temp <-> outer port VeLINR_e_Ambient_Temp
    delegate ApplLinComAb_LIN3.VeLINR_b_Ambient_TempTO <-> outer port VeLINR_b_Ambient_TempTO
    delegate ApplLinComAb_LIN3.VeLINR_e_Chrg_Inlet_Temp <-> outer port VeLINR_e_Chrg_Inlet_Temp
    delegate ApplLinComAb_LIN3.VeLINR_b_Chrg_Inlet_TempTO <-> outer port VeLINR_b_Chrg_Inlet_TempTO
    delegate ApplLinComAb_LIN3.VeLINR_b_ResponseErrorStsCPIM <-> outer port VeLINR_b_ResponseErrorStsCPIM
    delegate ApplLinComAb_LIN3.VeLINR_b_ResponseErrorStsCPIM_TO <-> outer port VeLINR_b_ResponseErrorStsCPIM_TO
    delegate ApplLinComAb_LIN3.VeLINR_e_ChrgPortLock_FailSts <-> outer port VeLINR_e_ChrgPortLock_FailSts
    delegate ApplLinComAb_LIN3.VeLINR_b_ChrgPortLock_FailStsTO <-> outer port VeLINR_b_ChrgPortLock_FailStsTO
    delegate ApplLinComAb_LIN3.VeLINR_e_Icon1_Sts <-> outer port VeLINR_e_Icon1_Sts
    delegate ApplLinComAb_LIN3.VeLINR_b_Icon1_StsTO <-> outer port VeLINR_b_Icon1_StsTO
    delegate ApplLinComAb_LIN3.VeLINR_b_Icon1_FailSts <-> outer port VeLINR_b_Icon1_FailSts
    delegate ApplLinComAb_LIN3.VeLINR_b_Icon1_FailStsTO <-> outer port VeLINR_b_Icon1_FailStsTO
    delegate ApplLinComAb_LIN3.VeLINR_e_Icon2_Sts <-> outer port VeLINR_e_Icon2_Sts
    delegate ApplLinComAb_LIN3.VeLINR_b_Icon2_StsTO <-> outer port VeLINR_b_Icon2_StsTO
    delegate ApplLinComAb_LIN3.VeLINR_b_Icon2_FailSts <-> outer port VeLINR_b_Icon2_FailSts
    delegate ApplLinComAb_LIN3.VeLINR_b_Icon2_FailStsTO <-> outer port VeLINR_b_Icon2_FailStsTO
    delegate ApplLinComAb_LIN3.VeLINR_e_ChrgPortDoor_Sts <-> outer port VeLINR_e_ChrgPortDoor_Sts
    delegate ApplLinComAb_LIN3.VeLINR_b_ChrgPortDoor_StsTO <-> outer port VeLINR_b_ChrgPortDoor_StsTO
    delegate ApplLinComAb_LIN3.VeLINR_e_HvCooltHeatrSts <-> outer port VeLINR_e_HvCooltHeatrSts
    delegate ApplLinComAb_LIN3.VeLINR_b_HvCooltHeatrStsTO <-> outer port VeLINR_b_HvCooltHeatrStsTO
    delegate ApplLinComAb_LIN3.VeLINR_e_ECH_InterlockStat <-> outer port VeLINR_e_ECH_InterlockStat
    delegate ApplLinComAb_LIN3.VeLINR_b_ECH_InterlockStatTO <-> outer port VeLINR_b_ECH_InterlockStatTO
    delegate ApplLinComAb_LIN3.VeLINR_e_Below_60V <-> outer port VeLINR_e_Below_60V
    delegate ApplLinComAb_LIN3.VeLINR_b_Below_60V_TO <-> outer port VeLINR_b_Below_60V_TO
    delegate ApplLinComAb_LIN3.VeLINR_T_HvCltWtrHtrWtrTInIntk <-> outer port VeLINR_T_HvCltWtrHtrWtrTInIntk
    delegate ApplLinComAb_LIN3.VeLINR_b_HvCltWtrHtrWtrTInIntkTO <-> outer port VeLINR_b_HvCltWtrHtrWtrTInIntkTO
    delegate ApplLinComAb_LIN3.VeLINR_T_HvWtrHeatrWtrT <-> outer port VeLINR_T_HvWtrHeatrWtrT
    delegate ApplLinComAb_LIN3.VeLINR_b_HvWtrHeatrWtrT_TO <-> outer port VeLINR_b_HvWtrHeatrWtrT_TO
    delegate ApplLinComAb_LIN3.VeLINR_I_HvCooltHeatrICns <-> outer port VeLINR_I_HvCooltHeatrICns
    delegate ApplLinComAb_LIN3.VeLINR_b_HvCooltHeatrICnsTO <-> outer port VeLINR_b_HvCooltHeatrICnsTO
    delegate ApplLinComAb_LIN3.VeLINR_U_HvCooltHVmeas <-> outer port VeLINR_U_HvCooltHVmeas
    delegate ApplLinComAb_LIN3.VeLINR_b_HvCooltHVmeasTO <-> outer port VeLINR_b_HvCooltHVmeasTO
    delegate ApplLinComAb_LIN3.VeLINR_P_HvHeatrPwrCns <-> outer port VeLINR_P_HvHeatrPwrCns
    delegate ApplLinComAb_LIN3.VeLINR_b_HvHeatrPwrCnsTO <-> outer port VeLINR_b_HvHeatrPwrCnsTO
    delegate ApplLinComAb_LIN3.VeLINR_P_HvHeatrPwrCnsDes <-> outer port VeLINR_P_HvHeatrPwrCnsDes
    delegate ApplLinComAb_LIN3.VeLINR_b_HvHeatrPwrCnsDesTO <-> outer port VeLINR_b_HvHeatrPwrCnsDesTO
    delegate ApplLinComAb_LIN3.VeLINR_e_HVH_UnlockCounter <-> outer port VeLINR_e_HVH_UnlockCounter
    delegate ApplLinComAb_LIN3.VeLINR_b_HVH_UnlockCounterTO <-> outer port VeLINR_b_HVH_UnlockCounterTO
    delegate ApplLinComAb_LIN3.VeLINR_b_RsErr_ECH <-> outer port VeLINR_b_RsErr_ECH
    delegate ApplLinComAb_LIN3.VeLINR_b_RsErr_ECH_TO <-> outer port VeLINR_b_RsErr_ECH_TO
    delegate ApplLinComAb_LIN3.VeLINR_e_HvCltHtrWrnFltInCom <-> outer port VeLINR_e_HvCltHtrWrnFltInCom
    delegate ApplLinComAb_LIN3.VeLINR_b_HvCltHtrWrnFltInComTO <-> outer port VeLINR_b_HvCltHtrWrnFltInComTO
    delegate ApplLinComAb_LIN3.VeLINR_e_HvCltHtrWrnHvOtOfRng <-> outer port VeLINR_e_HvCltHtrWrnHvOtOfRng
    delegate ApplLinComAb_LIN3.VeLINR_b_HvCltHtrWrnHvOtOfRngTO <-> outer port VeLINR_b_HvCltHtrWrnHvOtOfRngTO
    delegate ApplLinComAb_LIN3.VeLINR_e_HvCltHtrWrnULoOtOfRng <-> outer port VeLINR_e_HvCltHtrWrnULoOtOfRng
    delegate ApplLinComAb_LIN3.VeLINR_b_HvCltHtrWrnULoOtOfRngTO <-> outer port VeLINR_b_HvCltHtrWrnULoOtOfRngTO
    delegate ApplLinComAb_LIN3.VeLINR_e_HvCltHtrWrnCltTOtOfRng <-> outer port VeLINR_e_HvCltHtrWrnCltTOtOfRng
    delegate ApplLinComAb_LIN3.VeLINR_b_HvCltHtrWrnCltTOtOfRngTO <-> outer port VeLINR_b_HvCltHtrWrnCltTOtOfRngTO
    delegate ApplLinComAb_LIN3.VeLINR_e_HvCltHrPrtnSfTmpHwPrtn <-> outer port VeLINR_e_HvCltHrPrtnSfTmpHwPrtn
    delegate ApplLinComAb_LIN3.VeLINR_b_HvCltHrPrtnSfTmpHwPrtnTO <-> outer port VeLINR_b_HvCltHrPrtnSfTmpHwPrtnTO
    delegate ApplLinComAb_LIN3.VeLINR_e_HvCltHrPrtnSfTmpOvrhtg <-> outer port VeLINR_e_HvCltHrPrtnSfTmpOvrhtg
    delegate ApplLinComAb_LIN3.VeLINR_b_HvCltHrPrtnSfTmpOvrhtgTO <-> outer port VeLINR_b_HvCltHrPrtnSfTmpOvrhtgTO
    delegate ApplLinComAb_LIN3.VeLINR_e_HClHrSrFtClTInSnFlt <-> outer port VeLINR_e_HClHrSrFtClTInSnFlt
    delegate ApplLinComAb_LIN3.VeLINR_b_HClHrSrFtClTInSnFltTO <-> outer port VeLINR_b_HClHrSrFtClTInSnFltTO
    delegate ApplLinComAb_LIN3.VeLINR_e_HClHrSrFtClTOtSnFlt <-> outer port VeLINR_e_HClHrSrFtClTOtSnFlt
    delegate ApplLinComAb_LIN3.VeLINR_b_HClHrSrFtClTOtSnFltTO <-> outer port VeLINR_b_HClHrSrFtClTOtSnFltTO
    delegate ApplLinComAb_LIN3.VeLINR_e_HClHrSrFtTInMtrlSnFlt <-> outer port VeLINR_e_HClHrSrFtTInMtrlSnFlt
    delegate ApplLinComAb_LIN3.VeLINR_b_HClHrSrFtTInMtrlSnFltTO <-> outer port VeLINR_b_HClHrSrFtTInMtrlSnFltTO
    delegate ApplLinComAb_LIN3.VeLINR_e_HClHrSrRqCrFrDrShOrOp <-> outer port VeLINR_e_HClHrSrRqCrFrDrShOrOp
    delegate ApplLinComAb_LIN3.VeLINR_b_HClHrSrRqCrFrDrShOrOpTO <-> outer port VeLINR_b_HClHrSrRqCrFrDrShOrOpTO
    delegate ApplLinComAb_LIN3.VeLINR_e_HClHrSrRqICnsOtOfRng <-> outer port VeLINR_e_HClHrSrRqICnsOtOfRng
    delegate ApplLinComAb_LIN3.VeLINR_b_HClHrSrRqICnsOtOfRngTO <-> outer port VeLINR_b_HClHrSrRqICnsOtOfRngTO
    delegate ApplLinComAb_LIN3.VeLINR_e_HClHrSrRqMemErr <-> outer port VeLINR_e_HClHrSrRqMemErr
    delegate ApplLinComAb_LIN3.VeLINR_b_HClHrSrRqMemErrTO <-> outer port VeLINR_b_HClHrSrRqMemErrTO
    delegate ApplLinComAb_LIN3.VeLINR_e_HClHrSrRqSrvRq <-> outer port VeLINR_e_HClHrSrRqSrvRq
    delegate ApplLinComAb_LIN3.VeLINR_b_HClHrSrRqSrvRqTO <-> outer port VeLINR_b_HClHrSrRqSrvRqTO
    delegate ApplLinComAb_LIN3.VeLINR_e_EOPB_RPM_TGT <-> outer port VeLINR_e_EOPB_RPM_TGT
    delegate ApplLinComAb_LIN3.VeLINR_b_EOPB_RPM_TGT_TO <-> outer port VeLINR_b_EOPB_RPM_TGT_TO
    delegate ApplLinComAb_LIN3.VeLINR_e_EOPB_RPM_ACTL <-> outer port VeLINR_e_EOPB_RPM_ACTL
    delegate ApplLinComAb_LIN3.VeLINR_b_EOPB_RPM_ACTL_TO <-> outer port VeLINR_b_EOPB_RPM_ACTL_TO
    delegate ApplLinComAb_LIN3.VeLINR_U_EOPB_VLTG <-> outer port VeLINR_U_EOPB_VLTG
    delegate ApplLinComAb_LIN3.VeLINR_b_EOPB_VLTG_TO <-> outer port VeLINR_b_EOPB_VLTG_TO
    delegate ApplLinComAb_LIN3.VeLINR_T_EOPB_TEMP <-> outer port VeLINR_T_EOPB_TEMP
    delegate ApplLinComAb_LIN3.VeLINR_b_EOPB_TEMP_TO <-> outer port VeLINR_b_EOPB_TEMP_TO
    delegate ApplLinComAb_LIN3.VeLINR_I_EOPB_CURR <-> outer port VeLINR_I_EOPB_CURR
    delegate ApplLinComAb_LIN3.VeLINR_b_EOPB_CURR_TO <-> outer port VeLINR_b_EOPB_CURR_TO
    delegate ApplLinComAb_LIN3.VeLINR_e_EOPB_LOW_TMP_STAT <-> outer port VeLINR_e_EOPB_LOW_TMP_STAT
    delegate ApplLinComAb_LIN3.VeLINR_b_EOPB_LOW_TMP_STAT_TO <-> outer port VeLINR_b_EOPB_LOW_TMP_STAT_TO
    delegate ApplLinComAb_LIN3.VeLINR_e_EOPB_MONTRNG_RPM <-> outer port VeLINR_e_EOPB_MONTRNG_RPM
    delegate ApplLinComAb_LIN3.VeLINR_b_EOPB_MONTRNG_RPM_TO <-> outer port VeLINR_b_EOPB_MONTRNG_RPM_TO
    delegate ApplLinComAb_LIN3.VeLINR_e_EOPB_LMP_HM_AN_ON <-> outer port VeLINR_e_EOPB_LMP_HM_AN_ON
    delegate ApplLinComAb_LIN3.VeLINR_b_EOPB_LMP_HM_AN_ON_TO <-> outer port VeLINR_b_EOPB_LMP_HM_AN_ON_TO
    delegate ApplLinComAb_LIN3.VeLINR_e_EOPB_OV_TMP_ER <-> outer port VeLINR_e_EOPB_OV_TMP_ER
    delegate ApplLinComAb_LIN3.VeLINR_b_EOPB_OV_TMP_ER_TO <-> outer port VeLINR_b_EOPB_OV_TMP_ER_TO
    delegate ApplLinComAb_LIN3.VeLINR_e_EOPB_OV_CUR_ER <-> outer port VeLINR_e_EOPB_OV_CUR_ER
    delegate ApplLinComAb_LIN3.VeLINR_b_EOPB_OV_CUR_ER_TO <-> outer port VeLINR_b_EOPB_OV_CUR_ER_TO
    delegate ApplLinComAb_LIN3.VeLINR_e_EOPB_DR_RN_ER <-> outer port VeLINR_e_EOPB_DR_RN_ER
    delegate ApplLinComAb_LIN3.VeLINR_b_EOPB_DR_RN_ER_TO <-> outer port VeLINR_b_EOPB_DR_RN_ER_TO
    delegate ApplLinComAb_LIN3.VeLINR_e_EOPB_VLTG_ER <-> outer port VeLINR_e_EOPB_VLTG_ER
    delegate ApplLinComAb_LIN3.VeLINR_b_EOPB_VLTG_ER_TO <-> outer port VeLINR_b_EOPB_VLTG_ER_TO
    delegate ApplLinComAb_LIN3.VeLINR_e_EOPB_Stall_Event <-> outer port VeLINR_e_EOPB_Stall_Event
    delegate ApplLinComAb_LIN3.VeLINR_b_EOPB_Stall_EventTO <-> outer port VeLINR_b_EOPB_Stall_EventTO
    delegate ApplLinComAb_LIN3.VeLINR_e_EOPB_POST_RUN_STAT <-> outer port VeLINR_e_EOPB_POST_RUN_STAT
    delegate ApplLinComAb_LIN3.VeLINR_b_EOPB_POST_RUN_STAT_TO <-> outer port VeLINR_b_EOPB_POST_RUN_STAT_TO
    delegate ApplLinComAb_LIN3.VeLINR_b_RsErr_EOPB <-> outer port VeLINR_b_RsErr_EOPB
    delegate ApplLinComAb_LIN3.VeLINR_b_RsErr_EOPB_TO <-> outer port VeLINR_b_RsErr_EOPB_TO
    delegate ApplLinComAb_LIN3.VeLINR_T_EOPB_OIL_TEMP <-> outer port VeLINR_T_EOPB_OIL_TEMP
    delegate ApplLinComAb_LIN3.VeLINR_b_EOPB_OIL_TEMP_TO <-> outer port VeLINR_b_EOPB_OIL_TEMP_TO
    delegate ApplLinComAb_LIN3.VeLINR_y_EOPB_HW_VER <-> outer port VeLINR_y_EOPB_HW_VER
    delegate ApplLinComAb_LIN3.VeLINR_b_EOPB_HW_VER_TO <-> outer port VeLINR_b_EOPB_HW_VER_TO
    delegate ApplLinComAb_LIN3.VeLINR_y_EOPB_SW_VER <-> outer port VeLINR_y_EOPB_SW_VER
    delegate ApplLinComAb_LIN3.VeLINR_b_EOPB_SW_VER_TO <-> outer port VeLINR_b_EOPB_SW_VER_TO
    delegate ApplLinComAb_LIN3.VeLINR_Pct_HTLBV_PosAct <-> outer port VeLINR_Pct_HTLBV_PosAct
    delegate ApplLinComAb_LIN3.VeLINR_b_HTLBV_PosActTO <-> outer port VeLINR_b_HTLBV_PosActTO
    delegate ApplLinComAb_LIN3.VeLINR_e_HTLBV_ERR <-> outer port VeLINR_e_HTLBV_ERR
    delegate ApplLinComAb_LIN3.VeLINR_b_HTLBV_ERR_TO <-> outer port VeLINR_b_HTLBV_ERR_TO
    delegate ApplLinComAb_LIN3.VeLINR_U_HTLBV_MotorVolt <-> outer port VeLINR_U_HTLBV_MotorVolt
    delegate ApplLinComAb_LIN3.VeLINR_b_HTLBV_MotorVoltTO <-> outer port VeLINR_b_HTLBV_MotorVoltTO
    delegate ApplLinComAb_LIN3.VeLINR_e_HTLBV_Sts <-> outer port VeLINR_e_HTLBV_Sts
    delegate ApplLinComAb_LIN3.VeLINR_b_HTLBV_StsTO <-> outer port VeLINR_b_HTLBV_StsTO
    delegate ApplLinComAb_LIN3.VeLINR_b_RsErr_HTLBV <-> outer port VeLINR_b_RsErr_HTLBV
    delegate ApplLinComAb_LIN3.VeLINR_b_RsErr_HTLBV_TO <-> outer port VeLINR_b_RsErr_HTLBV_TO
    delegate ApplLinComAb_LIN3.VeLINR_e_HTLBV_CalStat <-> outer port VeLINR_e_HTLBV_CalStat
    delegate ApplLinComAb_LIN3.VeLINR_b_HTLBV_CalStatTO <-> outer port VeLINR_b_HTLBV_CalStatTO
    delegate ApplLinComAb_LIN3.VeLINR_Pct_PECP2_RPM_TGT_PERCT <-> outer port VeLINR_Pct_PECP2_RPM_TGT_PERCT
    delegate ApplLinComAb_LIN3.VeLINR_b_PECP2_RPM_TGT_PERCT_TO <-> outer port VeLINR_b_PECP2_RPM_TGT_PERCT_TO
    delegate ApplLinComAb_LIN3.VeLINR_Pct_PECP2_RPM_ACTL_PERCT <-> outer port VeLINR_Pct_PECP2_RPM_ACTL_PERCT
    delegate ApplLinComAb_LIN3.VeLINR_b_PECP2_RPM_ACTL_PERCT_TO <-> outer port VeLINR_b_PECP2_RPM_ACTL_PERCT_TO
    delegate ApplLinComAb_LIN3.VeLINR_U_PECP2_VLTG <-> outer port VeLINR_U_PECP2_VLTG
    delegate ApplLinComAb_LIN3.VeLINR_b_PECP2_VLTG_TO <-> outer port VeLINR_b_PECP2_VLTG_TO
    delegate ApplLinComAb_LIN3.VeLINR_T_PECP2_TEMP <-> outer port VeLINR_T_PECP2_TEMP
    delegate ApplLinComAb_LIN3.VeLINR_b_PECP2_TEMP_TO <-> outer port VeLINR_b_PECP2_TEMP_TO
    delegate ApplLinComAb_LIN3.VeLINR_I_PECP2_CURR <-> outer port VeLINR_I_PECP2_CURR
    delegate ApplLinComAb_LIN3.VeLINR_b_PECP2_CURR_TO <-> outer port VeLINR_b_PECP2_CURR_TO
    delegate ApplLinComAb_LIN3.VeLINR_e_PECP2_FL_SAFE_ACTVTD <-> outer port VeLINR_e_PECP2_FL_SAFE_ACTVTD
    delegate ApplLinComAb_LIN3.VeLINR_b_PECP2_FL_SAFE_ACTVTD_TO <-> outer port VeLINR_b_PECP2_FL_SAFE_ACTVTD_TO
    delegate ApplLinComAb_LIN3.VeLINR_e_PECP2_LMP_HM_AN_ON <-> outer port VeLINR_e_PECP2_LMP_HM_AN_ON
    delegate ApplLinComAb_LIN3.VeLINR_b_PECP2_LMP_HM_AN_ON_TO <-> outer port VeLINR_b_PECP2_LMP_HM_AN_ON_TO
    delegate ApplLinComAb_LIN3.VeLINR_e_PECP2_AIR_PRE_ERR <-> outer port VeLINR_e_PECP2_AIR_PRE_ERR
    delegate ApplLinComAb_LIN3.VeLINR_b_PECP2_AIR_PRE_ERR_TO <-> outer port VeLINR_b_PECP2_AIR_PRE_ERR_TO
    delegate ApplLinComAb_LIN3.VeLINR_e_PECP2_OVR_TMP_ERR <-> outer port VeLINR_e_PECP2_OVR_TMP_ERR
    delegate ApplLinComAb_LIN3.VeLINR_b_PECP2_OVR_TMP_ERR_TO <-> outer port VeLINR_b_PECP2_OVR_TMP_ERR_TO
    delegate ApplLinComAb_LIN3.VeLINR_e_PECP2_OVR_CUR_ERR <-> outer port VeLINR_e_PECP2_OVR_CUR_ERR
    delegate ApplLinComAb_LIN3.VeLINR_b_PECP2_OVR_CUR_ERR_TO <-> outer port VeLINR_b_PECP2_OVR_CUR_ERR_TO
    delegate ApplLinComAb_LIN3.VeLINR_e_PECP2_DR_RN_ERR <-> outer port VeLINR_e_PECP2_DR_RN_ERR
    delegate ApplLinComAb_LIN3.VeLINR_b_PECP2_DR_RN_ERR_TO <-> outer port VeLINR_b_PECP2_DR_RN_ERR_TO
    delegate ApplLinComAb_LIN3.VeLINR_e_PECP2_VLTG_ERR <-> outer port VeLINR_e_PECP2_VLTG_ERR
    delegate ApplLinComAb_LIN3.VeLINR_b_PECP2_VLTG_ERR_TO <-> outer port VeLINR_b_PECP2_VLTG_ERR_TO
    delegate ApplLinComAb_LIN3.VeLINR_e_PECP2_DBLK_ACTV <-> outer port VeLINR_e_PECP2_DBLK_ACTV
    delegate ApplLinComAb_LIN3.VeLINR_b_PECP2_DBLK_ACTV_TO <-> outer port VeLINR_b_PECP2_DBLK_ACTV_TO
    delegate ApplLinComAb_LIN3.VeLINR_e_PECP2_MONTRNG_RPM <-> outer port VeLINR_e_PECP2_MONTRNG_RPM
    delegate ApplLinComAb_LIN3.VeLINR_b_PECP2_MONTRNG_RPM_TO <-> outer port VeLINR_b_PECP2_MONTRNG_RPM_TO
    delegate ApplLinComAb_LIN3.VeLINR_e_PECP2_NODE_ERR <-> outer port VeLINR_e_PECP2_NODE_ERR
    delegate ApplLinComAb_LIN3.VeLINR_b_PECP2_NODE_ERR_TO <-> outer port VeLINR_b_PECP2_NODE_ERR_TO
    delegate ApplLinComAb_LIN3.VeLINR_e_PECP2_POST_RUN_STAT <-> outer port VeLINR_e_PECP2_POST_RUN_STAT
    delegate ApplLinComAb_LIN3.VeLINR_b_PECP2_POST_RUN_STAT_TO <-> outer port VeLINR_b_PECP2_POST_RUN_STAT_TO
    delegate ApplLinComAb_LIN3.VeLINR_b_RsErr_PECP2_PUMP <-> outer port VeLINR_b_RsErr_PECP2_PUMP
    delegate ApplLinComAb_LIN3.VeLINR_b_RsErr_PECP2_PUMP_TO <-> outer port VeLINR_b_RsErr_PECP2_PUMP_TO
    delegate ApplLinComAb_LIN3.VeLINR_y_PECP2_VERSION <-> outer port VeLINR_y_PECP2_VERSION
    delegate ApplLinComAb_LIN3.VeLINR_b_PECP2_VERSION_TO <-> outer port VeLINR_b_PECP2_VERSION_TO
    delegate ApplLinComAb_LIN3.VeLINR_e_PECP2_SUPPLIER <-> outer port VeLINR_e_PECP2_SUPPLIER
    delegate ApplLinComAb_LIN3.VeLINR_b_PECP2_SUPPLIER_TO <-> outer port VeLINR_b_PECP2_SUPPLIER_TO
    delegate ApplLinComAb_LIN3.VeLINR_b_PowerPanel2ButtonState <-> outer port VeLINR_b_PowerPanel2ButtonState
    delegate ApplLinComAb_LIN3.VeLINR_b_PowerPanel2ButtonStateTO <-> outer port VeLINR_b_PowerPanel2ButtonStateTO
    delegate ApplLinComAb_LIN3.VeLINR_b_PwrPanel2LidSwtSts120A <-> outer port VeLINR_b_PwrPanel2LidSwtSts120A
    delegate ApplLinComAb_LIN3.VeLINR_b_PwrPanel2LidSwtSts120A_TO <-> outer port VeLINR_b_PwrPanel2LidSwtSts120A_TO
    delegate ApplLinComAb_LIN3.VeLINR_b_PwrPanel2LidSwtSts120B <-> outer port VeLINR_b_PwrPanel2LidSwtSts120B
    delegate ApplLinComAb_LIN3.VeLINR_b_PwrPanel2LidSwtSts120B_TO <-> outer port VeLINR_b_PwrPanel2LidSwtSts120B_TO
    delegate ApplLinComAb_LIN3.VeLINR_b_PwrPanel2LidSwtSts240 <-> outer port VeLINR_b_PwrPanel2LidSwtSts240
    delegate ApplLinComAb_LIN3.VeLINR_b_PwrPanel2LidSwtSts240TO <-> outer port VeLINR_b_PwrPanel2LidSwtSts240TO
    delegate ApplLinComAb_LIN3.VeLINR_b_PwrPanel2AC_PrsntSens1 <-> outer port VeLINR_b_PwrPanel2AC_PrsntSens1
    delegate ApplLinComAb_LIN3.VeLINR_b_PwrPanel2AC_PrsntSens1TO <-> outer port VeLINR_b_PwrPanel2AC_PrsntSens1TO
    delegate ApplLinComAb_LIN3.VeLINR_b_PwrPanel2AC_PrsntSens2 <-> outer port VeLINR_b_PwrPanel2AC_PrsntSens2
    delegate ApplLinComAb_LIN3.VeLINR_b_PwrPanel2AC_PrsntSens2TO <-> outer port VeLINR_b_PwrPanel2AC_PrsntSens2TO
    delegate ApplLinComAb_LIN3.VeLINR_e_PwrPanel2_Fault_Reason <-> outer port VeLINR_e_PwrPanel2_Fault_Reason
    delegate ApplLinComAb_LIN3.VeLINR_b_PwrPanel2_Fault_ReasonTO <-> outer port VeLINR_b_PwrPanel2_Fault_ReasonTO
    delegate ApplLinComAb_LIN3.VeLINR_b_RsErr_SPP2 <-> outer port VeLINR_b_RsErr_SPP2
    delegate ApplLinComAb_LIN3.VeLINR_b_RsErr_SPP2TO <-> outer port VeLINR_b_RsErr_SPP2TO
    delegate ApplLinComAb_LIN3.SendLINR_AGS_PosRq <-> outer port SendLINR_AGS_PosRq
    delegate ApplLinComAb_LIN3.SendLINR_AGS_PosRqVld <-> outer port SendLINR_AGS_PosRqVld
    delegate ApplLinComAb_LIN3.SendLINR_AGS_CalRq <-> outer port SendLINR_AGS_CalRq
    delegate ApplLinComAb_LIN3.SendLINR_AGS_CalRqVld <-> outer port SendLINR_AGS_CalRqVld
    delegate ApplLinComAb_LIN3.SendLINR_AGS_BoostRq <-> outer port SendLINR_AGS_BoostRq
    delegate ApplLinComAb_LIN3.SendLINR_AGS_BoostRqVld <-> outer port SendLINR_AGS_BoostRqVld
    delegate ApplLinComAb_LIN3.SendLINR_M2SRes2Bit <-> outer port SendLINR_M2SRes2Bit
    delegate ApplLinComAb_LIN3.SendLINR_M2SRes2BitVld <-> outer port SendLINR_M2SRes2BitVld
    delegate ApplLinComAb_LIN3.SendLINR_M2SResByte1 <-> outer port SendLINR_M2SResByte1
    delegate ApplLinComAb_LIN3.SendLINR_M2SResByte1Vld <-> outer port SendLINR_M2SResByte1Vld
    delegate ApplLinComAb_LIN3.SendLINR_M2SResByte2 <-> outer port SendLINR_M2SResByte2
    delegate ApplLinComAb_LIN3.SendLINR_M2SResByte2Vld <-> outer port SendLINR_M2SResByte2Vld
    delegate ApplLinComAb_LIN3.SendLINR_M2SResByte3 <-> outer port SendLINR_M2SResByte3
    delegate ApplLinComAb_LIN3.SendLINR_M2SResByte3Vld <-> outer port SendLINR_M2SResByte3Vld
    delegate ApplLinComAb_LIN3.SendLINR_CEXV_PosRq <-> outer port SendLINR_CEXV_PosRq
    delegate ApplLinComAb_LIN3.SendLINR_CEXV_PosRqVld <-> outer port SendLINR_CEXV_PosRqVld
    delegate ApplLinComAb_LIN3.SendLINR_CEXV_CalCmd <-> outer port SendLINR_CEXV_CalCmd
    delegate ApplLinComAb_LIN3.SendLINR_CEXV_CalCmdVld <-> outer port SendLINR_CEXV_CalCmdVld
    delegate ApplLinComAb_LIN3.SendLINR_CPIM_SET_IND1 <-> outer port SendLINR_CPIM_SET_IND1
    delegate ApplLinComAb_LIN3.SendLINR_CPIM_SET_IND1Vld <-> outer port SendLINR_CPIM_SET_IND1Vld
    delegate ApplLinComAb_LIN3.SendLINR_CPIM_SET_IND2 <-> outer port SendLINR_CPIM_SET_IND2
    delegate ApplLinComAb_LIN3.SendLINR_CPIM_SET_IND2Vld <-> outer port SendLINR_CPIM_SET_IND2Vld
    delegate ApplLinComAb_LIN3.SendLINR_CPIM_SET_IND3 <-> outer port SendLINR_CPIM_SET_IND3
    delegate ApplLinComAb_LIN3.SendLINR_CPIM_SET_IND3Vld <-> outer port SendLINR_CPIM_SET_IND3Vld
    delegate ApplLinComAb_LIN3.SendLINR_CPIM_SET_IND4 <-> outer port SendLINR_CPIM_SET_IND4
    delegate ApplLinComAb_LIN3.SendLINR_CPIM_SET_IND4Vld <-> outer port SendLINR_CPIM_SET_IND4Vld
    delegate ApplLinComAb_LIN3.SendLINR_CPIM_SET_IND5 <-> outer port SendLINR_CPIM_SET_IND5
    delegate ApplLinComAb_LIN3.SendLINR_CPIM_SET_IND5Vld <-> outer port SendLINR_CPIM_SET_IND5Vld
    delegate ApplLinComAb_LIN3.SendLINR_CPIM_Blink_Rate <-> outer port SendLINR_CPIM_Blink_Rate
    delegate ApplLinComAb_LIN3.SendLINR_CPIM_Blink_RateVld <-> outer port SendLINR_CPIM_Blink_RateVld
    delegate ApplLinComAb_LIN3.SendLINR_CPIM_IND_Color <-> outer port SendLINR_CPIM_IND_Color
    delegate ApplLinComAb_LIN3.SendLINR_CPIM_IND_ColorVld <-> outer port SendLINR_CPIM_IND_ColorVld
    delegate ApplLinComAb_LIN3.SendLINR_ChrgPortLock_Cmd <-> outer port SendLINR_ChrgPortLock_Cmd
    delegate ApplLinComAb_LIN3.SendLINR_ChrgPortLock_CmdVld <-> outer port SendLINR_ChrgPortLock_CmdVld
    delegate ApplLinComAb_LIN3.SendLINR_Set_Icon1_cmd <-> outer port SendLINR_Set_Icon1_cmd
    delegate ApplLinComAb_LIN3.SendLINR_Set_Icon1_cmdVld <-> outer port SendLINR_Set_Icon1_cmdVld
    delegate ApplLinComAb_LIN3.SendLINR_Set_Icon2_cmd <-> outer port SendLINR_Set_Icon2_cmd
    delegate ApplLinComAb_LIN3.SendLINR_Set_Icon2_cmdVld <-> outer port SendLINR_Set_Icon2_cmdVld
    delegate ApplLinComAb_LIN3.SendLINR_DAY_LGT_MD_CPIM <-> outer port SendLINR_DAY_LGT_MD_CPIM
    delegate ApplLinComAb_LIN3.SendLINR_DAY_LGT_MD_CPIM_Vld <-> outer port SendLINR_DAY_LGT_MD_CPIM_Vld
    delegate ApplLinComAb_LIN3.SendLINR_Backlight_Cmd <-> outer port SendLINR_Backlight_Cmd
    delegate ApplLinComAb_LIN3.SendLINR_Backlight_CmdVld <-> outer port SendLINR_Backlight_CmdVld
    delegate ApplLinComAb_LIN3.SendLINR_HvWtrHeatrPwrCnsAllwd <-> outer port SendLINR_HvWtrHeatrPwrCnsAllwd
    delegate ApplLinComAb_LIN3.SendLINR_HvWtrHeatrPwrCnsAllwdVld <-> outer port SendLINR_HvWtrHeatrPwrCnsAllwdVld
    delegate ApplLinComAb_LIN3.SendLINR_HvWtrHeatrWtrTDes <-> outer port SendLINR_HvWtrHeatrWtrTDes
    delegate ApplLinComAb_LIN3.SendLINR_HvWtrHeatrWtrTDesVld <-> outer port SendLINR_HvWtrHeatrWtrTDesVld
    delegate ApplLinComAb_LIN3.SendLINR_HvCooltHeatrEnad <-> outer port SendLINR_HvCooltHeatrEnad
    delegate ApplLinComAb_LIN3.SendLINR_HvCooltHeatrEnadVld <-> outer port SendLINR_HvCooltHeatrEnadVld
    delegate ApplLinComAb_LIN3.SendLINR_HVH_OverheatUnlock <-> outer port SendLINR_HVH_OverheatUnlock
    delegate ApplLinComAb_LIN3.SendLINR_HVH_OverheatUnlockVld <-> outer port SendLINR_HVH_OverheatUnlockVld
    delegate ApplLinComAb_LIN3.SendLINR_EOPB_RPM_COM <-> outer port SendLINR_EOPB_RPM_COM
    delegate ApplLinComAb_LIN3.SendLINR_EOPB_RPM_COM_Vld <-> outer port SendLINR_EOPB_RPM_COM_Vld
    delegate ApplLinComAb_LIN3.SendLINR_EOPB_POST_RUN_COM <-> outer port SendLINR_EOPB_POST_RUN_COM
    delegate ApplLinComAb_LIN3.SendLINR_EOPB_POST_RUN_COM_Vld <-> outer port SendLINR_EOPB_POST_RUN_COM_Vld
    delegate ApplLinComAb_LIN3.SendLINR_HTLBV_PosRq <-> outer port SendLINR_HTLBV_PosRq
    delegate ApplLinComAb_LIN3.SendLINR_HTLBV_PosRqVld <-> outer port SendLINR_HTLBV_PosRqVld
    delegate ApplLinComAb_LIN3.SendLINR_HTLBV_PosSv <-> outer port SendLINR_HTLBV_PosSv
    delegate ApplLinComAb_LIN3.SendLINR_HTLBV_PosSvVld <-> outer port SendLINR_HTLBV_PosSvVld
    delegate ApplLinComAb_LIN3.SendLINR_HTLBV_CalRq <-> outer port SendLINR_HTLBV_CalRq
    delegate ApplLinComAb_LIN3.SendLINR_HTLBV_CalRqVld <-> outer port SendLINR_HTLBV_CalRqVld
    delegate ApplLinComAb_LIN3.SendLINR_PECP2_RPM_REQ_PERCT <-> outer port SendLINR_PECP2_RPM_REQ_PERCT
    delegate ApplLinComAb_LIN3.SendLINR_PECP2_RPM_REQ_PERCT_Vld <-> outer port SendLINR_PECP2_RPM_REQ_PERCT_Vld
    delegate ApplLinComAb_LIN3.SendLINR_PECP2_POST_RUN_REQ <-> outer port SendLINR_PECP2_POST_RUN_REQ
    delegate ApplLinComAb_LIN3.SendLINR_PECP2_POST_RUN_REQ_Vld <-> outer port SendLINR_PECP2_POST_RUN_REQ_Vld
    delegate ApplLinComAb_LIN3.SendLINR_PECP2_FL_SAFE_ACTVT <-> outer port SendLINR_PECP2_FL_SAFE_ACTVT
    delegate ApplLinComAb_LIN3.SendLINR_PECP2_FL_SAFE_ACTVT_Vld <-> outer port SendLINR_PECP2_FL_SAFE_ACTVT_Vld
    delegate ApplLinComAb_LIN3.SendLINR_PowerPanel2_LED_A_Cmnd <-> outer port SendLINR_PowerPanel2_LED_A_Cmnd
    delegate ApplLinComAb_LIN3.SendLINR_PowerPanel2_LED_A_CmndVld <-> outer port SendLINR_PowerPanel2_LED_A_CmndVld
    delegate ApplLinComAb_LIN3.SendLINR_PowerPanel2_LED_B_Cmnd <-> outer port SendLINR_PowerPanel2_LED_B_Cmnd
    delegate ApplLinComAb_LIN3.SendLINR_PowerPanel2_LED_B_CmndVld <-> outer port SendLINR_PowerPanel2_LED_B_CmndVld
    delegate ApplLinComAb_LIN3.SendLINR_DAY_LGT_MD_PowerPanel2 <-> outer port SendLINR_DAY_LGT_MD_PowerPanel2
    delegate ApplLinComAb_LIN3.SendLINR_DAY_LGT_MD_PowerPanel2Vld <-> outer port SendLINR_DAY_LGT_MD_PowerPanel2Vld
    delegate ApplLinComAb_LIN3.SignalLINR_AGS_RdyForSleep <-> outer port SignalLINR_AGS_RdyForSleep
    delegate ApplLinComAb_LIN3.SignalLINR_CEXV_RdyForSleep <-> outer port SignalLINR_CEXV_RdyForSleep
    delegate ApplLinComAb_LIN3.SignalLINR_CPIM_RdyForSleep <-> outer port SignalLINR_CPIM_RdyForSleep
    delegate ApplLinComAb_LIN3.SignalLINR_ECH_RdyForSleep <-> outer port SignalLINR_ECH_RdyForSleep
    delegate ApplLinComAb_LIN3.SignalLINR_EOPB_RdyForSleep <-> outer port SignalLINR_EOPB_RdyForSleep
    delegate ApplLinComAb_LIN3.SignalLINR_HTLBV_RdyForSleep <-> outer port SignalLINR_HTLBV_RdyForSleep
    delegate ApplLinComAb_LIN3.SignalLINR_PECP2_RdyForSleep <-> outer port SignalLINR_PECP2_RdyForSleep
    delegate ApplLinComAb_LIN3.SignalLINR_SPP2_RdyForSleep <-> outer port SignalLINR_SPP2_RdyForSleep
    delegate ApplLinComAb_LIN1.VeLINR_e_CoolantValve_ErrLinCom <-> outer port VeLINR_e_CoolantValve_ErrLinCom
    delegate ApplLinComAb_LIN1.VeLINR_b_CoolantValve_ErrLinComTO <-> outer port VeLINR_b_CoolantValve_ErrLinComTO
    delegate ApplLinComAb_LIN1.VeLINR_e_CoolantValve_ErrPos <-> outer port VeLINR_e_CoolantValve_ErrPos
    delegate ApplLinComAb_LIN1.VeLINR_b_CoolantValve_ErrPosTO <-> outer port VeLINR_b_CoolantValve_ErrPosTO
    delegate ApplLinComAb_LIN1.VeLINR_b_CoolantVal_SelfCalReq <-> outer port VeLINR_b_CoolantVal_SelfCalReq
    delegate ApplLinComAb_LIN1.VeLINR_b_CoolantVal_SelfCalReqTO <-> outer port VeLINR_b_CoolantVal_SelfCalReqTO
    delegate ApplLinComAb_LIN1.VeLINR_e_CoolantVal_SystemState <-> outer port VeLINR_e_CoolantVal_SystemState
    delegate ApplLinComAb_LIN1.VeLINR_b_CoolantVal_SystemStateTO <-> outer port VeLINR_b_CoolantVal_SystemStateTO
    delegate ApplLinComAb_LIN1.VeLINR_y_CoolantVal_EcuVoltage <-> outer port VeLINR_y_CoolantVal_EcuVoltage
    delegate ApplLinComAb_LIN1.VeLINR_b_CoolantVal_EcuVoltageTO <-> outer port VeLINR_b_CoolantVal_EcuVoltageTO
    delegate ApplLinComAb_LIN1.VeLINR_d_CoolVal_ActuatPosTrgt <-> outer port VeLINR_d_CoolVal_ActuatPosTrgt
    delegate ApplLinComAb_LIN1.VeLINR_b_CoolVal_ActuatPosTrgtTO <-> outer port VeLINR_b_CoolVal_ActuatPosTrgtTO
    delegate ApplLinComAb_LIN1.VeLINR_d_CoolantVal_ActuPosAct <-> outer port VeLINR_d_CoolantVal_ActuPosAct
    delegate ApplLinComAb_LIN1.VeLINR_b_CoolantVal_ActuPosActTO <-> outer port VeLINR_b_CoolantVal_ActuPosActTO
    delegate ApplLinComAb_LIN1.VeLINR_y_CoolantValve_EcuTemp <-> outer port VeLINR_y_CoolantValve_EcuTemp
    delegate ApplLinComAb_LIN1.VeLINR_b_CoolantValve_EcuTempTO <-> outer port VeLINR_b_CoolantValve_EcuTempTO
    delegate ApplLinComAb_LIN1.VeLINR_e_CoolantValve_Err_Motor <-> outer port VeLINR_e_CoolantValve_Err_Motor
    delegate ApplLinComAb_LIN1.VeLINR_b_CoolantValve_Err_MotorTO <-> outer port VeLINR_b_CoolantValve_Err_MotorTO
    delegate ApplLinComAb_LIN1.VeLINR_e_CoolantValve_Err_Volt <-> outer port VeLINR_e_CoolantValve_Err_Volt
    delegate ApplLinComAb_LIN1.VeLINR_b_CoolantValve_Err_VoltTO <-> outer port VeLINR_b_CoolantValve_Err_VoltTO
    delegate ApplLinComAb_LIN1.VeLINR_e_CoolantValve_Err_Ecu <-> outer port VeLINR_e_CoolantValve_Err_Ecu
    delegate ApplLinComAb_LIN1.VeLINR_b_CoolantValve_Err_EcuTO <-> outer port VeLINR_b_CoolantValve_Err_EcuTO
    delegate ApplLinComAb_LIN1.VeLINR_b_CoolantVal_ResponseErr <-> outer port VeLINR_b_CoolantVal_ResponseErr
    delegate ApplLinComAb_LIN1.VeLINR_b_CoolantVal_ResponseErrTO <-> outer port VeLINR_b_CoolantVal_ResponseErrTO
    delegate ApplLinComAb_LIN1.SendLINR_Control_TargetPos <-> outer port SendLINR_Control_TargetPos
    delegate ApplLinComAb_LIN1.SendLINR_Control_TargetPosVld <-> outer port SendLINR_Control_TargetPosVld
    delegate ApplLinComAb_LIN1.SendLINR_Control_Reserved1 <-> outer port SendLINR_Control_Reserved1
    delegate ApplLinComAb_LIN1.SendLINR_Control_Reserved1Vld <-> outer port SendLINR_Control_Reserved1Vld
    delegate ApplLinComAb_LIN1.SendLINR_Control_BlockDetEnbl <-> outer port SendLINR_Control_BlockDetEnbl
    delegate ApplLinComAb_LIN1.SendLINR_Control_BlockDetEnblVld <-> outer port SendLINR_Control_BlockDetEnblVld
    delegate ApplLinComAb_LIN1.SendLINR_Control_DiagFunctnVal <-> outer port SendLINR_Control_DiagFunctnVal
    delegate ApplLinComAb_LIN1.SendLINR_Control_DiagFunctnValVld <-> outer port SendLINR_Control_DiagFunctnValVld
    delegate ApplLinComAb_LIN1.SendLINR_Control_Reserved2 <-> outer port SendLINR_Control_Reserved2
    delegate ApplLinComAb_LIN1.SendLINR_Control_Reserved2Vld <-> outer port SendLINR_Control_Reserved2Vld
    delegate ApplLinComAb_LIN1.SendLINR_Control_Reserved3 <-> outer port SendLINR_Control_Reserved3
    delegate ApplLinComAb_LIN1.SendLINR_Control_Reserved3Vld <-> outer port SendLINR_Control_Reserved3Vld
    delegate ApplLinComAb_LIN1.SendLINR_Control_Reserved4 <-> outer port SendLINR_Control_Reserved4
    delegate ApplLinComAb_LIN1.SendLINR_Control_Reserved4Vld <-> outer port SendLINR_Control_Reserved4Vld
    delegate ApplLinComAb_LIN1.SendLINR_Control_Reserved5 <-> outer port SendLINR_Control_Reserved5
    delegate ApplLinComAb_LIN1.SendLINR_Control_Reserved5Vld <-> outer port SendLINR_Control_Reserved5Vld
    delegate ApplLinComAb_LIN1.SendLINR_Control_Reserved6 <-> outer port SendLINR_Control_Reserved6
    delegate ApplLinComAb_LIN1.SendLINR_Control_Reserved6Vld <-> outer port SendLINR_Control_Reserved6Vld
    delegate ApplLinComAb_LIN1.SignalLINR_HTRBV_RdyForSleep <-> outer port SignalLINR_HTRBV_RdyForSleep
    delegate ApplLinComAb_LIN2.VeLINR_e_CompFaultStat_800 <-> outer port VeLINR_e_CompFaultStat_800
    delegate ApplLinComAb_LIN2.VeLINR_b_CompFaultStat_800TO <-> outer port VeLINR_b_CompFaultStat_800TO
    delegate ApplLinComAb_LIN2.VeLINR_e_CompStat_800 <-> outer port VeLINR_e_CompStat_800
    delegate ApplLinComAb_LIN2.VeLINR_b_CompStat_800TO <-> outer port VeLINR_b_CompStat_800TO
    delegate ApplLinComAb_LIN2.VeLINR_n_CompressorSpd_800 <-> outer port VeLINR_n_CompressorSpd_800
    delegate ApplLinComAb_LIN2.VeLINR_b_CompressorSpd_800TO <-> outer port VeLINR_b_CompressorSpd_800TO
    delegate ApplLinComAb_LIN2.VeLINR_b_CompSpdIncrReq_800 <-> outer port VeLINR_b_CompSpdIncrReq_800
    delegate ApplLinComAb_LIN2.VeLINR_b_CompSpdIncrReq_800TO <-> outer port VeLINR_b_CompSpdIncrReq_800TO
    delegate ApplLinComAb_LIN2.VeLINR_b_RsErr_EAC2_800 <-> outer port VeLINR_b_RsErr_EAC2_800
    delegate ApplLinComAb_LIN2.VeLINR_b_RsErr_EAC2_800TO <-> outer port VeLINR_b_RsErr_EAC2_800TO
    delegate ApplLinComAb_LIN2.VeLINR_P_CompElecPwr_800 <-> outer port VeLINR_P_CompElecPwr_800
    delegate ApplLinComAb_LIN2.VeLINR_b_CompElecPwr_800TO <-> outer port VeLINR_b_CompElecPwr_800TO
    delegate ApplLinComAb_LIN2.VeLINR_T_CompBoardTemp_800 <-> outer port VeLINR_T_CompBoardTemp_800
    delegate ApplLinComAb_LIN2.VeLINR_b_CompBoardTemp_800TO <-> outer port VeLINR_b_CompBoardTemp_800TO
    delegate ApplLinComAb_LIN2.VeLINR_T_CompIGBTTemp_800 <-> outer port VeLINR_T_CompIGBTTemp_800
    delegate ApplLinComAb_LIN2.VeLINR_b_CompIGBTTemp_800TO <-> outer port VeLINR_b_CompIGBTTemp_800TO
    delegate ApplLinComAb_LIN2.VeLINR_I_CompElecCurr_800 <-> outer port VeLINR_I_CompElecCurr_800
    delegate ApplLinComAb_LIN2.VeLINR_b_CompElecCurr_800TO <-> outer port VeLINR_b_CompElecCurr_800TO
    delegate ApplLinComAb_LIN2.VeLINR_U_CompHVInput_800 <-> outer port VeLINR_U_CompHVInput_800
    delegate ApplLinComAb_LIN2.VeLINR_b_CompHVInput_800TO <-> outer port VeLINR_b_CompHVInput_800TO
    delegate ApplLinComAb_LIN2.SendLINR_PwrPanel_LED_C_Command <-> outer port SendLINR_PwrPanel_LED_C_Command
    delegate ApplLinComAb_LIN2.SendLINR_PwrPanel_LED_C_CommandVld <-> outer port SendLINR_PwrPanel_LED_C_CommandVld
    delegate ApplLinComAb_LIN2.SendLINR_PwrPanel_LEDA_ColorCmd <-> outer port SendLINR_PwrPanel_LEDA_ColorCmd
    delegate ApplLinComAb_LIN2.SendLINR_PwrPanel_LEDA_ColorCmdVld <-> outer port SendLINR_PwrPanel_LEDA_ColorCmdVld
    delegate ApplLinComAb_LIN2.SendLINR_PwrPanel_LEDB_ColorCmd <-> outer port SendLINR_PwrPanel_LEDB_ColorCmd
    delegate ApplLinComAb_LIN2.SendLINR_PwrPanel_LEDB_ColorCmdVld <-> outer port SendLINR_PwrPanel_LEDB_ColorCmdVld
    delegate ApplLinComAb_LIN2.SendLINR_PwrPanel_LEDC_ColorCmd <-> outer port SendLINR_PwrPanel_LEDC_ColorCmd
    delegate ApplLinComAb_LIN2.SendLINR_PwrPanel_LEDC_ColorCmdVld <-> outer port SendLINR_PwrPanel_LEDC_ColorCmdVld
    delegate ApplLinComAb_LIN2.SignalLINR_CACV_RdyForSleep <-> outer port SignalLINR_CACV_RdyForSleep
    delegate ApplLinComAb_LIN2.VeLINR_e_PwrPanel_LEDA_Feedback <-> outer port VeLINR_e_PwrPanel_LEDA_Feedback
    delegate ApplLinComAb_LIN2.VeLINR_b_PwrPanel_LEDA_FeedbackTO <-> outer port VeLINR_b_PwrPanel_LEDA_FeedbackTO
    delegate ApplLinComAb_LIN2.VeLINR_e_PwrPanel_LEDB_Feedback <-> outer port VeLINR_e_PwrPanel_LEDB_Feedback
    delegate ApplLinComAb_LIN2.VeLINR_b_PwrPanel_LEDB_FeedbackTO <-> outer port VeLINR_b_PwrPanel_LEDB_FeedbackTO
    delegate ApplLinComAb_LIN2.VeLINR_e_PwrPanel_LEDC_Feedback <-> outer port VeLINR_e_PwrPanel_LEDC_Feedback
    delegate ApplLinComAb_LIN2.VeLINR_b_PwrPanel_LEDC_FeedbackTO <-> outer port VeLINR_b_PwrPanel_LEDC_FeedbackTO
    delegate ApplLinComAb_LIN2.VeLINR_e_PwrPanel_LEDA_FailSts <-> outer port VeLINR_e_PwrPanel_LEDA_FailSts
    delegate ApplLinComAb_LIN2.VeLINR_b_PwrPanel_LEDA_FailStsTO <-> outer port VeLINR_b_PwrPanel_LEDA_FailStsTO
    delegate ApplLinComAb_LIN2.VeLINR_e_PwrPanel_LEDB_FailSts <-> outer port VeLINR_e_PwrPanel_LEDB_FailSts
    delegate ApplLinComAb_LIN2.VeLINR_b_PwrPanel_LEDB_FailStsTO <-> outer port VeLINR_b_PwrPanel_LEDB_FailStsTO
    delegate ApplLinComAb_LIN2.VeLINR_e_PwrPanel_LEDC_FailSts <-> outer port VeLINR_e_PwrPanel_LEDC_FailSts
    delegate ApplLinComAb_LIN2.VeLINR_b_PwrPanel_LEDC_FailStsTO <-> outer port VeLINR_b_PwrPanel_LEDC_FailStsTO
    delegate ApplLinComAb_LIN2.VeLINR_e_PwrPanelLEDAColorFdbck <-> outer port VeLINR_e_PwrPanelLEDAColorFdbck
    delegate ApplLinComAb_LIN2.VeLINR_b_PwrPanelLEDAColorFdbckTO <-> outer port VeLINR_b_PwrPanelLEDAColorFdbckTO
    delegate ApplLinComAb_LIN2.VeLINR_e_PwrPanelLEDBColorFdbck <-> outer port VeLINR_e_PwrPanelLEDBColorFdbck
    delegate ApplLinComAb_LIN2.VeLINR_b_PwrPanelLEDBColorFdbckTO <-> outer port VeLINR_b_PwrPanelLEDBColorFdbckTO
    delegate ApplLinComAb_LIN2.VeLINR_e_PwrPanelLEDCColorFdbck <-> outer port VeLINR_e_PwrPanelLEDCColorFdbck
    delegate ApplLinComAb_LIN2.VeLINR_b_PwrPanelLEDCColorFdbckTO <-> outer port VeLINR_b_PwrPanelLEDCColorFdbckTO
    delegate ApplLinComAb_LIN2.VeLINR_b_PwrPanel_LIN_ChksumErr <-> outer port VeLINR_b_PwrPanel_LIN_ChksumErr
    delegate ApplLinComAb_LIN2.VeLINR_b_PwrPanel_LIN_ChksumErrTO <-> outer port VeLINR_b_PwrPanel_LIN_ChksumErrTO
    delegate ApplLinComAb_LIN2.VeLINR_b_PwrPanel_LIN_DataError <-> outer port VeLINR_b_PwrPanel_LIN_DataError
    delegate ApplLinComAb_LIN2.VeLINR_b_PwrPanel_LIN_DataErrorTO <-> outer port VeLINR_b_PwrPanel_LIN_DataErrorTO
    delegate ApplLinComAb_LIN2.VeLINR_b_PwrPanel_LIN_ParityErr <-> outer port VeLINR_b_PwrPanel_LIN_ParityErr
    delegate ApplLinComAb_LIN2.VeLINR_b_PwrPanel_LIN_ParityErrTO <-> outer port VeLINR_b_PwrPanel_LIN_ParityErrTO
    delegate ApplLinComAb_LIN2.VeLINR_b_PwrPanelGndFltDetected <-> outer port VeLINR_b_PwrPanelGndFltDetected
    delegate ApplLinComAb_LIN2.VeLINR_b_PwrPanelGndFltDetectedTO <-> outer port VeLINR_b_PwrPanelGndFltDetectedTO
    delegate ApplLinComAb_LIN2.VeLINR_b_RsErr_EAC2 <-> outer port VeLINR_b_RsErr_EAC2
    delegate ApplLinComAb_LIN2.VeLINR_b_RsErr_EAC2TO <-> outer port VeLINR_b_RsErr_EAC2TO
    delegate ApplLinComAb_LIN2.VeLINR_e_PowerPanel_Fault <-> outer port VeLINR_e_PowerPanel_Fault
    delegate ApplLinComAb_LIN2.VeLINR_b_PowerPanel_FaultTO <-> outer port VeLINR_b_PowerPanel_FaultTO
    delegate ApplLinComAb_LIN2.VeLINR_y_PowerPanel_RatedPower <-> outer port VeLINR_y_PowerPanel_RatedPower
    delegate ApplLinComAb_LIN2.VeLINR_b_PowerPanel_RatedPowerTO <-> outer port VeLINR_b_PowerPanel_RatedPowerTO
    delegate ApplLinComAb_LIN3.VeLINR_e_PowerPanel2_LED_A_Fdbk <-> outer port VeLINR_e_PowerPanel2_LED_A_Fdbk
    delegate ApplLinComAb_LIN3.VeLINR_b_PowerPanel2_LED_A_FdbkTO <-> outer port VeLINR_b_PowerPanel2_LED_A_FdbkTO
    delegate ApplLinComAb_LIN3.VeLINR_e_PowerPanel2_LED_B_Fdbk <-> outer port VeLINR_e_PowerPanel2_LED_B_Fdbk
    delegate ApplLinComAb_LIN3.VeLINR_b_PowerPanel2_LED_B_FdbkTO <-> outer port VeLINR_b_PowerPanel2_LED_B_FdbkTO
    delegate ApplLinComAb_LIN3.VeLINR_e_PowPan2_LED_A_FailStat <-> outer port VeLINR_e_PowPan2_LED_A_FailStat
    delegate ApplLinComAb_LIN3.VeLINR_b_PowPan2_LED_A_FailStatTO <-> outer port VeLINR_b_PowPan2_LED_A_FailStatTO
    delegate ApplLinComAb_LIN3.VeLINR_e_PowPan2_LED_B_FailStat <-> outer port VeLINR_e_PowPan2_LED_B_FailStat
    delegate ApplLinComAb_LIN3.VeLINR_b_PowPan2_LED_B_FailStatTO <-> outer port VeLINR_b_PowPan2_LED_B_FailStatTO
    delegate ApplLinComAb_LIN3.VeLINR_e_PowPan2_LED_A_Col_Fdbk <-> outer port VeLINR_e_PowPan2_LED_A_Col_Fdbk
    delegate ApplLinComAb_LIN3.VeLINR_b_PowPan2_LED_A_Col_FdbkTO <-> outer port VeLINR_b_PowPan2_LED_A_Col_FdbkTO
    delegate ApplLinComAb_LIN3.VeLINR_e_PowPan2_LED_B_Col_Fdbk <-> outer port VeLINR_e_PowPan2_LED_B_Col_Fdbk
    delegate ApplLinComAb_LIN3.VeLINR_b_PowPan2_LED_B_Col_FdbkTO <-> outer port VeLINR_b_PowPan2_LED_B_Col_FdbkTO
    delegate ApplLinComAb_LIN3.VeLINR_b_PowPan2_LIN_Cksm_Err <-> outer port VeLINR_b_PowPan2_LIN_Cksm_Err
    delegate ApplLinComAb_LIN3.VeLINR_b_PowPan2_LIN_Cksm_ErrTO <-> outer port VeLINR_b_PowPan2_LIN_Cksm_ErrTO
    delegate ApplLinComAb_LIN3.VeLINR_b_PowPan2_LIN_Data_Err <-> outer port VeLINR_b_PowPan2_LIN_Data_Err
    delegate ApplLinComAb_LIN3.VeLINR_b_PowPan2_LIN_Data_ErrTO <-> outer port VeLINR_b_PowPan2_LIN_Data_ErrTO
    delegate ApplLinComAb_LIN3.VeLINR_b_PowPan2_LIN_Parity_Err <-> outer port VeLINR_b_PowPan2_LIN_Parity_Err
    delegate ApplLinComAb_LIN3.VeLINR_b_PowPan2_LIN_Parity_ErrTO <-> outer port VeLINR_b_PowPan2_LIN_Parity_ErrTO
    delegate ApplLinComAb_LIN3.VeLINR_b_PowPan2_Gnd_Fault_Det <-> outer port VeLINR_b_PowPan2_Gnd_Fault_Det
    delegate ApplLinComAb_LIN3.VeLINR_b_PowPan2_Gnd_Fault_DetTO <-> outer port VeLINR_b_PowPan2_Gnd_Fault_DetTO
    delegate ApplLinComAb_LIN3.SendLINR_PowPan2_LED_A_Col_Comm <-> outer port SendLINR_PowPan2_LED_A_Col_Comm
    delegate ApplLinComAb_LIN3.SendLINR_PowPan2_LED_A_Col_CommVld <-> outer port SendLINR_PowPan2_LED_A_Col_CommVld
    delegate ApplLinComAb_LIN3.SendLINR_PowPan2_LED_B_Col_Comm <-> outer port SendLINR_PowPan2_LED_B_Col_Comm
    delegate ApplLinComAb_LIN3.SendLINR_PowPan2_LED_B_Col_CommVld <-> outer port SendLINR_PowPan2_LED_B_Col_CommVld
    delegate ApplLinComAb_LIN3.VeLINR_d_PwrPanel2CurrDrawSens1 <-> outer port VeLINR_d_PwrPanel2CurrDrawSens1
    delegate ApplLinComAb_LIN3.VeLINR_b_PwrPanel2CurrDrawSens1TO <-> outer port VeLINR_b_PwrPanel2CurrDrawSens1TO
    delegate ApplLinComAb_LIN3.VeLINR_d_PwrPanel2CurrDrawSens2 <-> outer port VeLINR_d_PwrPanel2CurrDrawSens2
    delegate ApplLinComAb_LIN3.VeLINR_b_PwrPanel2CurrDrawSens2TO <-> outer port VeLINR_b_PwrPanel2CurrDrawSens2TO
    delegate ApplLinComAb_LIN3.VeLINR_e_PowerPanel2_Fault <-> outer port VeLINR_e_PowerPanel2_Fault
    delegate ApplLinComAb_LIN3.VeLINR_b_PowerPanel2_FaultTO <-> outer port VeLINR_b_PowerPanel2_FaultTO
    delegate ApplLinComAb_LIN3.VeLINR_y_PowerPanel2_RatedPower <-> outer port VeLINR_y_PowerPanel2_RatedPower
    delegate ApplLinComAb_LIN3.VeLINR_b_PowerPanel2_RatedPowerTO <-> outer port VeLINR_b_PowerPanel2_RatedPowerTO
    delegate ApplLinComAb_LIN2.VeLINR_d_PwrPanelCurrDrawSens2 <-> outer port VeLINR_d_PwrPanelCurrDrawSens2
    delegate ApplLinComAb_LIN2.VeLINR_b_PwrPanelCurrDrawSens2TO <-> outer port VeLINR_b_PwrPanelCurrDrawSens2TO
    delegate ApplLinComAb_LIN2.VeLINR_b_PwrPanelAC_PresntSens1 <-> outer port VeLINR_b_PwrPanelAC_PresntSens1
    delegate ApplLinComAb_LIN2.VeLINR_b_PwrPanelAC_PresntSens1TO <-> outer port VeLINR_b_PwrPanelAC_PresntSens1TO
    delegate ApplLinComAb_LIN2.VeLINR_b_PwrPanelAC_PresntSens2 <-> outer port VeLINR_b_PwrPanelAC_PresntSens2
    delegate ApplLinComAb_LIN2.VeLINR_b_PwrPanelAC_PresntSens2TO <-> outer port VeLINR_b_PwrPanelAC_PresntSens2TO
    delegate ApplLinComAb_LIN2.VeLINR_d_PwrPanelCurrDrawSens1 <-> outer port VeLINR_d_PwrPanelCurrDrawSens1
    delegate ApplLinComAb_LIN2.VeLINR_b_PwrPanelCurrDrawSens1TO <-> outer port VeLINR_b_PwrPanelCurrDrawSens1TO
